VERSION ""

NS_ :

BS_:

BU_: ABS vDSU_FD_C vFD_C ECS RCU ICSC ESC RWS TPMS GW_RGW EPB FCU_C SAS EBB CGW_CCU MDPS RWA VPC_C BDC_C SFA

BO_ 234 MDPS_01_10ms: 24 SFA
 SG_ MDPS_Crc1Val : 0|16@1+ (1,0) [0|0] ""  CGW_CCU,ESC,ICSC,RCU,RWA,RWS,VPC_C
 SG_ MDPS_LoamModSta : 112|2@1+ (1,0) [0|0] ""  CGW_CCU,RWA
 SG_ MDPS_HDPSpprtSWVer : 114|5@1+ (1,0) [0|0] ""  CGW_CCU,RWA
 SG_ MDPS_ADASAciActvSta : 120|4@1+ (1,0) [0|0] ""  CGW_CCU,ESC,RWA,RWS
 SG_ MDPS_ADASAciPluginSta : 124|2@1+ (1,0) [0|0] ""  RWA
 SG_ MDPS_ADAS_AciFltSig : 126|2@1+ (1,0) [0|0] ""  CGW_CCU,ESC,RWA
 SG_ MDPS_EstStrAnglVal : 128|16@1- (0.1,0) [0|0] "Deg"  CGW_CCU,RWA,RWS
 SG_ MDPS_ADASAciActvSta_Lv2 : 144|4@1+ (1,0) [0|0] ""  CGW_CCU,RWA
 SG_ MDPS_ADAS_AciFltSig_Lv2 : 148|3@1+ (1,0) [0|0] ""  CGW_CCU,RWA
 SG_ MDPS_TpaPlugInSta : 152|2@1+ (1,0) [0|0] ""  RWA,VPC_C
 SG_ MDPS_TpaCanfltSta : 154|2@1+ (1,0) [0|0] ""  RWA,VPC_C
 SG_ MDPS_TpaModeSta : 156|4@1+ (1,0) [0|0] ""  RWA,VPC_C
 SG_ MDPS_AlvCnt1Val : 16|8@1+ (1,0) [0|0] ""  CGW_CCU,ESC,ICSC,RCU,RWA,RWS,VPC_C
 SG_ MDPS_TpaStrAnglVal : 160|16@1- (0.1,0) [0|0] "Deg"  RWA,VPC_C
 SG_ MDPS_WrngLmpSta : 24|3@1+ (1,0) [0|0] ""  CGW_CCU,ESC,ICSC,RCU,RWA,RWS
 SG_ MDPS_Typ : 27|3@1+ (1,0) [0|0] ""  CGW_CCU,ICSC,RWA
 SG_ MDPS_EngIdleRpmReq : 30|2@1+ (1,0) [0|0] ""  CGW_CCU,RWA
 SG_ MDPS_VsmPlgInSta : 32|2@1+ (1,0) [0|0] "flag"  ESC,ICSC,RCU,RWA
 SG_ MDPS_VsmDfctvSta : 34|2@1+ (1,0) [0|0] ""  ESC,ICSC,RCU,RWA
 SG_ MDPS_VsmSigErrSta : 36|2@1+ (1,0) [0|0] ""  ESC,RCU,RWA
 SG_ MDPS_PaPlugInSta : 38|2@1+ (1,0) [0|0] ""  CGW_CCU,ESC,RCU,RWA
 SG_ MDPS_PaModeSta : 40|4@1+ (1,0) [0|0] ""  CGW_CCU,RWA
 SG_ MDPS_PaCanfltSta : 44|2@1+ (1,0) [0|0] ""  CGW_CCU,RWA
 SG_ MDPS_LkaPlgInSta : 46|2@1+ (1,0) [0|0] ""  CGW_CCU,ICSC,RWA
 SG_ MDPS_LkaToiActvSta : 48|2@1+ (1,0) [0|0] ""  CGW_CCU,RWA
 SG_ MDPS_LkaToiUnblSta : 50|2@1+ (1,0) [0|0] ""  CGW_CCU,RWA
 SG_ MDPS_LkaToiFltSta : 52|2@1+ (1,0) [0|0] ""  CGW_CCU,RWA
 SG_ MDPS_LkaFailSta : 54|2@1+ (1,0) [0|0] ""  CGW_CCU,RWA
 SG_ MDPS_ResetOpSta : 59|2@1+ (1,0) [0|0] "" Vector__XXX
 SG_ MDPS_CurrModVal : 61|3@1+ (1,0) [0|0] ""  CGW_CCU,RWA
 SG_ MDPS_OutTqVal : 64|12@1+ (0.1,-204.8) [0|0] "Nm"  CGW_CCU,ESC,ICSC,RCU,RWA
 SG_ MDPS_VsmActResp : 76|2@1+ (1,0) [0|0] ""  ESC,RCU,RWA
 SG_ Reprogram_State_MDPS : 78|2@1+ (1,0) [0|0] ""  CGW_CCU
 SG_ MDPS_StrTqSnsrVal : 80|13@1+ (0.005,-20.48) [0|0] "Nm"  CGW_CCU,ESC,ICSC,RCU,RWA,VPC_C
 SG_ MDPS_PaStrAnglVal : 96|16@1- (0.1,0) [0|0] "Deg"  CGW_CCU,RWA

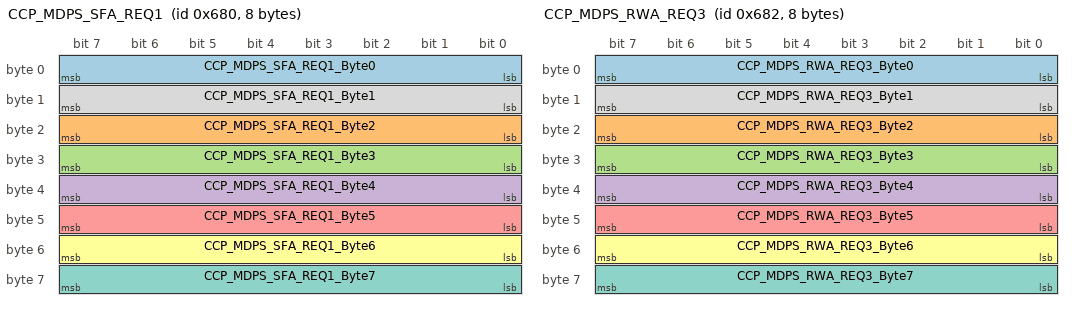
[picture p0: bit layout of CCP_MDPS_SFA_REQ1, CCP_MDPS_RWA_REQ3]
BO_ 1664 CCP_MDPS_SFA_REQ1: 8 CGW_CCU
 SG_ CCP_MDPS_SFA_REQ1_Byte0 : 0|8@1+ (1,0) [0|0] ""  GW_RGW,MDPS,SFA
 SG_ CCP_MDPS_SFA_REQ1_Byte2 : 16|8@1+ (1,0) [0|0] ""  GW_RGW,MDPS,SFA
 SG_ CCP_MDPS_SFA_REQ1_Byte3 : 24|8@1+ (1,0) [0|0] ""  GW_RGW,MDPS,SFA
 SG_ CCP_MDPS_SFA_REQ1_Byte4 : 32|8@1+ (1,0) [0|0] ""  GW_RGW,MDPS,SFA
 SG_ CCP_MDPS_SFA_REQ1_Byte5 : 40|8@1+ (1,0) [0|0] ""  GW_RGW,MDPS,SFA
 SG_ CCP_MDPS_SFA_REQ1_Byte6 : 48|8@1+ (1,0) [0|0] ""  GW_RGW,MDPS,SFA
 SG_ CCP_MDPS_SFA_REQ1_Byte7 : 56|8@1+ (1,0) [0|0] ""  GW_RGW,MDPS,SFA
 SG_ CCP_MDPS_SFA_REQ1_Byte1 : 8|8@1+ (1,0) [0|0] ""  GW_RGW,MDPS,SFA

BO_ 1666 CCP_MDPS_RWA_REQ3: 8 CGW_CCU
 SG_ CCP_MDPS_RWA_REQ3_Byte0 : 0|8@1+ (1,0) [0|0] ""  GW_RGW,MDPS,RWA
 SG_ CCP_MDPS_RWA_REQ3_Byte2 : 16|8@1+ (1,0) [0|0] ""  GW_RGW,MDPS,RWA
 SG_ CCP_MDPS_RWA_REQ3_Byte3 : 24|8@1+ (1,0) [0|0] ""  GW_RGW,MDPS,RWA
 SG_ CCP_MDPS_RWA_REQ3_Byte4 : 32|8@1+ (1,0) [0|0] ""  GW_RGW,MDPS,RWA
 SG_ CCP_MDPS_RWA_REQ3_Byte5 : 40|8@1+ (1,0) [0|0] ""  GW_RGW,MDPS,RWA
 SG_ CCP_MDPS_RWA_REQ3_Byte6 : 48|8@1+ (1,0) [0|0] ""  GW_RGW,MDPS,RWA
 SG_ CCP_MDPS_RWA_REQ3_Byte7 : 56|8@1+ (1,0) [0|0] ""  GW_RGW,MDPS,RWA
 SG_ CCP_MDPS_RWA_REQ3_Byte1 : 8|8@1+ (1,0) [0|0] ""  GW_RGW,MDPS,RWA

BO_ 266 MCU_01_10ms: 32 CGW_CCU
 SG_ MCU_Crc1Val : 0|16@1+ (1,0) [0|0] ""  MDPS,SFA
 SG_ MCU_AlvCnt1Val : 16|8@1+ (1,0) [0|0] ""  MDPS,SFA
 SG_ MCU_Mg1EstTqVal : 192|14@1- (0.125,0) [0|0] "Nm"  ECS,EPB,MDPS,SFA

BO_ 813 SBCM_DRV_FD_01_200ms: 32 CGW_CCU
 SG_ SBCM_DRV_FD_Crc1Val : 0|16@1+ (1,0) [0|0] ""  GW_RGW,RWA,RWS,SFA
 SG_ SBCM_DRV_FD_AlvCnt1Val : 16|8@1+ (1,0) [0|0] ""  GW_RGW,RWA,RWS,SFA
 SG_ Warn_DrvDrSwSta_SBCM : 84|2@1+ (1,0) [0|0] ""  ECS,EPB,ESC,GW_RGW,RCU,RWA,SFA

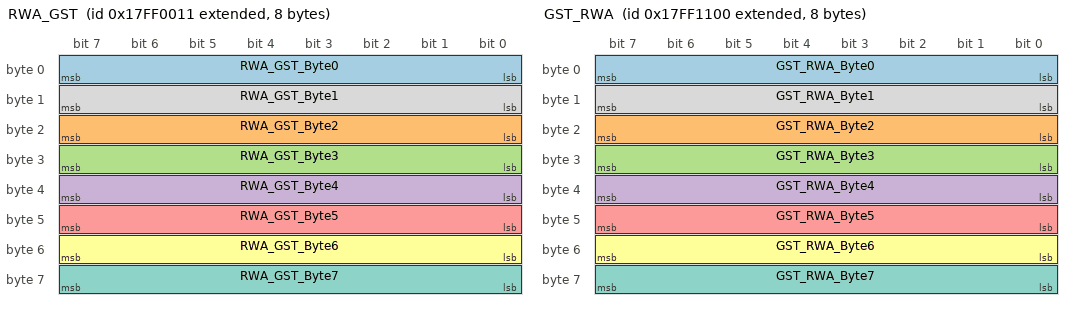
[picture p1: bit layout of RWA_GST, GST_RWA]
BO_ 2550071313 RWA_GST: 8 RWA
 SG_ RWA_GST_Byte0 : 0|8@1+ (1,0) [0|0] ""  CGW_CCU
 SG_ RWA_GST_Byte2 : 16|8@1+ (1,0) [0|0] ""  CGW_CCU
 SG_ RWA_GST_Byte3 : 24|8@1+ (1,0) [0|0] ""  CGW_CCU
 SG_ RWA_GST_Byte4 : 32|8@1+ (1,0) [0|0] ""  CGW_CCU
 SG_ RWA_GST_Byte5 : 40|8@1+ (1,0) [0|0] ""  CGW_CCU
 SG_ RWA_GST_Byte6 : 48|8@1+ (1,0) [0|0] ""  CGW_CCU
 SG_ RWA_GST_Byte7 : 56|8@1+ (1,0) [0|0] ""  CGW_CCU
 SG_ RWA_GST_Byte1 : 8|8@1+ (1,0) [0|0] ""  CGW_CCU

BO_ 811 SBCM_AST_FD_01_200ms: 32 CGW_CCU
 SG_ SBCM_AST_FD_Crc1Val : 0|16@1+ (1,0) [0|0] ""  GW_RGW,RWA,SFA
 SG_ SBCM_AST_FD_AlvCnt1Val : 16|8@1+ (1,0) [0|0] ""  GW_RGW,RWA,SFA
 SG_ Warn_AsstDrSwSta_SBCM : 84|2@1+ (1,0) [0|0] ""  ECS,GW_RGW,RWA,SFA

BO_ 288 MCU_02_10ms: 32 CGW_CCU
 SG_ MCU_Crc2Val : 0|16@1+ (1,0) [0|0] ""  SFA
 SG_ MCU_AlvCnt2Val : 16|8@1+ (1,0) [0|0] ""  SFA
 SG_ MCU_Mg2EstTqVal : 192|14@1- (0.125,0) [0|0] "Nm"  ECS,MDPS,SFA
 SG_ MCU_Mg2EstTqPcVal : 40|10@1- (0.1953125,0) [0|0] "%"  MDPS,SFA

BO_ 293 SAS_01_10ms: 16 SAS
 SG_ SAS_Crc1Val : 0|16@1+ (1,0) [0|0] ""  ABS,CGW_CCU,ECS,ESC,FCU_C,GW_RGW,ICSC,MDPS,RCU,RWA,RWS,VPC_C
 SG_ SAS_AlvCnt1Val : 16|8@1+ (1,0) [0|0] ""  ABS,CGW_CCU,ECS,ESC,FCU_C,GW_RGW,ICSC,MDPS,RCU,RWA,RWS,VPC_C
 SG_ SAS_AnglVal : 24|16@1- (0.1,0) [0|0] "Deg"  ABS,CGW_CCU,ECS,ESC,FCU_C,GW_RGW,ICSC,MDPS,RCU,RWA,RWS,VPC_C
 SG_ SAS_SpdVal : 40|8@1+ (4,0) [0|0] "Deg/s"  ABS,CGW_CCU,ECS,ESC,FCU_C,GW_RGW,ICSC,MDPS,RCU,RWA,VPC_C
 SG_ SAS_IntSta : 48|8@1+ (1,0) [0|0] ""  ABS,CGW_CCU,ECS,ESC,FCU_C,GW_RGW,MDPS,RCU,RWA,RWS,VPC_C

BO_ 2550075648 GST_RWA: 8 CGW_CCU
 SG_ GST_RWA_Byte0 : 0|8@1+ (1,0) [0|0] ""  RWA
 SG_ GST_RWA_Byte2 : 16|8@1+ (1,0) [0|0] ""  RWA
 SG_ GST_RWA_Byte3 : 24|8@1+ (1,0) [0|0] ""  RWA
 SG_ GST_RWA_Byte4 : 32|8@1+ (1,0) [0|0] ""  RWA
 SG_ GST_RWA_Byte5 : 40|8@1+ (1,0) [0|0] ""  RWA
 SG_ GST_RWA_Byte6 : 48|8@1+ (1,0) [0|0] ""  RWA
 SG_ GST_RWA_Byte7 : 56|8@1+ (1,0) [0|0] ""  RWA
 SG_ GST_RWA_Byte1 : 8|8@1+ (1,0) [0|0] ""  RWA

BO_ 298 ADAS_CMD_30_10ms: 16 CGW_CCU
 SG_ ADAS_CMD_Crc30Val : 0|16@1+ (1,0) [0|0] ""  FCU_C,GW_RGW,ICSC,MDPS,RWS,SFA,VPC_C
 SG_ ADAS_Damping_Gain : 104|8@1+ (1,0) [0|0] ""  GW_RGW,MDPS,SFA
 SG_ ADAS_CMD_AlvCnt30Val : 16|8@1+ (1,0) [0|0] ""  FCU_C,GW_RGW,ICSC,MDPS,RWS,SFA,VPC_C
 SG_ ADAS_StrTqReqVal : 41|11@1+ (0.0078125,-8) [0|0] "Nm"  GW_RGW,ICSC,MDPS,SFA
 SG_ ADAS_ActToiSta : 52|2@1+ (1,0) [0|0] ""  ESC,GW_RGW,ICSC,MDPS,RWS,SFA
 SG_ ADAS_ToiFltSta : 54|2@1+ (1,0) [0|0] ""  GW_RGW,MDPS,RWS,SFA

BO_ 374 RCU_03_20ms: 32 RCU
 SG_ RCU_Crc3Val : 0|16@1+ (1,0) [0|0] ""  CGW_CCU,GW_RGW,MDPS,SFA
 SG_ RCU_AlvCnt3Val : 16|8@1+ (1,0) [0|0] ""  CGW_CCU,GW_RGW,MDPS,SFA
 SG_ RCU_HDP_EgSta : 27|3@1+ (1,0) [0|0] ""  CGW_CCU,ESC,GW_RGW,MDPS,SFA,VPC_C

BO_ 357 ADAS_PRK_20_20ms: 24 CGW_CCU
 SG_ ADAS_PRK_Crc2Val : 0|16@1+ (1,0) [0|0] ""  GW_RGW,MDPS,RWS,SFA
 SG_ ADAS_PRK_AlvCnt2Val : 16|8@1+ (1,0) [0|0] ""  GW_RGW,MDPS,RWS,SFA
 SG_ PA_RSPA_Opt : 30|2@1+ (1,0) [0|0] ""  GW_RGW,MDPS,SFA
 SG_ PA_Sta : 90|4@1+ (1,0) [0|0] ""  ESC,GW_RGW,MDPS,RCU,RWS,SFA
 SG_ PA_TestModSta : 94|2@1+ (1,0) [0|0] ""  GW_RGW,MDPS,SFA
 SG_ PA_StrAnglReq : 96|16@1- (0.1,0) [0|0] ""  GW_RGW,MDPS,SFA

BO_ 358 CDCU_TPA_01_20ms: 16 VPC_C
 SG_ CDCU_TPA_Crc1Val : 0|16@1+ (1,0) [0|0] ""  ESC,GW_RGW,MDPS,RWS,SFA
 SG_ CDCU_TPA_AlvCnt1Val : 16|8@1+ (1,0) [0|0] ""  ESC,GW_RGW,MDPS,RWS,SFA
 SG_ CDCU_TPA_Opt : 24|2@1+ (1,0) [0|0] ""  ESC,GW_RGW,MDPS,RWS,SFA
 SG_ CDCU_TPA_Sta : 26|4@1+ (1,0) [0|0] ""  ESC,GW_RGW,MDPS,RWS,SFA
 SG_ CDCU_TPA_StrAnglReq : 30|16@1- (0.1,0) [0|0] ""  GW_RGW,MDPS,RWS,SFA

BO_ 405 ADAS_CMD_33_10ms: 32 GW_RGW
 SG_ ADAS_CMD_Crc33Val : 0|16@1+ (1,0) [0|0] ""  CGW_CCU,SFA
 SG_ HDP_RDD_StrAnglReqVal : 112|14@1- (0.1,0) [0|0] ""  SFA
 SG_ ADAS_CMD_AlvCnt33Val : 16|8@1+ (1,0) [0|0] ""  CGW_CCU,SFA
 SG_ HDP_RDD_ACIAnglTqRedcGainVal : 24|8@1+ (0.004,0) [0|0] ""  SFA
 SG_ HDP_RDD_ACIFltSta : 88|2@1+ (1,0) [0|0] ""  SFA
 SG_ HDP_RDD_ACIActvSta : 96|4@1+ (1,0) [0|0] ""  SFA

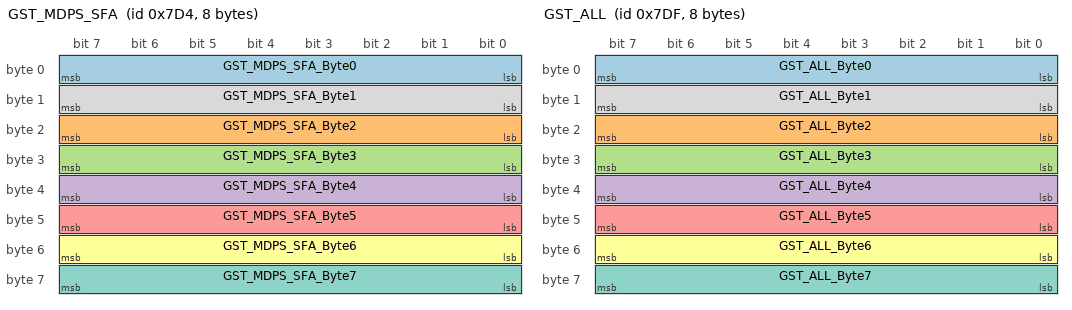
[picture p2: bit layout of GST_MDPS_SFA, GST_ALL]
BO_ 2004 GST_MDPS_SFA: 8 CGW_CCU
 SG_ GST_MDPS_SFA_Byte0 : 0|8@1+ (1,0) [0|0] ""  MDPS,SFA
 SG_ GST_MDPS_SFA_Byte2 : 16|8@1+ (1,0) [0|0] ""  MDPS,SFA
 SG_ GST_MDPS_SFA_Byte3 : 24|8@1+ (1,0) [0|0] ""  MDPS,SFA
 SG_ GST_MDPS_SFA_Byte4 : 32|8@1+ (1,0) [0|0] ""  MDPS,SFA
 SG_ GST_MDPS_SFA_Byte5 : 40|8@1+ (1,0) [0|0] ""  MDPS,SFA
 SG_ GST_MDPS_SFA_Byte6 : 48|8@1+ (1,0) [0|0] ""  MDPS,SFA
 SG_ GST_MDPS_SFA_Byte7 : 56|8@1+ (1,0) [0|0] ""  MDPS,SFA
 SG_ GST_MDPS_SFA_Byte1 : 8|8@1+ (1,0) [0|0] ""  MDPS,SFA

BO_ 2015 GST_ALL: 8 CGW_CCU
 SG_ GST_ALL_Byte0 : 0|8@1+ (1,0) [0|0] ""  ABS,EBB,ECS,EPB,ESC,GW_RGW,ICSC,MDPS,RCU,RWA,RWS,SAS,SFA,TPMS
 SG_ GST_ALL_Byte2 : 16|8@1+ (1,0) [0|0] ""  ABS,EBB,ECS,EPB,ESC,GW_RGW,ICSC,MDPS,RCU,RWA,RWS,SAS,SFA,TPMS
 SG_ GST_ALL_Byte3 : 24|8@1+ (1,0) [0|0] ""  ABS,EBB,ECS,EPB,ESC,GW_RGW,ICSC,MDPS,RCU,RWA,RWS,SAS,SFA,TPMS
 SG_ GST_ALL_Byte4 : 32|8@1+ (1,0) [0|0] ""  ABS,EBB,ECS,EPB,ESC,GW_RGW,ICSC,MDPS,RCU,RWA,RWS,SAS,SFA,TPMS
 SG_ GST_ALL_Byte5 : 40|8@1+ (1,0) [0|0] ""  ABS,EBB,ECS,EPB,ESC,GW_RGW,ICSC,MDPS,RCU,RWA,RWS,SAS,SFA,TPMS
 SG_ GST_ALL_Byte6 : 48|8@1+ (1,0) [0|0] ""  ABS,EBB,ECS,EPB,ESC,GW_RGW,ICSC,MDPS,RCU,RWA,RWS,SAS,SFA,TPMS
 SG_ GST_ALL_Byte7 : 56|8@1+ (1,0) [0|0] ""  ABS,EBB,ECS,EPB,ESC,GW_RGW,ICSC,MDPS,RCU,RWA,RWS,SAS,SFA,TPMS
 SG_ GST_ALL_Byte1 : 8|8@1+ (1,0) [0|0] ""  ABS,EBB,ECS,EPB,ESC,GW_RGW,ICSC,MDPS,RCU,RWA,RWS,SAS,SFA,TPMS

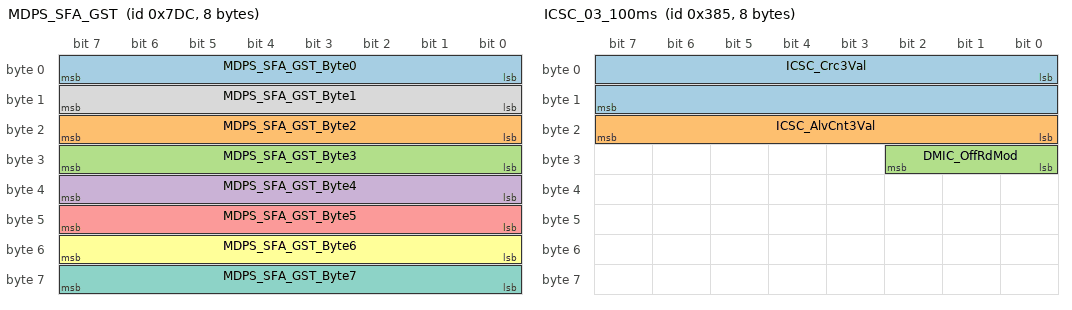
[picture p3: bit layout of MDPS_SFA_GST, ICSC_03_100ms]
BO_ 2012 MDPS_SFA_GST: 8 SFA
 SG_ MDPS_SFA_GST_Byte0 : 0|8@1+ (1,0) [0|0] ""  CGW_CCU
 SG_ MDPS_SFA_GST_Byte2 : 16|8@1+ (1,0) [0|0] ""  CGW_CCU
 SG_ MDPS_SFA_GST_Byte3 : 24|8@1+ (1,0) [0|0] ""  CGW_CCU
 SG_ MDPS_SFA_GST_Byte4 : 32|8@1+ (1,0) [0|0] ""  CGW_CCU
 SG_ MDPS_SFA_GST_Byte5 : 40|8@1+ (1,0) [0|0] ""  CGW_CCU
 SG_ MDPS_SFA_GST_Byte6 : 48|8@1+ (1,0) [0|0] ""  CGW_CCU
 SG_ MDPS_SFA_GST_Byte7 : 56|8@1+ (1,0) [0|0] ""  CGW_CCU
 SG_ MDPS_SFA_GST_Byte1 : 8|8@1+ (1,0) [0|0] ""  CGW_CCU

BO_ 426 CLU_01_20ms: 16 CGW_CCU
 SG_ CLU_Crc1Val : 0|16@1+ (1,0) [0|0] ""  ESC,GW_RGW,MDPS,RCU,RWA,SFA,VPC_C
 SG_ CLU_AlvCnt1Val : 16|8@1+ (1,0) [0|0] ""  EPB,ESC,GW_RGW,MDPS,RCU,RWA,SFA,VPC_C
 SG_ CLU_SpdUnitTyp : 30|2@1+ (1,0) [0|0] ""  ECS,ESC,GW_RGW,MDPS,RCU,RWA,SFA,VPC_C
 SG_ CLU_DisSpdVal : 48|10@1+ (0.5,0) [0|0] "km/h or MPH"  ECS,GW_RGW,MDPS,RWA,SFA,VPC_C

BO_ 901 ICSC_03_100ms: 8 ESC
 SG_ ICSC_Crc3Val : 0|16@1+ (1,0) [0|0] ""  CGW_CCU,GW_RGW,MDPS,SFA,VPC_C
 SG_ ICSC_AlvCnt3Val : 16|8@1+ (1,0) [0|0] ""  CGW_CCU,GW_RGW,MDPS,SFA,VPC_C
 SG_ DMIC_OffRdMod : 24|3@1+ (1,0) [0|0] ""  CGW_CCU,ECS,GW_RGW,MDPS,SFA,VPC_C

BO_ 994 PDC_FD_03_200ms: 16 CGW_CCU
 SG_ PDC_FD_Crc3Val : 0|16@1+ (1,0) [0|0] ""  GW_RGW,RWA,SFA
 SG_ PDC_FD_AlvCnt3Val : 16|8@1+ (1,0) [0|0] ""  GW_RGW,RWA,SFA
 SG_ Warn_DrvDrSwSta : 64|2@1+ (1,0) [0|0] ""  EPB,ESC,GW_RGW,RCU,RWA,SFA
 SG_ Warn_AsstDrSwSta : 66|2@1+ (1,0) [0|0] ""  GW_RGW,RWA,SFA
 SG_ DoorLock_DrvDrUnLkSta : 74|2@1+ (1,0) [0|0] ""  ESC,GW_RGW,RCU,RWA,SFA

BO_ 2549874807 NM_ECS: 32 ECS
 SG_ SNI_ECS : 0|8@1+ (1,0) [0|0] ""  CGW_CCU,EBB,ESC,GW_RGW,MDPS,RCU,RWA,RWS,SFA
 SG_ CBV_RMR_ECS : 8|1@1+ (1,0) [0|0] ""  CGW_CCU,EBB,ESC,GW_RGW,MDPS,RCU,RWA,RWS,SFA
 SG_ CBV_NMCoID_ECS : 9|2@1+ (1,0) [0|0] ""  CGW_CCU,EBB,ESC,GW_RGW,MDPS,RCU,RWA,RWS,SFA
 SG_ CBV_NMCoSRB_ECS : 11|1@1+ (1,0) [0|0] ""  CGW_CCU,EBB,ESC,GW_RGW,MDPS,RCU,RWA,RWS,SFA
 SG_ CBV_AWB_ECS : 12|1@1+ (1,0) [0|0] ""  CGW_CCU,EBB,ESC,GW_RGW,MDPS,RCU,RWA,RWS,SFA
 SG_ CBV_PNIB_ECS : 14|1@1+ (1,0) [0|0] ""  CGW_CCU,EBB,ESC,GW_RGW,MDPS,RCU,RWA,RWS,SFA
 SG_ NRR_ECS : 16|8@1+ (1,0) [0|0] ""  CGW_CCU,EBB,ESC,GW_RGW,MDPS,RCU,RWA,RWS,SFA
 SG_ NM_State_ECS : 24|8@1+ (1,0) [0|0] ""  CGW_CCU,EBB,ESC,GW_RGW,MDPS,RCU,RWA,RWS,SFA
 SG_ PNI_ECS : 32|32@1+ (1,0) [0|0] ""  CGW_CCU,EBB,ESC,GW_RGW,MDPS,RCU,RWA,RWS,SFA
 SG_ PNI_ECS_1 : 64|64@1+ (1,0) [0|0] ""  CGW_CCU,EBB,ESC,GW_RGW,MDPS,RCU,RWA,RWS,SFA
 SG_ PNI_ECS_2 : 128|64@1+ (1,0) [0|0] ""  CGW_CCU,EBB,ESC,GW_RGW,MDPS,RCU,RWA,RWS,SFA
 SG_ PNI_ECS_3 : 192|64@1+ (1,0) [0|0] ""  CGW_CCU,EBB,ESC,GW_RGW,MDPS,RCU,RWA,RWS,SFA

BO_ 2549874769 NM_RCU: 32 RCU
 SG_ SNI_RCU : 0|8@1+ (1,0) [0|0] ""  CGW_CCU,EBB,ECS,ESC,GW_RGW,MDPS,RWA,RWS,SFA
 SG_ CBV_RMR_RCU : 8|1@1+ (1,0) [0|0] ""  CGW_CCU,EBB,ECS,ESC,GW_RGW,MDPS,RWA,RWS,SFA
 SG_ CBV_NMCoID_RCU : 9|2@1+ (1,0) [0|0] ""  CGW_CCU,EBB,ECS,ESC,GW_RGW,MDPS,RWA,RWS,SFA
 SG_ CBV_NMCoSRB_RCU : 11|1@1+ (1,0) [0|0] ""  CGW_CCU,EBB,ECS,ESC,GW_RGW,MDPS,RWA,RWS,SFA
 SG_ CBV_AWB_RCU : 12|1@1+ (1,0) [0|0] ""  CGW_CCU,EBB,ECS,ESC,GW_RGW,MDPS,RWA,RWS,SFA
 SG_ CBV_PNIB_RCU : 14|1@1+ (1,0) [0|0] ""  CGW_CCU,EBB,ECS,ESC,GW_RGW,MDPS,RWA,RWS,SFA
 SG_ NRR_RCU : 16|8@1+ (1,0) [0|0] ""  CGW_CCU,EBB,ECS,ESC,GW_RGW,MDPS,RWA,RWS,SFA
 SG_ NM_State_RCU : 24|8@1+ (1,0) [0|0] ""  CGW_CCU,EBB,ECS,ESC,GW_RGW,MDPS,RWA,RWS,SFA
 SG_ PNI_RCU : 32|32@1+ (1,0) [0|0] ""  CGW_CCU,EBB,ECS,ESC,GW_RGW,MDPS,RWA,RWS,SFA
 SG_ PNI_RCU_1 : 64|64@1+ (1,0) [0|0] ""  CGW_CCU,EBB,ECS,ESC,GW_RGW,MDPS,RWA,RWS,SFA
 SG_ PNI_RCU_2 : 128|64@1+ (1,0) [0|0] ""  CGW_CCU,EBB,ECS,ESC,GW_RGW,MDPS,RWA,RWS,SFA
 SG_ PNI_RCU_3 : 192|64@1+ (1,0) [0|0] ""  CGW_CCU,EBB,ECS,ESC,GW_RGW,MDPS,RWA,RWS,SFA

BO_ 2549874805 NM_ESC: 32 ESC
 SG_ SNI_ESC : 0|8@1+ (1,0) [0|0] ""  CGW_CCU,EBB,ECS,GW_RGW,MDPS,RCU,RWA,RWS,SFA
 SG_ CBV_RMR_ESC : 8|1@1+ (1,0) [0|0] ""  CGW_CCU,EBB,ECS,GW_RGW,MDPS,RCU,RWA,RWS,SFA
 SG_ CBV_NMCoID_ESC : 9|2@1+ (1,0) [0|0] ""  CGW_CCU,EBB,ECS,GW_RGW,MDPS,RCU,RWA,RWS,SFA
 SG_ CBV_NMCoSRB_ESC : 11|1@1+ (1,0) [0|0] ""  CGW_CCU,EBB,ECS,GW_RGW,MDPS,RCU,RWA,RWS,SFA
 SG_ CBV_AWB_ESC : 12|1@1+ (1,0) [0|0] ""  CGW_CCU,EBB,ECS,GW_RGW,MDPS,RCU,RWA,RWS,SFA
 SG_ CBV_PNIB_ESC : 14|1@1+ (1,0) [0|0] ""  CGW_CCU,EBB,ECS,GW_RGW,MDPS,RCU,RWA,RWS,SFA
 SG_ NRR_ESC : 16|8@1+ (1,0) [0|0] ""  CGW_CCU,EBB,ECS,GW_RGW,MDPS,RCU,RWA,RWS,SFA
 SG_ NM_State_ESC : 24|8@1+ (1,0) [0|0] ""  CGW_CCU,EBB,ECS,GW_RGW,MDPS,RCU,RWA,RWS,SFA
 SG_ PNI_ESC : 32|32@1+ (1,0) [0|0] ""  CGW_CCU,EBB,ECS,GW_RGW,MDPS,RCU,RWA,RWS,SFA
 SG_ PNI_ESC_1 : 64|64@1+ (1,0) [0|0] ""  CGW_CCU,EBB,ECS,GW_RGW,MDPS,RCU,RWA,RWS,SFA
 SG_ PNI_ESC_2 : 128|64@1+ (1,0) [0|0] ""  CGW_CCU,EBB,ECS,GW_RGW,MDPS,RCU,RWA,RWS,SFA
 SG_ PNI_ESC_3 : 192|64@1+ (1,0) [0|0] ""  CGW_CCU,EBB,ECS,GW_RGW,MDPS,RCU,RWA,RWS,SFA

BO_ 2549874809 NM_RWS: 32 RWS
 SG_ SNI_RWS : 0|8@1+ (1,0) [0|0] ""  CGW_CCU,EBB,ECS,ESC,GW_RGW,MDPS,RCU,RWA,SFA
 SG_ CBV_RMR_RWS : 8|1@1+ (1,0) [0|0] ""  CGW_CCU,EBB,ECS,ESC,GW_RGW,MDPS,RCU,RWA,SFA
 SG_ CBV_NMCoID_RWS : 9|2@1+ (1,0) [0|0] ""  CGW_CCU,EBB,ECS,ESC,GW_RGW,MDPS,RCU,RWA,SFA
 SG_ CBV_NMCoSRB_RWS : 11|1@1+ (1,0) [0|0] ""  CGW_CCU,EBB,ECS,ESC,GW_RGW,MDPS,RCU,RWA,SFA
 SG_ CBV_AWB_RWS : 12|1@1+ (1,0) [0|0] ""  CGW_CCU,EBB,ECS,ESC,GW_RGW,MDPS,RCU,RWA,SFA
 SG_ CBV_PNIB_RWS : 14|1@1+ (1,0) [0|0] ""  CGW_CCU,EBB,ECS,ESC,GW_RGW,MDPS,RCU,RWA,SFA
 SG_ NRR_RWS : 16|8@1+ (1,0) [0|0] ""  CGW_CCU,EBB,ECS,ESC,GW_RGW,MDPS,RCU,RWA,SFA
 SG_ NM_State_RWS : 24|8@1+ (1,0) [0|0] ""  CGW_CCU,EBB,ECS,ESC,GW_RGW,MDPS,RCU,RWA,SFA
 SG_ PNI_RWS : 32|32@1+ (1,0) [0|0] ""  CGW_CCU,EBB,ECS,ESC,GW_RGW,MDPS,RCU,RWA,SFA
 SG_ PNI_RWS_1 : 64|64@1+ (1,0) [0|0] ""  CGW_CCU,EBB,ECS,ESC,GW_RGW,MDPS,RCU,RWA,SFA
 SG_ PNI_RWS_2 : 128|64@1+ (1,0) [0|0] ""  CGW_CCU,EBB,ECS,ESC,GW_RGW,MDPS,RCU,RWA,SFA
 SG_ PNI_RWS_3 : 192|64@1+ (1,0) [0|0] ""  CGW_CCU,EBB,ECS,ESC,GW_RGW,MDPS,RCU,RWA,SFA

BO_ 2549874751 NM_GW_RGW: 32 GW_RGW
 SG_ SNI_GW_RGW : 0|8@1+ (1,0) [0|0] ""  CGW_CCU,EBB,ECS,ESC,MDPS,RCU,RWA,RWS,SFA
 SG_ CBV_RMR_GW_RGW : 8|1@1+ (1,0) [0|0] ""  CGW_CCU,EBB,ECS,ESC,MDPS,RCU,RWA,RWS,SFA
 SG_ CBV_NMCoID_GW_RGW : 9|2@1+ (1,0) [0|0] ""  CGW_CCU,EBB,ECS,ESC,MDPS,RCU,RWA,RWS,SFA
 SG_ CBV_NMCoSRB_GW_RGW : 11|1@1+ (1,0) [0|0] ""  CGW_CCU,EBB,ECS,ESC,MDPS,RCU,RWA,RWS,SFA
 SG_ CBV_AWB_GW_RGW : 12|1@1+ (1,0) [0|0] ""  CGW_CCU,EBB,ECS,ESC,MDPS,RCU,RWA,RWS,SFA
 SG_ CBV_PNIB_GW_RGW : 14|1@1+ (1,0) [0|0] ""  CGW_CCU,EBB,ECS,ESC,MDPS,RCU,RWA,RWS,SFA
 SG_ NRR_GW_RGW : 16|8@1+ (1,0) [0|0] ""  CGW_CCU,EBB,ECS,ESC,MDPS,RCU,RWA,RWS,SFA
 SG_ NM_State_GW_RGW : 24|8@1+ (1,0) [0|0] ""  CGW_CCU,EBB,ECS,ESC,MDPS,RCU,RWA,RWS,SFA
 SG_ PNI_GW_RGW : 32|32@1+ (1,0) [0|0] ""  CGW_CCU,EBB,ECS,ESC,MDPS,RCU,RWA,RWS,SFA
 SG_ PNI_GW_RGW_1 : 64|64@1+ (1,0) [0|0] ""  CGW_CCU,EBB,ECS,ESC,MDPS,RCU,RWA,RWS,SFA
 SG_ PNI_GW_RGW_2 : 128|64@1+ (1,0) [0|0] ""  CGW_CCU,EBB,ECS,ESC,MDPS,RCU,RWA,RWS,SFA
 SG_ PNI_GW_RGW_3 : 192|64@1+ (1,0) [0|0] ""  CGW_CCU,EBB,ECS,ESC,MDPS,RCU,RWA,RWS,SFA

BO_ 2549874786 NM_EBB: 32 EBB
 SG_ SNI_EBB : 0|8@1+ (1,0) [0|0] ""  CGW_CCU,ECS,ESC,GW_RGW,MDPS,RCU,RWA,RWS,SFA
 SG_ CBV_RMR_EBB : 8|1@1+ (1,0) [0|0] ""  CGW_CCU,ECS,ESC,GW_RGW,MDPS,RCU,RWA,RWS,SFA
 SG_ CBV_NMCoID_EBB : 9|2@1+ (1,0) [0|0] ""  CGW_CCU,ECS,ESC,GW_RGW,MDPS,RCU,RWA,RWS,SFA
 SG_ CBV_NMCoSRB_EBB : 11|1@1+ (1,0) [0|0] ""  CGW_CCU,ECS,ESC,GW_RGW,MDPS,RCU,RWA,RWS,SFA
 SG_ CBV_AWB_EBB : 12|1@1+ (1,0) [0|0] ""  CGW_CCU,ECS,ESC,GW_RGW,MDPS,RCU,RWA,RWS,SFA
 SG_ CBV_PNIB_EBB : 14|1@1+ (1,0) [0|0] ""  CGW_CCU,ECS,ESC,GW_RGW,MDPS,RCU,RWA,RWS,SFA
 SG_ NRR_EBB : 16|8@1+ (1,0) [0|0] ""  CGW_CCU,ECS,ESC,GW_RGW,MDPS,RCU,RWA,RWS,SFA
 SG_ NM_State_EBB : 24|8@1+ (1,0) [0|0] ""  CGW_CCU,ECS,ESC,GW_RGW,MDPS,RCU,RWA,RWS,SFA
 SG_ PNI_EBB : 32|32@1+ (1,0) [0|0] ""  CGW_CCU,ECS,ESC,GW_RGW,MDPS,RCU,RWA,RWS,SFA
 SG_ PNI_EBB_1 : 64|64@1+ (1,0) [0|0] ""  CGW_CCU,ECS,ESC,GW_RGW,MDPS,RCU,RWA,RWS,SFA
 SG_ PNI_EBB_2 : 128|64@1+ (1,0) [0|0] ""  CGW_CCU,ECS,ESC,GW_RGW,MDPS,RCU,RWA,RWS,SFA
 SG_ PNI_EBB_3 : 192|64@1+ (1,0) [0|0] ""  CGW_CCU,ECS,ESC,GW_RGW,MDPS,RCU,RWA,RWS,SFA

BO_ 2549874800 NM_CGW_CCU: 32 CGW_CCU
 SG_ SNI_CGW_CCU : 0|8@1+ (1,0) [0|0] ""  EBB,ECS,ESC,GW_RGW,MDPS,RCU,RWA,RWS,SFA
 SG_ CBV_RMR_CGW_CCU : 8|1@1+ (1,0) [0|0] ""  EBB,ECS,ESC,GW_RGW,MDPS,RCU,RWA,RWS,SFA
 SG_ CBV_NMCoID_CGW_CCU : 9|2@1+ (1,0) [0|0] ""  EBB,ECS,ESC,GW_RGW,MDPS,RCU,RWA,RWS,SFA
 SG_ CBV_NMCoSRB_CGW_CCU : 11|1@1+ (1,0) [0|0] ""  EBB,ECS,ESC,GW_RGW,MDPS,RCU,RWA,RWS,SFA
 SG_ CBV_AWB_CGW_CCU : 12|1@1+ (1,0) [0|0] ""  EBB,ECS,ESC,GW_RGW,MDPS,RCU,RWA,RWS,SFA
 SG_ CBV_PNIB_CGW_CCU : 14|1@1+ (1,0) [0|0] ""  EBB,ECS,ESC,GW_RGW,MDPS,RCU,RWA,RWS,SFA
 SG_ NRR_CGW_CCU : 16|8@1+ (1,0) [0|0] ""  EBB,ECS,ESC,GW_RGW,MDPS,RCU,RWA,RWS,SFA
 SG_ NM_State_CGW_CCU : 24|8@1+ (1,0) [0|0] ""  EBB,ECS,ESC,GW_RGW,MDPS,RCU,RWA,RWS,SFA
 SG_ PNI_CGW_CCU : 32|32@1+ (1,0) [0|0] ""  EBB,ECS,ESC,GW_RGW,MDPS,RCU,RWA,RWS,SFA
 SG_ PNI_CGW_CCU_1 : 64|64@1+ (1,0) [0|0] ""  EBB,ECS,ESC,GW_RGW,MDPS,RCU,RWA,RWS,SFA
 SG_ PNI_CGW_CCU_2 : 128|64@1+ (1,0) [0|0] ""  EBB,ECS,ESC,GW_RGW,MDPS,RCU,RWA,RWS,SFA
 SG_ PNI_CGW_CCU_3 : 192|64@1+ (1,0) [0|0] ""  EBB,ECS,ESC,GW_RGW,MDPS,RCU,RWA,RWS,SFA

BO_ 2549874806 NM_MDPS: 32 MDPS
 SG_ SNI_MDPS : 0|8@1+ (1,0) [0|0] ""  CGW_CCU,EBB,ECS,ESC,GW_RGW,RCU,RWA,RWS,SFA
 SG_ CBV_RMR_MDPS : 8|1@1+ (1,0) [0|0] ""  CGW_CCU,EBB,ECS,ESC,GW_RGW,RCU,RWA,RWS,SFA
 SG_ CBV_NMCoID_MDPS : 9|2@1+ (1,0) [0|0] ""  CGW_CCU,EBB,ECS,ESC,GW_RGW,RCU,RWA,RWS,SFA
 SG_ CBV_NMCoSRB_MDPS : 11|1@1+ (1,0) [0|0] ""  CGW_CCU,EBB,ECS,ESC,GW_RGW,RCU,RWA,RWS,SFA
 SG_ CBV_AWB_MDPS : 12|1@1+ (1,0) [0|0] ""  CGW_CCU,EBB,ECS,ESC,GW_RGW,RCU,RWA,RWS,SFA
 SG_ CBV_PNIB_MDPS : 14|1@1+ (1,0) [0|0] ""  CGW_CCU,EBB,ECS,ESC,GW_RGW,RCU,RWA,RWS,SFA
 SG_ NRR_MDPS : 16|8@1+ (1,0) [0|0] ""  CGW_CCU,EBB,ECS,ESC,GW_RGW,RCU,RWA,RWS,SFA
 SG_ NM_State_MDPS : 24|8@1+ (1,0) [0|0] ""  CGW_CCU,EBB,ECS,ESC,GW_RGW,RCU,RWA,RWS,SFA
 SG_ PNI_MDPS : 32|32@1+ (1,0) [0|0] ""  CGW_CCU,EBB,ECS,ESC,GW_RGW,RCU,RWA,RWS,SFA
 SG_ PNI_MDPS_1 : 64|64@1+ (1,0) [0|0] ""  CGW_CCU,EBB,ECS,ESC,GW_RGW,RCU,RWA,RWS,SFA
 SG_ PNI_MDPS_2 : 128|64@1+ (1,0) [0|0] ""  CGW_CCU,EBB,ECS,ESC,GW_RGW,RCU,RWA,RWS,SFA
 SG_ PNI_MDPS_3 : 192|64@1+ (1,0) [0|0] ""  CGW_CCU,EBB,ECS,ESC,GW_RGW,RCU,RWA,RWS,SFA

BO_ 2549874762 NM_RWA: 32 RWA
 SG_ SNI_RWA : 0|8@1+ (1,0) [0|0] ""  CGW_CCU,EBB,ECS,ESC,GW_RGW,MDPS,RCU,RWS,SFA
 SG_ CBV_RMR_RWA : 8|1@1+ (1,0) [0|0] ""  CGW_CCU,EBB,ECS,ESC,GW_RGW,MDPS,RCU,RWS,SFA
 SG_ CBV_NMCoID_RWA : 9|2@1+ (1,0) [0|0] ""  CGW_CCU,EBB,ECS,ESC,GW_RGW,MDPS,RCU,RWS,SFA
 SG_ CBV_NMCoSRB_RWA : 11|1@1+ (1,0) [0|0] ""  CGW_CCU,EBB,ECS,ESC,GW_RGW,MDPS,RCU,RWS,SFA
 SG_ CBV_AWB_RWA : 12|1@1+ (1,0) [0|0] ""  CGW_CCU,EBB,ECS,ESC,GW_RGW,MDPS,RCU,RWS,SFA
 SG_ CBV_PNIB_RWA : 14|1@1+ (1,0) [0|0] ""  CGW_CCU,EBB,ECS,ESC,GW_RGW,MDPS,RCU,RWS,SFA
 SG_ NRR_RWA : 16|8@1+ (1,0) [0|0] ""  CGW_CCU,EBB,ECS,ESC,GW_RGW,MDPS,RCU,RWS,SFA
 SG_ NM_State_RWA : 24|8@1+ (1,0) [0|0] ""  CGW_CCU,EBB,ECS,ESC,GW_RGW,MDPS,RCU,RWS,SFA
 SG_ PNI_RWA : 32|32@1+ (1,0) [0|0] ""  CGW_CCU,EBB,ECS,ESC,GW_RGW,MDPS,RCU,RWS,SFA
 SG_ PNI_RWA_1 : 64|64@1+ (1,0) [0|0] ""  CGW_CCU,EBB,ECS,ESC,GW_RGW,MDPS,RCU,RWS,SFA
 SG_ PNI_RWA_2 : 128|64@1+ (1,0) [0|0] ""  CGW_CCU,EBB,ECS,ESC,GW_RGW,MDPS,RCU,RWS,SFA
 SG_ PNI_RWA_3 : 192|64@1+ (1,0) [0|0] ""  CGW_CCU,EBB,ECS,ESC,GW_RGW,MDPS,RCU,RWS,SFA

BO_ 2549874746 NM_SFA: 32 SFA
 SG_ SNI_SFA : 0|8@1+ (1,0) [0|0] ""  CGW_CCU,EBB,ECS,ESC,GW_RGW,MDPS,RCU,RWA,RWS
 SG_ CBV_RMR_SFA : 8|1@1+ (1,0) [0|0] ""  CGW_CCU,EBB,ECS,ESC,GW_RGW,MDPS,RCU,RWA,RWS
 SG_ CBV_NMCoID_SFA : 9|2@1+ (1,0) [0|0] ""  CGW_CCU,EBB,ECS,ESC,GW_RGW,MDPS,RCU,RWA,RWS
 SG_ CBV_NMCoSRB_SFA : 11|1@1+ (1,0) [0|0] ""  CGW_CCU,EBB,ECS,ESC,GW_RGW,MDPS,RCU,RWA,RWS
 SG_ CBV_AWB_SFA : 12|1@1+ (1,0) [0|0] ""  CGW_CCU,EBB,ECS,ESC,GW_RGW,MDPS,RCU,RWA,RWS
 SG_ CBV_PNIB_SFA : 14|1@1+ (1,0) [0|0] ""  CGW_CCU,EBB,ECS,ESC,GW_RGW,MDPS,RCU,RWA,RWS
 SG_ NRR_SFA : 16|8@1+ (1,0) [0|0] ""  CGW_CCU,EBB,ECS,ESC,GW_RGW,MDPS,RCU,RWA,RWS
 SG_ NM_State_SFA : 24|8@1+ (1,0) [0|0] ""  CGW_CCU,EBB,ECS,ESC,GW_RGW,MDPS,RCU,RWA,RWS
 SG_ PNI_SFA : 32|32@1+ (1,0) [0|0] ""  CGW_CCU,EBB,ECS,ESC,GW_RGW,MDPS,RCU,RWA,RWS
 SG_ PNI_SFA_1 : 64|64@1+ (1,0) [0|0] ""  CGW_CCU,EBB,ECS,ESC,GW_RGW,MDPS,RCU,RWA,RWS
 SG_ PNI_SFA_2 : 128|64@1+ (1,0) [0|0] ""  CGW_CCU,EBB,ECS,ESC,GW_RGW,MDPS,RCU,RWA,RWS
 SG_ PNI_SFA_3 : 192|64@1+ (1,0) [0|0] ""  CGW_CCU,EBB,ECS,ESC,GW_RGW,MDPS,RCU,RWA,RWS

BO_TX_BU_ 234 : SFA,MDPS;
BO_TX_BU_ 293 : SAS,MDPS,SFA;
BO_TX_BU_ 2012 : SFA,MDPS;
BO_TX_BU_ 901 : ESC,ICSC;
CM_ BO_ 234 "[P] Periodic";
CM_ SG_ 234 MDPS_Crc1Val "MDPS_CyclicRedundancyCheck1Value ##2G##MDPS - MDPS11 - CF_Mdps_Chksum";
CM_ SG_ 234 MDPS_LoamModSta "MDPS_LoamModeStatus ##2G##MDPS - MDPS11 - CF_Mdps_Loam_Flag";
CM_ SG_ 234 MDPS_HDPSpprtSWVer "HDP-MDPS Control Requirement Spec Version";
CM_ SG_ 234 MDPS_ADASAciActvSta "States for angle control";
CM_ SG_ 234 MDPS_ADASAciPluginSta "ADASAci(HDP) function Plug-in state";
CM_ SG_ 234 MDPS_ADAS_AciFltSig "MDPS fault Status for HDP";
CM_ SG_ 234 MDPS_EstStrAnglVal "MDPS_EstStrAnglVal";
CM_ SG_ 234 MDPS_ADASAciActvSta_Lv2 "States for angle control (LV2)";
CM_ SG_ 234 MDPS_ADAS_AciFltSig_Lv2 "MDPS Fault Status for LV2 Angle Control Function";
CM_ SG_ 234 MDPS_TpaPlugInSta "MDPS_TpaPlugInStatus ##2G##MDPS - MDPS11 - CF_Mdps_TPA_FUNC";
CM_ SG_ 234 MDPS_TpaCanfltSta "MDPS_TpaCanFaultStatus ##2G##MDPS - MDPS11 - CF_MDPS_TPACanfailflag";
CM_ SG_ 234 MDPS_TpaModeSta "MDPS_TpaModeStatus ##2G##MDPS - MDPS11 - CF_Mdps_Stat";
CM_ SG_ 234 MDPS_AlvCnt1Val "MDPS_AliveCounter1Value ##2G##MDPS - MDPS11 - CF_Mdps_AliveCnt";
CM_ SG_ 234 MDPS_TpaStrAnglVal "MDPS_TpaSteeringAngleValue ##2G##MDPS - MDPS11 - CR_Mdps_StrAng";
CM_ SG_ 234 MDPS_WrngLmpSta "MDPS_WarningLampStatus ##2G##MDPS - MDPS11 - CF_Mdps_WLmp";
CM_ SG_ 234 MDPS_Typ "MDPS_Type ##2G##MDPS - MDPS11 - CF_Mdps_Type";
CM_ SG_ 234 MDPS_EngIdleRpmReq "MDPS_EngineIdleRpmRequest ##2G##MDPS - MDPS11 - CF_Mdps_ALTRequest";
CM_ SG_ 234 MDPS_VsmPlgInSta "MDPS_VsmPluginStatus ##2G##MDPS - MDPS11 - CF_Mdps_VSM_FUNC";
CM_ SG_ 234 MDPS_VsmDfctvSta "MDPS_VsmDefectiveStatus ##2G##MDPS - MDPS12 - CF_Mdps_Def";
CM_ SG_ 234 MDPS_VsmSigErrSta "MDPS_VsmSignalErrorStatus ##2G##MDPS - MDPS12 - CF_Mdps_SErr";
CM_ SG_ 234 MDPS_PaPlugInSta "MDPS_PaPlugInStatus ##2G##MDPS - MDPS11 - CF_Mdps_PA_FUNC";
CM_ SG_ 234 MDPS_PaModeSta "MDPS_PaModeStatus ##2G##MDPS - MDPS11 - CF_Mdps_Stat";
CM_ SG_ 234 MDPS_PaCanfltSta "MDPS_PaCanFaultStatus ##2G##MDPS - MDPS11 - CF_MDPS_PACanfailflag";
CM_ SG_ 234 MDPS_LkaPlgInSta "MDPS_LkaPlug-inStatus ##2G##MDPS - MDPS11 - CF_Mdps_LKA_FUNC";
CM_ SG_ 234 MDPS_LkaToiActvSta "MDPS_LkaToiActiveStatus ##2G##MDPS - MDPS12 - CF_Mdps_ToiActive";
CM_ SG_ 234 MDPS_LkaToiUnblSta "MDPS_LkaToiUnavailableStatus ##2G##MDPS - MDPS12 - CF_Mdps_ToiUnavail";
CM_ SG_ 234 MDPS_LkaToiFltSta "MDPS_LkaToiFaultStatus ##2G##MDPS - MDPS12 - CF_Mdps_ToiFlt";
CM_ SG_ 234 MDPS_LkaFailSta "MDPS_LkaFailStatus ##2G##MDPS - MDPS12 - CF_Mdps_FailStat";
CM_ SG_ 234 MDPS_ResetOpSta "0x0 Normal 0x1 Reset Complete 0x2 Reset Fail 0x3 Reserved";
CM_ SG_ 234 MDPS_CurrModVal "MDPS_CurrentModeStatus ##2G##MDPS - MDPS11 - CF_Mdps_CurrMode";
CM_ SG_ 234 MDPS_OutTqVal "MDPS_OutputTorqueValue ##2G##MDPS - MDPS12 - CR_Mdps_OutTq";
CM_ SG_ 234 MDPS_VsmActResp "Information of VSM Tqrque Intervention Act Response";
CM_ SG_ 234 Reprogram_State_MDPS "0x0: normal operation 0x1: reprogramming 0x2: reserved 0x3: Error Indicator";
CM_ SG_ 234 MDPS_StrTqSnsrVal "MDPS_SteeringTorqueSensorValue ##2G##MDPS - MDPS11 - CR_Mdps_DrvTq,MDPS12-CR_Mdps_StrTq,CR_Mdps_StrColTq";
CM_ SG_ 234 MDPS_PaStrAnglVal "MDPS_PaSteeringAngleValue ##2G##MDPS - MDPS11 - CR_Mdps_StrAng";
CM_ BO_ 1664 "[EW] On Event and On Write";
CM_ BO_ 1666 "[EW] On Event and On Write";
CM_ BO_ 266 "[P] Periodic";
CM_ SG_ 266 MCU_Crc1Val "MCU_CyclicRedundancyCheck1Value";
CM_ SG_ 266 MCU_AlvCnt1Val "MCU_AliveCounter1Value";
CM_ SG_ 266 MCU_Mg1EstTqVal "MCU_Mg1EstimatedTorqueValue";
CM_ BO_ 813 "[PE] Periodic and On Event";
CM_ SG_ 813 SBCM_DRV_FD_Crc1Val "SBCM_DRV_FD_CyclicRedundancyCheck1Value";
CM_ SG_ 813 SBCM_DRV_FD_AlvCnt1Val "SBCM_DRV_FD_AliveCounter1Value";
CM_ SG_ 813 Warn_DrvDrSwSta_SBCM "DoorLock_DriverDoorSwitchStatus ##2G## -  - C_DrvDrSw,CF_Gway_DrvDrSw,Warn_DrvDrSwSta";
CM_ BO_ 2550071313 "[TP] Transport Protocol";
CM_ BO_ 811 "[PE] Periodic and On Event";
CM_ SG_ 811 SBCM_AST_FD_Crc1Val "SBCM_AST_FD_CyclicRedundancyCheck1Value";
CM_ SG_ 811 SBCM_AST_FD_AlvCnt1Val "SBCM_AST_FD_AliveCounter1Value";
CM_ SG_ 811 Warn_AsstDrSwSta_SBCM "Warn_AssistDoorSwitchStatus ##2G## -  - C_AstDrSw,CF_Gway_AstDrSw,Warn_AsstDrSwSta";
CM_ BO_ 288 "[P] Periodic";
CM_ SG_ 288 MCU_Crc2Val "MCU_CyclicRedundancyCheck2Value";
CM_ SG_ 288 MCU_AlvCnt2Val "MCU_AliveCounter2Value";
CM_ SG_ 288 MCU_Mg2EstTqVal "MCU_EstimatedMg2TorqueValue";
CM_ SG_ 288 MCU_Mg2EstTqPcVal "MCU_EstimatedMg2TorquePcValue";
CM_ BO_ 293 "[P] Periodic";
CM_ SG_ 293 SAS_Crc1Val "SAS_CyclicRedundancyCheck1Value";
CM_ SG_ 293 SAS_AlvCnt1Val "SAS_AliveCounter1Value";
CM_ SG_ 293 SAS_AnglVal "SAS_AngleValue";
CM_ SG_ 293 SAS_SpdVal "SAS_SpeedValue";
CM_ SG_ 293 SAS_IntSta "SAS_InternalStatus";
CM_ BO_ 2550075648 "[TP] Transport Protocol";
CM_ BO_ 298 "[P] Periodic";
CM_ SG_ 298 ADAS_CMD_Crc30Val "ADAS_CMD_CyclicRedundancyCheck30Value";
CM_ SG_ 298 ADAS_Damping_Gain "ADAS_Damping_Gain";
CM_ SG_ 298 ADAS_CMD_AlvCnt30Val "ADAS_CMD_AliveCounter30Value";
CM_ SG_ 298 ADAS_StrTqReqVal "LKA_SteeringTorqueRequestValue ##2G##LDW_LKA - LKA11 - CR_LKA_StrToqReq";
CM_ SG_ 298 ADAS_ActToiSta "ADAS_ActiveTorqueOverlayInterfaceStatus ##2G##LDW_LKA - LKA11 - CF_LKA_ActToi";
CM_ SG_ 298 ADAS_ToiFltSta "ADAS_TorqueOverlayInterfaceFaultStatus ##2G##LDW_LKA - LKA11 - CF_LKA_ToiFlt";
CM_ BO_ 374 "[P] Periodic";
CM_ SG_ 374 RCU_Crc3Val "RCU_CyclicRedundancyCheck3Value";
CM_ SG_ 374 RCU_AlvCnt3Val "RCU_AliveCounter3Value";
CM_ SG_ 374 RCU_HDP_EgSta "RCU_HDP_EngagedStatus";
CM_ BO_ 357 "[P] Periodic";
CM_ SG_ 357 ADAS_PRK_Crc2Val "ADAS_PRK_CyclicRedundancyCheck2Value";
CM_ SG_ 357 ADAS_PRK_AlvCnt2Val "ADAS_PRK_AliveCounter2Value";
CM_ SG_ 357 PA_Sta "PA_Status";
CM_ SG_ 357 PA_TestModSta "PA_TestModeStatus";
CM_ SG_ 357 PA_StrAnglReq "PA_SteeringAngleRequest";
CM_ BO_ 358 "[P] Periodic";
CM_ SG_ 358 CDCU_TPA_Crc1Val "CDCU_TPA_CyclicRedundancyCheck1Value";
CM_ SG_ 358 CDCU_TPA_AlvCnt1Val "CDCU_TPA_AliveCounter1Value";
CM_ SG_ 358 CDCU_TPA_Opt "TPA_Option";
CM_ SG_ 358 CDCU_TPA_Sta "TPA_Status";
CM_ SG_ 358 CDCU_TPA_StrAnglReq "CDCU_TPA_SteeringAngleRequest";
CM_ BO_ 405 "[P] Periodic";
CM_ SG_ 405 HDP_RDD_StrAnglReqVal "HDP_RDD Steering Angle Request Value";
CM_ SG_ 405 HDP_RDD_ACIAnglTqRedcGainVal "HDP_RDD AngleControlInterface Angle Torque Reduction Gain Value";
CM_ SG_ 405 HDP_RDD_ACIFltSta "HDP_RDD AngleControlInterface Fault State";
CM_ SG_ 405 HDP_RDD_ACIActvSta "HDP_RDD AngleControlInterface Active State";
CM_ BO_ 2004 "[TP] Transport Protocol";
CM_ BO_ 2015 "[TP] Transport Protocol";
CM_ BO_ 2012 "[TP] Transport Protocol";
CM_ BO_ 426 "[P] Periodic";
CM_ SG_ 426 CLU_Crc1Val "CLU_CyclicRedundancyCheck1Value";
CM_ SG_ 426 CLU_AlvCnt1Val "CLU_AliveCounter1Value";
CM_ SG_ 426 CLU_SpdUnitTyp "CLU_SpeedUnitType";
CM_ SG_ 426 CLU_DisSpdVal "CLU_DisplaySpeedValue";
CM_ BO_ 901 "[P] Periodic";
CM_ SG_ 901 ICSC_Crc3Val "ICSC_CyclicRedundancyCheck3Value";
CM_ SG_ 901 ICSC_AlvCnt3Val "ICSC_AliveCounter3Value";
CM_ SG_ 901 DMIC_OffRdMod "DMIC_OffRoadMode";
CM_ BO_ 994 "[PE] Periodic and On Event";
CM_ SG_ 994 PDC_FD_Crc3Val "PDC_FD_CyclicRedundancyCheck3Value";
CM_ SG_ 994 PDC_FD_AlvCnt3Val "PDC_FD_AliveCounter3Value";
CM_ SG_ 994 Warn_DrvDrSwSta "DoorLock_DriverDoorSwitchStatus ##2G## -  - C_DrvDrSw,CF_Gway_DrvDrSw,Warn_DrvDrSwSta";
CM_ SG_ 994 Warn_AsstDrSwSta "Warn_AssistDoorSwitchStatus ##2G## -  - C_AstDrSw,CF_Gway_AstDrSw,Warn_AsstDrSwSta";
CM_ SG_ 994 DoorLock_DrvDrUnLkSta "DoorLock_DriverDoorUnLockStatus ##2G## -  - C_DrvUnlockState,CF_Gway_DrvUnlockState";
CM_ SG_ 2549874807 SNI_ECS "ASR NM Source Node Identifier";
CM_ SG_ 2549874807 CBV_RMR_ECS "ASR NM Control Bit Vector - Repeat Message Request";
CM_ SG_ 2549874807 CBV_NMCoID_ECS "ASR NM Control Bit Vector - ASR NM Coordinator ID";
CM_ SG_ 2549874807 CBV_NMCoSRB_ECS "ASR NM Control Bit Vector - ASR NM Coordinator Sleep Ready Bit";
CM_ SG_ 2549874807 CBV_AWB_ECS "ASR NM Control Bit Vector - Active Wakeup Bit";
CM_ SG_ 2549874807 CBV_PNIB_ECS "ASR NM Control Bit Vector - PN Info Bit";
CM_ SG_ 2549874807 NRR_ECS "ASR NM Network Request Reason";
CM_ SG_ 2549874807 NM_State_ECS "ASR NM State_Current State_Previous State";
CM_ SG_ 2549874807 PNI_ECS "ASR NM Partial Networking Information";
CM_ SG_ 2549874807 PNI_ECS_1 "ASR NM Partial Networking Information";
CM_ SG_ 2549874807 PNI_ECS_2 "ASR NM Partial Networking Information";
CM_ SG_ 2549874807 PNI_ECS_3 "ASR NM Partial Networking Information";
CM_ SG_ 2549874769 SNI_RCU "ASR NM Source Node Identifier";
CM_ SG_ 2549874769 CBV_RMR_RCU "ASR NM Control Bit Vector - Repeat Message Request";
CM_ SG_ 2549874769 CBV_NMCoID_RCU "ASR NM Control Bit Vector - ASR NM Coordinator ID";
CM_ SG_ 2549874769 CBV_NMCoSRB_RCU "ASR NM Control Bit Vector - ASR NM Coordinator Sleep Ready Bit";
CM_ SG_ 2549874769 CBV_AWB_RCU "ASR NM Control Bit Vector - Active Wakeup Bit";
CM_ SG_ 2549874769 CBV_PNIB_RCU "ASR NM Control Bit Vector - PN Info Bit";
CM_ SG_ 2549874769 NRR_RCU "ASR NM Network Request Reason";
CM_ SG_ 2549874769 NM_State_RCU "ASR NM State_Current State_Previous State";
CM_ SG_ 2549874769 PNI_RCU "ASR NM Partial Networking Information";
CM_ SG_ 2549874769 PNI_RCU_1 "ASR NM Partial Networking Information";
CM_ SG_ 2549874769 PNI_RCU_2 "ASR NM Partial Networking Information";
CM_ SG_ 2549874769 PNI_RCU_3 "ASR NM Partial Networking Information";
CM_ SG_ 2549874805 SNI_ESC "ASR NM Source Node Identifier";
CM_ SG_ 2549874805 CBV_RMR_ESC "ASR NM Control Bit Vector - Repeat Message Request";
CM_ SG_ 2549874805 CBV_NMCoID_ESC "ASR NM Control Bit Vector - ASR NM Coordinator ID";
CM_ SG_ 2549874805 CBV_NMCoSRB_ESC "ASR NM Control Bit Vector - ASR NM Coordinator Sleep Ready Bit";
CM_ SG_ 2549874805 CBV_AWB_ESC "ASR NM Control Bit Vector - Active Wakeup Bit";
CM_ SG_ 2549874805 CBV_PNIB_ESC "ASR NM Control Bit Vector - PN Info Bit";
CM_ SG_ 2549874805 NRR_ESC "ASR NM Network Request Reason";
CM_ SG_ 2549874805 NM_State_ESC "ASR NM State_Current State_Previous State";
CM_ SG_ 2549874805 PNI_ESC "ASR NM Partial Networking Information";
CM_ SG_ 2549874805 PNI_ESC_1 "ASR NM Partial Networking Information";
CM_ SG_ 2549874805 PNI_ESC_2 "ASR NM Partial Networking Information";
CM_ SG_ 2549874805 PNI_ESC_3 "ASR NM Partial Networking Information";
CM_ SG_ 2549874809 SNI_RWS "ASR NM Source Node Identifier";
CM_ SG_ 2549874809 CBV_RMR_RWS "ASR NM Control Bit Vector - Repeat Message Request";
CM_ SG_ 2549874809 CBV_NMCoID_RWS "ASR NM Control Bit Vector - ASR NM Coordinator ID";
CM_ SG_ 2549874809 CBV_NMCoSRB_RWS "ASR NM Control Bit Vector - ASR NM Coordinator Sleep Ready Bit";
CM_ SG_ 2549874809 CBV_AWB_RWS "ASR NM Control Bit Vector - Active Wakeup Bit";
CM_ SG_ 2549874809 CBV_PNIB_RWS "ASR NM Control Bit Vector - PN Info Bit";
CM_ SG_ 2549874809 NRR_RWS "ASR NM Network Request Reason";
CM_ SG_ 2549874809 NM_State_RWS "ASR NM State_Current State_Previous State";
CM_ SG_ 2549874809 PNI_RWS "ASR NM Partial Networking Information";
CM_ SG_ 2549874809 PNI_RWS_1 "ASR NM Partial Networking Information";
CM_ SG_ 2549874809 PNI_RWS_2 "ASR NM Partial Networking Information";
CM_ SG_ 2549874809 PNI_RWS_3 "ASR NM Partial Networking Information";
CM_ SG_ 2549874751 SNI_GW_RGW "ASR NM Source Node Identifier";
CM_ SG_ 2549874751 CBV_RMR_GW_RGW "ASR NM Control Bit Vector - Repeat Message Request";
CM_ SG_ 2549874751 CBV_NMCoID_GW_RGW "ASR NM Control Bit Vector - ASR NM Coordinator ID";
CM_ SG_ 2549874751 CBV_NMCoSRB_GW_RGW "ASR NM Control Bit Vector - ASR NM Coordinator Sleep Ready Bit";
CM_ SG_ 2549874751 CBV_AWB_GW_RGW "ASR NM Control Bit Vector - Active Wakeup Bit";
CM_ SG_ 2549874751 CBV_PNIB_GW_RGW "ASR NM Control Bit Vector - PN Info Bit";
CM_ SG_ 2549874751 NRR_GW_RGW "ASR NM Network Request Reason";
CM_ SG_ 2549874751 NM_State_GW_RGW "ASR NM State_Current State_Previous State";
CM_ SG_ 2549874751 PNI_GW_RGW "ASR NM Partial Networking Information";
CM_ SG_ 2549874751 PNI_GW_RGW_1 "ASR NM Partial Networking Information";
CM_ SG_ 2549874751 PNI_GW_RGW_2 "ASR NM Partial Networking Information";
CM_ SG_ 2549874751 PNI_GW_RGW_3 "ASR NM Partial Networking Information";
CM_ SG_ 2549874786 SNI_EBB "ASR NM Source Node Identifier";
CM_ SG_ 2549874786 CBV_RMR_EBB "ASR NM Control Bit Vector - Repeat Message Request";
CM_ SG_ 2549874786 CBV_NMCoID_EBB "ASR NM Control Bit Vector - ASR NM Coordinator ID";
CM_ SG_ 2549874786 CBV_NMCoSRB_EBB "ASR NM Control Bit Vector - ASR NM Coordinator Sleep Ready Bit";
CM_ SG_ 2549874786 CBV_AWB_EBB "ASR NM Control Bit Vector - Active Wakeup Bit";
CM_ SG_ 2549874786 CBV_PNIB_EBB "ASR NM Control Bit Vector - PN Info Bit";
CM_ SG_ 2549874786 NRR_EBB "ASR NM Network Request Reason";
CM_ SG_ 2549874786 NM_State_EBB "ASR NM State_Current State_Previous State";
CM_ SG_ 2549874786 PNI_EBB "ASR NM Partial Networking Information";
CM_ SG_ 2549874786 PNI_EBB_1 "ASR NM Partial Networking Information";
CM_ SG_ 2549874786 PNI_EBB_2 "ASR NM Partial Networking Information";
CM_ SG_ 2549874786 PNI_EBB_3 "ASR NM Partial Networking Information";
CM_ SG_ 2549874800 SNI_CGW_CCU "ASR NM Source Node Identifier";
CM_ SG_ 2549874800 CBV_RMR_CGW_CCU "ASR NM Control Bit Vector - Repeat Message Request";
CM_ SG_ 2549874800 CBV_NMCoID_CGW_CCU "ASR NM Control Bit Vector - ASR NM Coordinator ID";
CM_ SG_ 2549874800 CBV_NMCoSRB_CGW_CCU "ASR NM Control Bit Vector - ASR NM Coordinator Sleep Ready Bit";
CM_ SG_ 2549874800 CBV_AWB_CGW_CCU "ASR NM Control Bit Vector - Active Wakeup Bit";
CM_ SG_ 2549874800 CBV_PNIB_CGW_CCU "ASR NM Control Bit Vector - PN Info Bit";
CM_ SG_ 2549874800 NRR_CGW_CCU "ASR NM Network Request Reason";
CM_ SG_ 2549874800 NM_State_CGW_CCU "ASR NM State_Current State_Previous State";
CM_ SG_ 2549874800 PNI_CGW_CCU "ASR NM Partial Networking Information";
CM_ SG_ 2549874800 PNI_CGW_CCU_1 "ASR NM Partial Networking Information";
CM_ SG_ 2549874800 PNI_CGW_CCU_2 "ASR NM Partial Networking Information";
CM_ SG_ 2549874800 PNI_CGW_CCU_3 "ASR NM Partial Networking Information";
CM_ SG_ 2549874806 SNI_MDPS "ASR NM Source Node Identifier";
CM_ SG_ 2549874806 CBV_RMR_MDPS "ASR NM Control Bit Vector - Repeat Message Request";
CM_ SG_ 2549874806 CBV_NMCoID_MDPS "ASR NM Control Bit Vector - ASR NM Coordinator ID";
CM_ SG_ 2549874806 CBV_NMCoSRB_MDPS "ASR NM Control Bit Vector - ASR NM Coordinator Sleep Ready Bit";
CM_ SG_ 2549874806 CBV_AWB_MDPS "ASR NM Control Bit Vector - Active Wakeup Bit";
CM_ SG_ 2549874806 CBV_PNIB_MDPS "ASR NM Control Bit Vector - PN Info Bit";
CM_ SG_ 2549874806 NRR_MDPS "ASR NM Network Request Reason";
CM_ SG_ 2549874806 NM_State_MDPS "ASR NM State_Current State_Previous State";
CM_ SG_ 2549874806 PNI_MDPS "ASR NM Partial Networking Information";
CM_ SG_ 2549874806 PNI_MDPS_1 "ASR NM Partial Networking Information";
CM_ SG_ 2549874806 PNI_MDPS_2 "ASR NM Partial Networking Information";
CM_ SG_ 2549874806 PNI_MDPS_3 "ASR NM Partial Networking Information";
CM_ SG_ 2549874762 SNI_RWA "ASR NM Source Node Identifier";
CM_ SG_ 2549874762 CBV_RMR_RWA "ASR NM Control Bit Vector - Repeat Message Request";
CM_ SG_ 2549874762 CBV_NMCoID_RWA "ASR NM Control Bit Vector - ASR NM Coordinator ID";
CM_ SG_ 2549874762 CBV_NMCoSRB_RWA "ASR NM Control Bit Vector - ASR NM Coordinator Sleep Ready Bit";
CM_ SG_ 2549874762 CBV_AWB_RWA "ASR NM Control Bit Vector - Active Wakeup Bit";
CM_ SG_ 2549874762 CBV_PNIB_RWA "ASR NM Control Bit Vector - PN Info Bit";
CM_ SG_ 2549874762 NRR_RWA "ASR NM Network Request Reason";
CM_ SG_ 2549874762 NM_State_RWA "ASR NM State_Current State_Previous State";
CM_ SG_ 2549874762 PNI_RWA "ASR NM Partial Networking Information";
CM_ SG_ 2549874762 PNI_RWA_1 "ASR NM Partial Networking Information";
CM_ SG_ 2549874762 PNI_RWA_2 "ASR NM Partial Networking Information";
CM_ SG_ 2549874762 PNI_RWA_3 "ASR NM Partial Networking Information";
CM_ SG_ 2549874746 SNI_SFA "ASR NM Source Node Identifier";
CM_ SG_ 2549874746 CBV_RMR_SFA "ASR NM Control Bit Vector - Repeat Message Request";
CM_ SG_ 2549874746 CBV_NMCoID_SFA "ASR NM Control Bit Vector - ASR NM Coordinator ID";
CM_ SG_ 2549874746 CBV_NMCoSRB_SFA "ASR NM Control Bit Vector - ASR NM Coordinator Sleep Ready Bit";
CM_ SG_ 2549874746 CBV_AWB_SFA "ASR NM Control Bit Vector - Active Wakeup Bit";
CM_ SG_ 2549874746 CBV_PNIB_SFA "ASR NM Control Bit Vector - PN Info Bit";
CM_ SG_ 2549874746 NRR_SFA "ASR NM Network Request Reason";
CM_ SG_ 2549874746 NM_State_SFA "ASR NM State_Current State_Previous State";
CM_ SG_ 2549874746 PNI_SFA "ASR NM Partial Networking Information";
CM_ SG_ 2549874746 PNI_SFA_1 "ASR NM Partial Networking Information";
CM_ SG_ 2549874746 PNI_SFA_2 "ASR NM Partial Networking Information";
CM_ SG_ 2549874746 PNI_SFA_3 "ASR NM Partial Networking Information";
BA_DEF_ BO_  "CANFD_BRS" ENUM  "0","1";
BA_DEF_ BO_  "GenMsgEVName" STRING ;
BA_DEF_ BO_  "NmAsrMessage" ENUM  "No","Yes";
BA_DEF_ BO_  "DiagState" ENUM  "No","Yes";
BA_DEF_ BO_  "DiagResponse" ENUM  "No","Yes";
BA_DEF_ BO_  "DiagRequest" ENUM  "No","Yes";
BA_DEF_ BO_  "TpMessage" ENUM  "No","Yes";
BA_DEF_ BO_  "UsrMsgIDSforwardDeviation" INT 0 100;
BA_DEF_ BO_  "UsrMsgIDSbackwardDeviation" INT 50 1000;
BA_DEF_ BO_  "GenMsgCycleTime" INT 0 2000;
BA_DEF_ BO_  "GenMsgStartDelayTime" INT 0 2000;
BA_DEF_ BO_  "GenMsgSendType" ENUM  "Cyclic","NoMsgSendType";
BA_DEF_ BO_  "GenMsgCycleTimeFast" INT 0 500;
BA_DEF_ BO_  "GenMsgDelayTime" INT 0 20;
BA_DEF_ BO_  "GenMsgILSupport" ENUM  "No","Yes";
BA_DEF_ BO_  "GenMsgNrOfRepetition" INT 0 3;
BA_DEF_ BO_  "TpTxIndex" INT 0 65535;
BA_DEF_ BO_  "VFrameFormat" ENUM  "StandardCAN","ExtendedCAN","reserved","reserved","reserved","reserved","reserved","reserved","reserved","reserved","reserved","reserved","reserved","reserved","StandardCAN_FD","ExtendedCAN_FD";
BA_DEF_ SG_  "UserSigValidity" ENUM  "B+","ACC","IG","IG1","IG2","IG3","IG1 or IG2","IG1 or IG3","Undef";
BA_DEF_ SG_  "UsrSigPurpose" ENUM  "Undef","FN","DIAG","DIAG(Req)","DIAG(Res)","DIAG(Func)","DEV","CCP","NM","TP";
BA_DEF_ SG_  "GenSigStartValue" INT 0 1215752192;
BA_DEF_ SG_  "NetworkRequest" ENUM  "Yes","No";
BA_DEF_ SG_  "NetworkRequestHoldingTime" INT 0 65535;
BA_DEF_ SG_  "Description" STRING ;
BA_DEF_ SG_  "Version" STRING ;
BA_DEF_ SG_  "GenSigEnvVarType" ENUM  "Int","Float","Undef";
BA_DEF_ SG_  "GenSigSendType" ENUM  "Cyclic","OnWrite","OnWriteWithRepetition","OnChange","OnChangeWithRepetition","IfActive","IfActiveWithRepetition","NoSigSendType","OnChangeAndIfActive","OnChangeAndIfActiveWithRepetition";
BA_DEF_ SG_  "GwSigLatencyTime" INT 0 65536;
BA_DEF_ SG_  "GwSigMissingSourceType" ENUM  "Undef","OldValue","DefaultValue","InitialValue";
BA_DEF_ SG_  "NWM-WakeupAllowed" ENUM  "<n.a.>";
BA_DEF_ SG_  "RoutingFactor" INT 1 1215752192;
BA_DEF_REL_ BU_SG_REL_  "GenSigTimeoutTime" INT 0 7000;
BA_DEF_DEF_  "CANFD_BRS" "1";
BA_DEF_DEF_  "GenMsgEVName" "@Signame";
BA_DEF_DEF_  "NmAsrMessage" "No";
BA_DEF_DEF_  "DiagState" "No";
BA_DEF_DEF_  "DiagResponse" "No";
BA_DEF_DEF_  "DiagRequest" "No";
BA_DEF_DEF_  "TpMessage" "No";
BA_DEF_DEF_  "UsrMsgIDSforwardDeviation" 10;
BA_DEF_DEF_  "UsrMsgIDSbackwardDeviation" 100;
BA_DEF_DEF_  "GenMsgCycleTime" 200;
BA_DEF_DEF_  "GenMsgStartDelayTime" 0;
BA_DEF_DEF_  "GenMsgSendType" "NoMsgSendType";
BA_DEF_DEF_  "GenMsgCycleTimeFast" 40;
BA_DEF_DEF_  "GenMsgDelayTime" 20;
BA_DEF_DEF_  "GenMsgILSupport" "Yes";
BA_DEF_DEF_  "GenMsgNrOfRepetition" 3;
BA_DEF_DEF_  "TpTxIndex" 0;
BA_DEF_DEF_  "VFrameFormat" "StandardCAN";
BA_DEF_DEF_  "UserSigValidity" "IG";
BA_DEF_DEF_  "UsrSigPurpose" "FN";
BA_DEF_DEF_  "GenSigStartValue" 0;
BA_DEF_DEF_  "NetworkRequest" "No";
BA_DEF_DEF_  "NetworkRequestHoldingTime" 0;
BA_DEF_DEF_  "Description" "";
BA_DEF_DEF_  "Version" "";
BA_DEF_DEF_  "GenSigEnvVarType" "Undef";
BA_DEF_DEF_  "GenSigSendType" "NoSigSendType";
BA_DEF_DEF_  "GwSigLatencyTime" 40;
BA_DEF_DEF_  "GwSigMissingSourceType" "Undef";
BA_DEF_DEF_  "NWM-WakeupAllowed" "<n.a.>";
BA_DEF_DEF_  "RoutingFactor" 1;
BA_DEF_DEF_REL_ "GenSigTimeoutTime" 500;
BA_ "GenMsgSendType" BO_ 234 0;
BA_ "GenMsgCycleTime" BO_ 234 10;
BA_ "GenMsgCycleTimeFast" BO_ 234 0;
BA_ "GenMsgNrOfRepetition" BO_ 234 0;
BA_ "GenMsgDelayTime" BO_ 234 0;
BA_ "VFrameFormat" BO_ 234 14;
BA_ "GenMsgCycleTime" BO_ 1664 0;
BA_ "GenMsgILSupport" BO_ 1664 0;
BA_ "TpMessage" BO_ 1664 1;
BA_ "GenMsgNrOfRepetition" BO_ 1664 0;
BA_ "GenMsgDelayTime" BO_ 1664 10;
BA_ "VFrameFormat" BO_ 1664 14;
BA_ "GenMsgCycleTime" BO_ 1666 0;
BA_ "GenMsgILSupport" BO_ 1666 0;
BA_ "TpMessage" BO_ 1666 1;
BA_ "GenMsgNrOfRepetition" BO_ 1666 0;
BA_ "GenMsgDelayTime" BO_ 1666 10;
BA_ "VFrameFormat" BO_ 1666 14;
BA_ "GenMsgSendType" BO_ 266 0;
BA_ "GenMsgCycleTime" BO_ 266 20;
BA_ "GenMsgCycleTimeFast" BO_ 266 0;
BA_ "GenMsgNrOfRepetition" BO_ 266 0;
BA_ "GenMsgDelayTime" BO_ 266 0;
BA_ "VFrameFormat" BO_ 266 14;
BA_ "GenMsgSendType" BO_ 813 0;
BA_ "VFrameFormat" BO_ 813 14;
BA_ "GenMsgCycleTime" BO_ 2550071313 0;
BA_ "GenMsgCycleTimeFast" BO_ 2550071313 0;
BA_ "GenMsgNrOfRepetition" BO_ 2550071313 0;
BA_ "DiagResponse" BO_ 2550071313 1;
BA_ "GenMsgILSupport" BO_ 2550071313 0;
BA_ "TpMessage" BO_ 2550071313 1;
BA_ "TpTxIndex" BO_ 2550071313 340;
BA_ "VFrameFormat" BO_ 2550071313 15;
BA_ "GenMsgSendType" BO_ 811 0;
BA_ "VFrameFormat" BO_ 811 14;
BA_ "GenMsgSendType" BO_ 288 0;
BA_ "GenMsgCycleTime" BO_ 288 20;
BA_ "GenMsgCycleTimeFast" BO_ 288 0;
BA_ "GenMsgNrOfRepetition" BO_ 288 0;
BA_ "GenMsgDelayTime" BO_ 288 0;
BA_ "VFrameFormat" BO_ 288 14;
BA_ "GenMsgSendType" BO_ 293 0;
BA_ "GenMsgCycleTime" BO_ 293 10;
BA_ "GenMsgCycleTimeFast" BO_ 293 0;
BA_ "GenMsgNrOfRepetition" BO_ 293 0;
BA_ "GenMsgDelayTime" BO_ 293 0;
BA_ "VFrameFormat" BO_ 293 14;
BA_ "GenMsgCycleTime" BO_ 2550075648 0;
BA_ "GenMsgCycleTimeFast" BO_ 2550075648 0;
BA_ "GenMsgNrOfRepetition" BO_ 2550075648 0;
BA_ "DiagRequest" BO_ 2550075648 1;
BA_ "GenMsgILSupport" BO_ 2550075648 0;
BA_ "TpMessage" BO_ 2550075648 1;
BA_ "TpTxIndex" BO_ 2550075648 340;
BA_ "VFrameFormat" BO_ 2550075648 15;
BA_ "GenMsgSendType" BO_ 298 0;
BA_ "GenMsgCycleTime" BO_ 298 10;
BA_ "GenMsgCycleTimeFast" BO_ 298 0;
BA_ "GenMsgNrOfRepetition" BO_ 298 0;
BA_ "GenMsgDelayTime" BO_ 298 0;
BA_ "VFrameFormat" BO_ 298 14;
BA_ "GenMsgSendType" BO_ 374 0;
BA_ "GenMsgCycleTime" BO_ 374 20;
BA_ "GenMsgCycleTimeFast" BO_ 374 0;
BA_ "GenMsgNrOfRepetition" BO_ 374 0;
BA_ "GenMsgDelayTime" BO_ 374 0;
BA_ "VFrameFormat" BO_ 374 14;
BA_ "GenMsgSendType" BO_ 357 0;
BA_ "GenMsgCycleTime" BO_ 357 20;
BA_ "GenMsgCycleTimeFast" BO_ 357 0;
BA_ "GenMsgNrOfRepetition" BO_ 357 0;
BA_ "GenMsgDelayTime" BO_ 357 0;
BA_ "VFrameFormat" BO_ 357 14;
BA_ "GenMsgSendType" BO_ 358 0;
BA_ "GenMsgCycleTime" BO_ 358 20;
BA_ "GenMsgCycleTimeFast" BO_ 358 0;
BA_ "GenMsgNrOfRepetition" BO_ 358 0;
BA_ "GenMsgDelayTime" BO_ 358 0;
BA_ "VFrameFormat" BO_ 358 14;
BA_ "GenMsgSendType" BO_ 405 0;
BA_ "GenMsgCycleTime" BO_ 405 10;
BA_ "GenMsgCycleTimeFast" BO_ 405 0;
BA_ "GenMsgNrOfRepetition" BO_ 405 0;
BA_ "GenMsgDelayTime" BO_ 405 0;
BA_ "VFrameFormat" BO_ 405 14;
BA_ "GenMsgCycleTime" BO_ 2004 0;
BA_ "GenMsgCycleTimeFast" BO_ 2004 0;
BA_ "GenMsgNrOfRepetition" BO_ 2004 0;
BA_ "DiagRequest" BO_ 2004 1;
BA_ "GenMsgILSupport" BO_ 2004 0;
BA_ "TpMessage" BO_ 2004 1;
BA_ "TpTxIndex" BO_ 2004 146;
BA_ "VFrameFormat" BO_ 2004 14;
BA_ "GenMsgCycleTime" BO_ 2015 0;
BA_ "GenMsgCycleTimeFast" BO_ 2015 0;
BA_ "GenMsgNrOfRepetition" BO_ 2015 0;
BA_ "DiagState" BO_ 2015 1;
BA_ "GenMsgILSupport" BO_ 2015 0;
BA_ "TpMessage" BO_ 2015 1;
BA_ "VFrameFormat" BO_ 2015 14;
BA_ "GenMsgCycleTime" BO_ 2012 0;
BA_ "GenMsgCycleTimeFast" BO_ 2012 0;
BA_ "GenMsgNrOfRepetition" BO_ 2012 0;
BA_ "DiagResponse" BO_ 2012 1;
BA_ "GenMsgILSupport" BO_ 2012 0;
BA_ "TpMessage" BO_ 2012 1;
BA_ "TpTxIndex" BO_ 2012 146;
BA_ "VFrameFormat" BO_ 2012 14;
BA_ "GenMsgSendType" BO_ 426 0;
BA_ "GenMsgCycleTime" BO_ 426 40;
BA_ "GenMsgCycleTimeFast" BO_ 426 0;
BA_ "GenMsgNrOfRepetition" BO_ 426 0;
BA_ "GenMsgDelayTime" BO_ 426 0;
BA_ "VFrameFormat" BO_ 426 14;
BA_ "GenMsgSendType" BO_ 901 0;
BA_ "GenMsgCycleTime" BO_ 901 100;
BA_ "GenMsgCycleTimeFast" BO_ 901 0;
BA_ "GenMsgNrOfRepetition" BO_ 901 0;
BA_ "VFrameFormat" BO_ 901 14;
BA_ "GenMsgSendType" BO_ 994 0;
BA_ "VFrameFormat" BO_ 994 14;
BA_ "GenMsgCycleTime" BO_ 2549874807 100;
BA_ "GenMsgCycleTimeFast" BO_ 2549874807 0;
BA_ "GenMsgDelayTime" BO_ 2549874807 10;
BA_ "GenMsgILSupport" BO_ 2549874807 0;
BA_ "GenMsgNrOfRepetition" BO_ 2549874807 0;
BA_ "NmAsrMessage" BO_ 2549874807 1;
BA_ "VFrameFormat" BO_ 2549874807 15;
BA_ "GenMsgCycleTime" BO_ 2549874769 100;
BA_ "GenMsgCycleTimeFast" BO_ 2549874769 0;
BA_ "GenMsgDelayTime" BO_ 2549874769 10;
BA_ "GenMsgILSupport" BO_ 2549874769 0;
BA_ "GenMsgNrOfRepetition" BO_ 2549874769 0;
BA_ "NmAsrMessage" BO_ 2549874769 1;
BA_ "VFrameFormat" BO_ 2549874769 15;
BA_ "GenMsgCycleTime" BO_ 2549874805 100;
BA_ "GenMsgCycleTimeFast" BO_ 2549874805 0;
BA_ "GenMsgDelayTime" BO_ 2549874805 10;
BA_ "GenMsgILSupport" BO_ 2549874805 0;
BA_ "GenMsgNrOfRepetition" BO_ 2549874805 0;
BA_ "NmAsrMessage" BO_ 2549874805 1;
BA_ "VFrameFormat" BO_ 2549874805 15;
BA_ "GenMsgCycleTime" BO_ 2549874809 100;
BA_ "GenMsgCycleTimeFast" BO_ 2549874809 0;
BA_ "GenMsgDelayTime" BO_ 2549874809 10;
BA_ "GenMsgILSupport" BO_ 2549874809 0;
BA_ "GenMsgNrOfRepetition" BO_ 2549874809 0;
BA_ "NmAsrMessage" BO_ 2549874809 1;
BA_ "VFrameFormat" BO_ 2549874809 15;
BA_ "GenMsgCycleTime" BO_ 2549874751 100;
BA_ "GenMsgCycleTimeFast" BO_ 2549874751 0;
BA_ "GenMsgDelayTime" BO_ 2549874751 10;
BA_ "GenMsgILSupport" BO_ 2549874751 0;
BA_ "GenMsgNrOfRepetition" BO_ 2549874751 0;
BA_ "NmAsrMessage" BO_ 2549874751 1;
BA_ "VFrameFormat" BO_ 2549874751 15;
BA_ "GenMsgCycleTime" BO_ 2549874786 100;
BA_ "GenMsgCycleTimeFast" BO_ 2549874786 0;
BA_ "GenMsgDelayTime" BO_ 2549874786 10;
BA_ "GenMsgILSupport" BO_ 2549874786 0;
BA_ "GenMsgNrOfRepetition" BO_ 2549874786 0;
BA_ "NmAsrMessage" BO_ 2549874786 1;
BA_ "VFrameFormat" BO_ 2549874786 15;
BA_ "GenMsgCycleTime" BO_ 2549874800 100;
BA_ "GenMsgCycleTimeFast" BO_ 2549874800 0;
BA_ "GenMsgDelayTime" BO_ 2549874800 10;
BA_ "GenMsgILSupport" BO_ 2549874800 0;
BA_ "GenMsgNrOfRepetition" BO_ 2549874800 0;
BA_ "NmAsrMessage" BO_ 2549874800 1;
BA_ "VFrameFormat" BO_ 2549874800 15;
BA_ "GenMsgCycleTime" BO_ 2549874806 100;
BA_ "GenMsgCycleTimeFast" BO_ 2549874806 0;
BA_ "GenMsgDelayTime" BO_ 2549874806 10;
BA_ "GenMsgILSupport" BO_ 2549874806 0;
BA_ "GenMsgNrOfRepetition" BO_ 2549874806 0;
BA_ "NmAsrMessage" BO_ 2549874806 1;
BA_ "VFrameFormat" BO_ 2549874806 15;
BA_ "GenMsgCycleTime" BO_ 2549874762 100;
BA_ "GenMsgCycleTimeFast" BO_ 2549874762 0;
BA_ "GenMsgDelayTime" BO_ 2549874762 10;
BA_ "GenMsgILSupport" BO_ 2549874762 0;
BA_ "GenMsgNrOfRepetition" BO_ 2549874762 0;
BA_ "NmAsrMessage" BO_ 2549874762 1;
BA_ "VFrameFormat" BO_ 2549874762 15;
BA_ "GenMsgCycleTime" BO_ 2549874746 100;
BA_ "GenMsgCycleTimeFast" BO_ 2549874746 0;
BA_ "GenMsgDelayTime" BO_ 2549874746 10;
BA_ "GenMsgILSupport" BO_ 2549874746 0;
BA_ "GenMsgNrOfRepetition" BO_ 2549874746 0;
BA_ "NmAsrMessage" BO_ 2549874746 1;
BA_ "VFrameFormat" BO_ 2549874746 15;
BA_ "Description" SG_ 234 MDPS_Crc1Val "The data area for CRC calculation is based on the data length (DLC) of the message DB.

The CRC shall be calculated over the entire data block (excluding the CRC bytes) including the user data, alive counter and Data ID

 

- CRC Polynomial (0x1021) , In";
BA_ "GenSigStartValue" SG_ 234 MDPS_Crc1Val 65535;
BA_ "UserSigValidity" SG_ 234 MDPS_Crc1Val 3;
BA_ "RoutingFactor" SG_ 234 MDPS_Crc1Val 5;
BA_ "Version" SG_ 234 MDPS_Crc1Val "18.11.08";
BA_ "Description" SG_ 234 MDPS_LoamModSta "The signal represent status of the LOAM(Loss Of Assist Mitigation) Mode";
BA_ "UserSigValidity" SG_ 234 MDPS_LoamModSta 3;
BA_ "RoutingFactor" SG_ 234 MDPS_LoamModSta 5;
BA_ "Version" SG_ 234 MDPS_LoamModSta "21.10.03";
BA_ "Description" SG_ 234 MDPS_HDPSpprtSWVer "This signal indicates HDP-MDPS Control Requirement Spec Version";
BA_ "UserSigValidity" SG_ 234 MDPS_HDPSpprtSWVer 3;
BA_ "RoutingFactor" SG_ 234 MDPS_HDPSpprtSWVer 5;
BA_ "Version" SG_ 234 MDPS_HDPSpprtSWVer "21.11.00";
BA_ "Description" SG_ 234 MDPS_ADASAciActvSta "State for angle control";
BA_ "UserSigValidity" SG_ 234 MDPS_ADASAciActvSta 3;
BA_ "RoutingFactor" SG_ 234 MDPS_ADASAciActvSta 5;
BA_ "Version" SG_ 234 MDPS_ADASAciActvSta "22.01.00";
BA_ "Description" SG_ 234 MDPS_ADASAciPluginSta "This signal indicates whether the ADASAci function of MDPS is plugged in or not.";
BA_ "UserSigValidity" SG_ 234 MDPS_ADASAciPluginSta 3;
BA_ "RoutingFactor" SG_ 234 MDPS_ADASAciPluginSta 5;
BA_ "Version" SG_ 234 MDPS_ADASAciPluginSta "21.10.03";
BA_ "Description" SG_ 234 MDPS_ADAS_AciFltSig "MDPS Fault Status for HDP Function";
BA_ "UserSigValidity" SG_ 234 MDPS_ADAS_AciFltSig 3;
BA_ "RoutingFactor" SG_ 234 MDPS_ADAS_AciFltSig 5;
BA_ "Version" SG_ 234 MDPS_ADAS_AciFltSig "21.03.10";
BA_ "Description" SG_ 234 MDPS_EstStrAnglVal "This value is used to inform of a compensated steering wheel angle by MDPS . The signal is signed 16bits, and made by motor position sensor. 



(PH) = (HEX) �� 0.1 (for 0 < HEX �� 32767)  or

= (HEX - 65536) �� 0.1 (for HEX > 32767) [Deg]



this signal";
BA_ "GenSigStartValue" SG_ 234 MDPS_EstStrAnglVal 32767;
BA_ "UserSigValidity" SG_ 234 MDPS_EstStrAnglVal 3;
BA_ "RoutingFactor" SG_ 234 MDPS_EstStrAnglVal 5;
BA_ "Version" SG_ 234 MDPS_EstStrAnglVal "21.10.03";
BA_ "Description" SG_ 234 MDPS_ADASAciActvSta_Lv2 "States for angle control (LV2)";
BA_ "UserSigValidity" SG_ 234 MDPS_ADASAciActvSta_Lv2 3;
BA_ "RoutingFactor" SG_ 234 MDPS_ADASAciActvSta_Lv2 5;
BA_ "Version" SG_ 234 MDPS_ADASAciActvSta_Lv2 "21.11.00";
BA_ "Description" SG_ 234 MDPS_ADAS_AciFltSig_Lv2 "MDPS Fault Status for LV2 Angle Control Function";
BA_ "UserSigValidity" SG_ 234 MDPS_ADAS_AciFltSig_Lv2 3;
BA_ "RoutingFactor" SG_ 234 MDPS_ADAS_AciFltSig_Lv2 5;
BA_ "Version" SG_ 234 MDPS_ADAS_AciFltSig_Lv2 "21.11.00";
BA_ "Description" SG_ 234 MDPS_TpaPlugInSta "This signal indicates whether the TPA function of MDPS is plugged in or not.";
BA_ "UserSigValidity" SG_ 234 MDPS_TpaPlugInSta 3;
BA_ "RoutingFactor" SG_ 234 MDPS_TpaPlugInSta 5;
BA_ "Version" SG_ 234 MDPS_TpaPlugInSta "22.03.03";
BA_ "Description" SG_ 234 MDPS_TpaCanfltSta "�� This Signal should be used by only TPA

This signal indicates whether the MDPS is defective in TPA cooperation control. 

This signal is set as '1' only when MDPS Detects CAN Failure(TIMEOUT, Signal Error) of TPA CAN Message";
BA_ "UserSigValidity" SG_ 234 MDPS_TpaCanfltSta 3;
BA_ "RoutingFactor" SG_ 234 MDPS_TpaCanfltSta 5;
BA_ "Version" SG_ 234 MDPS_TpaCanfltSta "22.03.03";
BA_ "Description" SG_ 234 MDPS_TpaModeSta "This signal indicates the status of the TPA steering function.";
BA_ "GenSigStartValue" SG_ 234 MDPS_TpaModeSta 1;
BA_ "UserSigValidity" SG_ 234 MDPS_TpaModeSta 3;
BA_ "RoutingFactor" SG_ 234 MDPS_TpaModeSta 5;
BA_ "Version" SG_ 234 MDPS_TpaModeSta "23.04.05";
BA_ "Description" SG_ 234 MDPS_AlvCnt1Val "For the first transmission request for a data element the counter shall be initialized with 0 and shall be incremented by 1 for every subsequent send request. 

When the counter reaches the maximum value(0xFF), then it shall restart with 0 for the next s";
BA_ "UserSigValidity" SG_ 234 MDPS_AlvCnt1Val 3;
BA_ "RoutingFactor" SG_ 234 MDPS_AlvCnt1Val 5;
BA_ "Version" SG_ 234 MDPS_AlvCnt1Val "18.11.08";
BA_ "Description" SG_ 234 MDPS_TpaStrAnglVal "This value is used to inform TPA of a compensated steering wheel angle by MDPS. The signal is signed 16bits.



(PH) = (HEX) �� 0.1 (for 0 < HEX �� 32767)  or

= (HEX - 65536) �� 0.1 (for HEX > 32767) [Deg]";
BA_ "GenSigStartValue" SG_ 234 MDPS_TpaStrAnglVal 32767;
BA_ "UserSigValidity" SG_ 234 MDPS_TpaStrAnglVal 3;
BA_ "RoutingFactor" SG_ 234 MDPS_TpaStrAnglVal 5;
BA_ "Version" SG_ 234 MDPS_TpaStrAnglVal "23.04.05";
BA_ "Description" SG_ 234 MDPS_WrngLmpSta "The signal indicates the ststus of the ��MDPS Warning lamp��";
BA_ "UserSigValidity" SG_ 234 MDPS_WrngLmpSta 3;
BA_ "RoutingFactor" SG_ 234 MDPS_WrngLmpSta 5;
BA_ "Version" SG_ 234 MDPS_WrngLmpSta "21.10.03";
BA_ "Description" SG_ 234 MDPS_Typ "Information regarding the type of MDPS. (C-MDPS / R-MDPS / SbW)";
BA_ "UserSigValidity" SG_ 234 MDPS_Typ 3;
BA_ "RoutingFactor" SG_ 234 MDPS_Typ 5;
BA_ "Version" SG_ 234 MDPS_Typ "23.07.04";
BA_ "Description" SG_ 234 MDPS_EngIdleRpmReq "This signal indicates the request status for engine idle rpm up according to MDPS fast rotation.";
BA_ "UserSigValidity" SG_ 234 MDPS_EngIdleRpmReq 3;
BA_ "RoutingFactor" SG_ 234 MDPS_EngIdleRpmReq 5;
BA_ "Version" SG_ 234 MDPS_EngIdleRpmReq "21.10.03";
BA_ "Description" SG_ 234 MDPS_VsmPlgInSta "This signal indicates whether the VSM function of MDPS is plugged in or not.";
BA_ "UserSigValidity" SG_ 234 MDPS_VsmPlgInSta 3;
BA_ "RoutingFactor" SG_ 234 MDPS_VsmPlgInSta 5;
BA_ "Version" SG_ 234 MDPS_VsmPlgInSta "21.10.03";
BA_ "Description" SG_ 234 MDPS_VsmDfctvSta "Information regarding the MDPS ��defective�� Indication For VSM";
BA_ "UserSigValidity" SG_ 234 MDPS_VsmDfctvSta 3;
BA_ "RoutingFactor" SG_ 234 MDPS_VsmDfctvSta 5;
BA_ "Version" SG_ 234 MDPS_VsmDfctvSta "21.10.03";
BA_ "Description" SG_ 234 MDPS_VsmSigErrSta "Information indicating VSM signal status";
BA_ "UserSigValidity" SG_ 234 MDPS_VsmSigErrSta 3;
BA_ "RoutingFactor" SG_ 234 MDPS_VsmSigErrSta 5;
BA_ "Version" SG_ 234 MDPS_VsmSigErrSta "21.10.03";
BA_ "Description" SG_ 234 MDPS_PaPlugInSta "This signal indicates whether the PA function of MDPS is plugged in or not.";
BA_ "UserSigValidity" SG_ 234 MDPS_PaPlugInSta 3;
BA_ "RoutingFactor" SG_ 234 MDPS_PaPlugInSta 5;
BA_ "Version" SG_ 234 MDPS_PaPlugInSta "21.10.03";
BA_ "Description" SG_ 234 MDPS_PaModeSta "This signal indicates the status of the PA steering function.";
BA_ "GenSigStartValue" SG_ 234 MDPS_PaModeSta 1;
BA_ "UserSigValidity" SG_ 234 MDPS_PaModeSta 3;
BA_ "RoutingFactor" SG_ 234 MDPS_PaModeSta 5;
BA_ "Version" SG_ 234 MDPS_PaModeSta "23.04.05";
BA_ "Description" SG_ 234 MDPS_PaCanfltSta "�� This Signal should be used by only PA

This signal indicates whether the MDPS is defective in PA cooperation control. 

This signal is set as '1' only when MDPS Detects CAN Failure(TIMEOUT, Signal Error) of PA CAN Message";
BA_ "UserSigValidity" SG_ 234 MDPS_PaCanfltSta 3;
BA_ "RoutingFactor" SG_ 234 MDPS_PaCanfltSta 5;
BA_ "Version" SG_ 234 MDPS_PaCanfltSta "21.10.03";
BA_ "Description" SG_ 234 MDPS_LkaPlgInSta "This signal indicates whether the LKA function of MDPS is plugged in or not.";
BA_ "UserSigValidity" SG_ 234 MDPS_LkaPlgInSta 3;
BA_ "RoutingFactor" SG_ 234 MDPS_LkaPlgInSta 5;
BA_ "Version" SG_ 234 MDPS_LkaPlgInSta "21.10.03";
BA_ "Description" SG_ 234 MDPS_LkaToiActvSta "This flag is set to 1 in response to the LKA Controller requesting the activation of the torque interface and set back to 0 in response to the LKA Controller requesting the de-activation of the torque interface.";
BA_ "UserSigValidity" SG_ 234 MDPS_LkaToiActvSta 3;
BA_ "RoutingFactor" SG_ 234 MDPS_LkaToiActvSta 5;
BA_ "Version" SG_ 234 MDPS_LkaToiActvSta "21.10.03";
BA_ "Description" SG_ 234 MDPS_LkaToiUnblSta "This is a flag that is set when the MDPS is not faulty, but is temporarily unable to activate the TOI due to steering torque limiting e.g. when the supply voltage is too low.";
BA_ "UserSigValidity" SG_ 234 MDPS_LkaToiUnblSta 3;
BA_ "RoutingFactor" SG_ 234 MDPS_LkaToiUnblSta 5;
BA_ "Version" SG_ 234 MDPS_LkaToiUnblSta "21.10.03";
BA_ "Description" SG_ 234 MDPS_LkaToiFltSta "This fault flag is set when a fault within the MDPS system has been detected such that the LKA TOI can no longer function. CAN failures, internal MDPS failures, and LKA controller logic failures are all reported by this flag. Failures reported by the LKA";
BA_ "UserSigValidity" SG_ 234 MDPS_LkaToiFltSta 3;
BA_ "RoutingFactor" SG_ 234 MDPS_LkaToiFltSta 5;
BA_ "Version" SG_ 234 MDPS_LkaToiFltSta "21.10.03";
BA_ "Description" SG_ 234 MDPS_LkaFailSta "This fault flag is set whilst the MDPS TOI is in a fail state and has not yet recovered from it. This could either be due to an MDPS detected fault (as communicated by the ��MDPS_LkaToiFltSta' flag) or an LKA detected fault (as communicated by the ��LKA_";
BA_ "UserSigValidity" SG_ 234 MDPS_LkaFailSta 3;
BA_ "RoutingFactor" SG_ 234 MDPS_LkaFailSta 5;
BA_ "Version" SG_ 234 MDPS_LkaFailSta "21.10.03";
BA_ "Description" SG_ 234 MDPS_ResetOpSta "Information regarding the state of reset";
BA_ "UserSigValidity" SG_ 234 MDPS_ResetOpSta 0;
BA_ "RoutingFactor" SG_ 234 MDPS_ResetOpSta 5;
BA_ "Version" SG_ 234 MDPS_ResetOpSta "24.04.03";
BA_ "Description" SG_ 234 MDPS_CurrModVal "This signal indicates flex steer parameter value in MDPS.



�� For information about flex steer mode set by user, refer to MDPS_FlxStrSta signal.";
BA_ "UserSigValidity" SG_ 234 MDPS_CurrModVal 3;
BA_ "RoutingFactor" SG_ 234 MDPS_CurrModVal 5;
BA_ "Version" SG_ 234 MDPS_CurrModVal "23.02.01";
BA_ "Description" SG_ 234 MDPS_OutTqVal "MDPS column torque

this signal has direction information.

'+' Value means Counter clock wise rotation.

'-' value means Clock wise rotation.";
BA_ "GenSigStartValue" SG_ 234 MDPS_OutTqVal 2048;
BA_ "UserSigValidity" SG_ 234 MDPS_OutTqVal 3;
BA_ "RoutingFactor" SG_ 234 MDPS_OutTqVal 5;
BA_ "Version" SG_ 234 MDPS_OutTqVal "21.10.03";
BA_ "Description" SG_ 234 MDPS_VsmActResp "Information of VSM Tqrque Intervention Act Response";
BA_ "UserSigValidity" SG_ 234 MDPS_VsmActResp 3;
BA_ "RoutingFactor" SG_ 234 MDPS_VsmActResp 5;
BA_ "Version" SG_ 234 MDPS_VsmActResp "21.10.03";
BA_ "Description" SG_ 234 Reprogram_State_MDPS "Information regarding the reprogram state";
BA_ "GenSigStartValue" SG_ 234 Reprogram_State_MDPS 3;
BA_ "UserSigValidity" SG_ 234 Reprogram_State_MDPS 0;
BA_ "RoutingFactor" SG_ 234 Reprogram_State_MDPS 5;
BA_ "Version" SG_ 234 Reprogram_State_MDPS "24.04.07";
BA_ "Description" SG_ 234 MDPS_StrTqSnsrVal "Steering torque sensor value



Physical Value > 0: Left Direction (CCW)

Physical Value < 0: Right Direction (CW)



this signal has direction information.

'+' Value means Counter clock wise rotation.

'-' value means Clock wise rotation.";
BA_ "GenSigStartValue" SG_ 234 MDPS_StrTqSnsrVal 4096;
BA_ "UserSigValidity" SG_ 234 MDPS_StrTqSnsrVal 3;
BA_ "RoutingFactor" SG_ 234 MDPS_StrTqSnsrVal 5;
BA_ "Version" SG_ 234 MDPS_StrTqSnsrVal "21.10.03";
BA_ "Description" SG_ 234 MDPS_PaStrAnglVal "This value is used to inform PA of a compensated steering wheel angle by MDPS. The signal is signed 16bits.



(PH) = (HEX) �� 0.1 (for 0 < HEX �� 32767)  or

= (HEX - 65536) �� 0.1 (for HEX > 32767) [Deg]



this signal has direction information.

'+' V";
BA_ "GenSigStartValue" SG_ 234 MDPS_PaStrAnglVal 32767;
BA_ "UserSigValidity" SG_ 234 MDPS_PaStrAnglVal 3;
BA_ "RoutingFactor" SG_ 234 MDPS_PaStrAnglVal 5;
BA_ "Version" SG_ 234 MDPS_PaStrAnglVal "23.04.05";
BA_ "UsrSigPurpose" SG_ 1664 CCP_MDPS_SFA_REQ1_Byte0 7;
BA_ "GenSigSendType" SG_ 1664 CCP_MDPS_SFA_REQ1_Byte0 2;
BA_ "UserSigValidity" SG_ 1664 CCP_MDPS_SFA_REQ1_Byte0 0;
BA_ "NetworkRequest" SG_ 1664 CCP_MDPS_SFA_REQ1_Byte0 0;
BA_ "NetworkRequestHoldingTime" SG_ 1664 CCP_MDPS_SFA_REQ1_Byte0 5000;
BA_ "Version" SG_ 1664 CCP_MDPS_SFA_REQ1_Byte0 "23.04.01";
BA_ "UsrSigPurpose" SG_ 1664 CCP_MDPS_SFA_REQ1_Byte2 7;
BA_ "GenSigSendType" SG_ 1664 CCP_MDPS_SFA_REQ1_Byte2 2;
BA_ "UserSigValidity" SG_ 1664 CCP_MDPS_SFA_REQ1_Byte2 0;
BA_ "NetworkRequest" SG_ 1664 CCP_MDPS_SFA_REQ1_Byte2 0;
BA_ "NetworkRequestHoldingTime" SG_ 1664 CCP_MDPS_SFA_REQ1_Byte2 5000;
BA_ "Version" SG_ 1664 CCP_MDPS_SFA_REQ1_Byte2 "23.04.01";
BA_ "UsrSigPurpose" SG_ 1664 CCP_MDPS_SFA_REQ1_Byte3 7;
BA_ "GenSigSendType" SG_ 1664 CCP_MDPS_SFA_REQ1_Byte3 2;
BA_ "UserSigValidity" SG_ 1664 CCP_MDPS_SFA_REQ1_Byte3 0;
BA_ "NetworkRequest" SG_ 1664 CCP_MDPS_SFA_REQ1_Byte3 0;
BA_ "NetworkRequestHoldingTime" SG_ 1664 CCP_MDPS_SFA_REQ1_Byte3 5000;
BA_ "Version" SG_ 1664 CCP_MDPS_SFA_REQ1_Byte3 "23.04.01";
BA_ "UsrSigPurpose" SG_ 1664 CCP_MDPS_SFA_REQ1_Byte4 7;
BA_ "GenSigSendType" SG_ 1664 CCP_MDPS_SFA_REQ1_Byte4 2;
BA_ "UserSigValidity" SG_ 1664 CCP_MDPS_SFA_REQ1_Byte4 0;
BA_ "NetworkRequest" SG_ 1664 CCP_MDPS_SFA_REQ1_Byte4 0;
BA_ "NetworkRequestHoldingTime" SG_ 1664 CCP_MDPS_SFA_REQ1_Byte4 5000;
BA_ "Version" SG_ 1664 CCP_MDPS_SFA_REQ1_Byte4 "23.04.01";
BA_ "UsrSigPurpose" SG_ 1664 CCP_MDPS_SFA_REQ1_Byte5 7;
BA_ "GenSigSendType" SG_ 1664 CCP_MDPS_SFA_REQ1_Byte5 2;
BA_ "UserSigValidity" SG_ 1664 CCP_MDPS_SFA_REQ1_Byte5 0;
BA_ "NetworkRequest" SG_ 1664 CCP_MDPS_SFA_REQ1_Byte5 0;
BA_ "NetworkRequestHoldingTime" SG_ 1664 CCP_MDPS_SFA_REQ1_Byte5 5000;
BA_ "Version" SG_ 1664 CCP_MDPS_SFA_REQ1_Byte5 "23.04.01";
BA_ "UsrSigPurpose" SG_ 1664 CCP_MDPS_SFA_REQ1_Byte6 7;
BA_ "GenSigSendType" SG_ 1664 CCP_MDPS_SFA_REQ1_Byte6 2;
BA_ "UserSigValidity" SG_ 1664 CCP_MDPS_SFA_REQ1_Byte6 0;
BA_ "NetworkRequest" SG_ 1664 CCP_MDPS_SFA_REQ1_Byte6 0;
BA_ "NetworkRequestHoldingTime" SG_ 1664 CCP_MDPS_SFA_REQ1_Byte6 5000;
BA_ "Version" SG_ 1664 CCP_MDPS_SFA_REQ1_Byte6 "23.04.01";
BA_ "UsrSigPurpose" SG_ 1664 CCP_MDPS_SFA_REQ1_Byte7 7;
BA_ "GenSigSendType" SG_ 1664 CCP_MDPS_SFA_REQ1_Byte7 2;
BA_ "UserSigValidity" SG_ 1664 CCP_MDPS_SFA_REQ1_Byte7 0;
BA_ "NetworkRequest" SG_ 1664 CCP_MDPS_SFA_REQ1_Byte7 0;
BA_ "NetworkRequestHoldingTime" SG_ 1664 CCP_MDPS_SFA_REQ1_Byte7 5000;
BA_ "Version" SG_ 1664 CCP_MDPS_SFA_REQ1_Byte7 "23.04.01";
BA_ "UsrSigPurpose" SG_ 1664 CCP_MDPS_SFA_REQ1_Byte1 7;
BA_ "GenSigSendType" SG_ 1664 CCP_MDPS_SFA_REQ1_Byte1 2;
BA_ "UserSigValidity" SG_ 1664 CCP_MDPS_SFA_REQ1_Byte1 0;
BA_ "NetworkRequest" SG_ 1664 CCP_MDPS_SFA_REQ1_Byte1 0;
BA_ "NetworkRequestHoldingTime" SG_ 1664 CCP_MDPS_SFA_REQ1_Byte1 5000;
BA_ "Version" SG_ 1664 CCP_MDPS_SFA_REQ1_Byte1 "23.04.01";
BA_ "UsrSigPurpose" SG_ 1666 CCP_MDPS_RWA_REQ3_Byte0 7;
BA_ "GenSigSendType" SG_ 1666 CCP_MDPS_RWA_REQ3_Byte0 2;
BA_ "UserSigValidity" SG_ 1666 CCP_MDPS_RWA_REQ3_Byte0 0;
BA_ "NetworkRequest" SG_ 1666 CCP_MDPS_RWA_REQ3_Byte0 0;
BA_ "NetworkRequestHoldingTime" SG_ 1666 CCP_MDPS_RWA_REQ3_Byte0 5000;
BA_ "Version" SG_ 1666 CCP_MDPS_RWA_REQ3_Byte0 "23.04.01";
BA_ "UsrSigPurpose" SG_ 1666 CCP_MDPS_RWA_REQ3_Byte2 7;
BA_ "GenSigSendType" SG_ 1666 CCP_MDPS_RWA_REQ3_Byte2 2;
BA_ "UserSigValidity" SG_ 1666 CCP_MDPS_RWA_REQ3_Byte2 0;
BA_ "NetworkRequest" SG_ 1666 CCP_MDPS_RWA_REQ3_Byte2 0;
BA_ "NetworkRequestHoldingTime" SG_ 1666 CCP_MDPS_RWA_REQ3_Byte2 5000;
BA_ "Version" SG_ 1666 CCP_MDPS_RWA_REQ3_Byte2 "23.04.01";
BA_ "UsrSigPurpose" SG_ 1666 CCP_MDPS_RWA_REQ3_Byte3 7;
BA_ "GenSigSendType" SG_ 1666 CCP_MDPS_RWA_REQ3_Byte3 2;
BA_ "UserSigValidity" SG_ 1666 CCP_MDPS_RWA_REQ3_Byte3 0;
BA_ "NetworkRequest" SG_ 1666 CCP_MDPS_RWA_REQ3_Byte3 0;
BA_ "NetworkRequestHoldingTime" SG_ 1666 CCP_MDPS_RWA_REQ3_Byte3 5000;
BA_ "Version" SG_ 1666 CCP_MDPS_RWA_REQ3_Byte3 "23.04.01";
BA_ "UsrSigPurpose" SG_ 1666 CCP_MDPS_RWA_REQ3_Byte4 7;
BA_ "GenSigSendType" SG_ 1666 CCP_MDPS_RWA_REQ3_Byte4 2;
BA_ "UserSigValidity" SG_ 1666 CCP_MDPS_RWA_REQ3_Byte4 0;
BA_ "NetworkRequest" SG_ 1666 CCP_MDPS_RWA_REQ3_Byte4 0;
BA_ "NetworkRequestHoldingTime" SG_ 1666 CCP_MDPS_RWA_REQ3_Byte4 5000;
BA_ "Version" SG_ 1666 CCP_MDPS_RWA_REQ3_Byte4 "23.04.01";
BA_ "UsrSigPurpose" SG_ 1666 CCP_MDPS_RWA_REQ3_Byte5 7;
BA_ "GenSigSendType" SG_ 1666 CCP_MDPS_RWA_REQ3_Byte5 2;
BA_ "UserSigValidity" SG_ 1666 CCP_MDPS_RWA_REQ3_Byte5 0;
BA_ "NetworkRequest" SG_ 1666 CCP_MDPS_RWA_REQ3_Byte5 0;
BA_ "NetworkRequestHoldingTime" SG_ 1666 CCP_MDPS_RWA_REQ3_Byte5 5000;
BA_ "Version" SG_ 1666 CCP_MDPS_RWA_REQ3_Byte5 "23.04.01";
BA_ "UsrSigPurpose" SG_ 1666 CCP_MDPS_RWA_REQ3_Byte6 7;
BA_ "GenSigSendType" SG_ 1666 CCP_MDPS_RWA_REQ3_Byte6 2;
BA_ "UserSigValidity" SG_ 1666 CCP_MDPS_RWA_REQ3_Byte6 0;
BA_ "NetworkRequest" SG_ 1666 CCP_MDPS_RWA_REQ3_Byte6 0;
BA_ "NetworkRequestHoldingTime" SG_ 1666 CCP_MDPS_RWA_REQ3_Byte6 5000;
BA_ "Version" SG_ 1666 CCP_MDPS_RWA_REQ3_Byte6 "23.04.01";
BA_ "UsrSigPurpose" SG_ 1666 CCP_MDPS_RWA_REQ3_Byte7 7;
BA_ "GenSigSendType" SG_ 1666 CCP_MDPS_RWA_REQ3_Byte7 2;
BA_ "UserSigValidity" SG_ 1666 CCP_MDPS_RWA_REQ3_Byte7 0;
BA_ "NetworkRequest" SG_ 1666 CCP_MDPS_RWA_REQ3_Byte7 0;
BA_ "NetworkRequestHoldingTime" SG_ 1666 CCP_MDPS_RWA_REQ3_Byte7 5000;
BA_ "Version" SG_ 1666 CCP_MDPS_RWA_REQ3_Byte7 "23.04.01";
BA_ "UsrSigPurpose" SG_ 1666 CCP_MDPS_RWA_REQ3_Byte1 7;
BA_ "GenSigSendType" SG_ 1666 CCP_MDPS_RWA_REQ3_Byte1 2;
BA_ "UserSigValidity" SG_ 1666 CCP_MDPS_RWA_REQ3_Byte1 0;
BA_ "NetworkRequest" SG_ 1666 CCP_MDPS_RWA_REQ3_Byte1 0;
BA_ "NetworkRequestHoldingTime" SG_ 1666 CCP_MDPS_RWA_REQ3_Byte1 5000;
BA_ "Version" SG_ 1666 CCP_MDPS_RWA_REQ3_Byte1 "23.04.01";
BA_ "Description" SG_ 266 MCU_Crc1Val "The data area for CRC calculation is based on the data length (DLC) of the message DB.

The CRC shall be calculated over the entire data block (excluding the CRC bytes) including the user data, alive counter and Data ID

 

- CRC Polynomial (0x1021) , In";
BA_ "GenSigStartValue" SG_ 266 MCU_Crc1Val 65535;
BA_ "UserSigValidity" SG_ 266 MCU_Crc1Val 7;
BA_ "RoutingFactor" SG_ 266 MCU_Crc1Val 50;
BA_ "Version" SG_ 266 MCU_Crc1Val "18.11.08";
BA_ "Description" SG_ 266 MCU_AlvCnt1Val "For the first transmission request for a data element the counter shall be initialized with 0 and shall be incremented by 1 for every subsequent send request. 

When the counter reaches the maximum value(0xFF), then it shall restart with 0 for the next s";
BA_ "UserSigValidity" SG_ 266 MCU_AlvCnt1Val 7;
BA_ "RoutingFactor" SG_ 266 MCU_AlvCnt1Val 50;
BA_ "Version" SG_ 266 MCU_AlvCnt1Val "18.11.08";
BA_ "Description" SG_ 266 MCU_Mg1EstTqVal "HEV : MG1 - Motor, HSCAN -  X

EV : MG1 - Main Axle, HSCAN - X";
BA_ "UserSigValidity" SG_ 266 MCU_Mg1EstTqVal 7;
BA_ "RoutingFactor" SG_ 266 MCU_Mg1EstTqVal 50;
BA_ "Version" SG_ 266 MCU_Mg1EstTqVal "19.04.04";
BA_ "Description" SG_ 813 SBCM_DRV_FD_Crc1Val "The data area for CRC calculation is based on the data length (DLC) of the message DB.

The CRC shall be calculated over the entire data block (excluding the CRC bytes) including the user data, alive counter and Data ID


- CRC Polynomial (0x1021) , Ini";
BA_ "GenSigSendType" SG_ 813 SBCM_DRV_FD_Crc1Val 4;
BA_ "GenSigStartValue" SG_ 813 SBCM_DRV_FD_Crc1Val 65535;
BA_ "UserSigValidity" SG_ 813 SBCM_DRV_FD_Crc1Val 3;
BA_ "Version" SG_ 813 SBCM_DRV_FD_Crc1Val "22.10.20";
BA_ "Description" SG_ 813 SBCM_DRV_FD_AlvCnt1Val "For the first transmission request for a data element the counter shall be initialized with 0 and shall be incremented by 1 for every subsequent send request. 
When the counter reaches the maximum value(0xFF), then it shall restart with 0 for the next s";
BA_ "GenSigSendType" SG_ 813 SBCM_DRV_FD_AlvCnt1Val 4;
BA_ "UserSigValidity" SG_ 813 SBCM_DRV_FD_AlvCnt1Val 3;
BA_ "Version" SG_ 813 SBCM_DRV_FD_AlvCnt1Val "22.10.20";
BA_ "Description" SG_ 813 Warn_DrvDrSwSta_SBCM "Warning Drive Door Switch State";
BA_ "GenSigSendType" SG_ 813 Warn_DrvDrSwSta_SBCM 4;
BA_ "UserSigValidity" SG_ 813 Warn_DrvDrSwSta_SBCM 0;
BA_ "NetworkRequest" SG_ 813 Warn_DrvDrSwSta_SBCM 0;
BA_ "Version" SG_ 813 Warn_DrvDrSwSta_SBCM "21.09.05";
BA_ "Description" SG_ 2550071313 RWA_GST_Byte0 "TP Index : 340";
BA_ "UsrSigPurpose" SG_ 2550071313 RWA_GST_Byte0 4;
BA_ "UserSigValidity" SG_ 2550071313 RWA_GST_Byte0 0;
BA_ "Version" SG_ 2550071313 RWA_GST_Byte0 "23.06.01";
BA_ "Description" SG_ 2550071313 RWA_GST_Byte2 "TP Index : 340";
BA_ "UsrSigPurpose" SG_ 2550071313 RWA_GST_Byte2 4;
BA_ "UserSigValidity" SG_ 2550071313 RWA_GST_Byte2 0;
BA_ "Version" SG_ 2550071313 RWA_GST_Byte2 "23.06.01";
BA_ "Description" SG_ 2550071313 RWA_GST_Byte3 "TP Index : 340";
BA_ "UsrSigPurpose" SG_ 2550071313 RWA_GST_Byte3 4;
BA_ "UserSigValidity" SG_ 2550071313 RWA_GST_Byte3 0;
BA_ "Version" SG_ 2550071313 RWA_GST_Byte3 "23.06.01";
BA_ "Description" SG_ 2550071313 RWA_GST_Byte4 "TP Index : 340";
BA_ "UsrSigPurpose" SG_ 2550071313 RWA_GST_Byte4 4;
BA_ "UserSigValidity" SG_ 2550071313 RWA_GST_Byte4 0;
BA_ "Version" SG_ 2550071313 RWA_GST_Byte4 "23.06.01";
BA_ "Description" SG_ 2550071313 RWA_GST_Byte5 "TP Index : 340";
BA_ "UsrSigPurpose" SG_ 2550071313 RWA_GST_Byte5 4;
BA_ "UserSigValidity" SG_ 2550071313 RWA_GST_Byte5 0;
BA_ "Version" SG_ 2550071313 RWA_GST_Byte5 "23.06.01";
BA_ "Description" SG_ 2550071313 RWA_GST_Byte6 "TP Index : 340";
BA_ "UsrSigPurpose" SG_ 2550071313 RWA_GST_Byte6 4;
BA_ "UserSigValidity" SG_ 2550071313 RWA_GST_Byte6 0;
BA_ "Version" SG_ 2550071313 RWA_GST_Byte6 "23.06.01";
BA_ "Description" SG_ 2550071313 RWA_GST_Byte7 "TP Index : 340";
BA_ "UsrSigPurpose" SG_ 2550071313 RWA_GST_Byte7 4;
BA_ "UserSigValidity" SG_ 2550071313 RWA_GST_Byte7 0;
BA_ "Version" SG_ 2550071313 RWA_GST_Byte7 "23.06.01";
BA_ "Description" SG_ 2550071313 RWA_GST_Byte1 "TP Index : 340";
BA_ "UsrSigPurpose" SG_ 2550071313 RWA_GST_Byte1 4;
BA_ "UserSigValidity" SG_ 2550071313 RWA_GST_Byte1 0;
BA_ "Version" SG_ 2550071313 RWA_GST_Byte1 "23.06.01";
BA_ "Description" SG_ 811 SBCM_AST_FD_Crc1Val "The data area for CRC calculation is based on the data length (DLC) of the message DB.

The CRC shall be calculated over the entire data block (excluding the CRC bytes) including the user data, alive counter and Data ID


- CRC Polynomial (0x1021) , Ini";
BA_ "GenSigSendType" SG_ 811 SBCM_AST_FD_Crc1Val 4;
BA_ "GenSigStartValue" SG_ 811 SBCM_AST_FD_Crc1Val 65535;
BA_ "UserSigValidity" SG_ 811 SBCM_AST_FD_Crc1Val 3;
BA_ "Version" SG_ 811 SBCM_AST_FD_Crc1Val "22.10.20";
BA_ "Description" SG_ 811 SBCM_AST_FD_AlvCnt1Val "For the first transmission request for a data element the counter shall be initialized with 0 and shall be incremented by 1 for every subsequent send request. 
When the counter reaches the maximum value(0xFF), then it shall restart with 0 for the next s";
BA_ "GenSigSendType" SG_ 811 SBCM_AST_FD_AlvCnt1Val 4;
BA_ "UserSigValidity" SG_ 811 SBCM_AST_FD_AlvCnt1Val 3;
BA_ "Version" SG_ 811 SBCM_AST_FD_AlvCnt1Val "22.10.20";
BA_ "Description" SG_ 811 Warn_AsstDrSwSta_SBCM "Warning Assist Door Switch Status";
BA_ "GenSigSendType" SG_ 811 Warn_AsstDrSwSta_SBCM 4;
BA_ "UserSigValidity" SG_ 811 Warn_AsstDrSwSta_SBCM 0;
BA_ "NetworkRequest" SG_ 811 Warn_AsstDrSwSta_SBCM 0;
BA_ "Version" SG_ 811 Warn_AsstDrSwSta_SBCM "21.09.05";
BA_ "Description" SG_ 288 MCU_Crc2Val "The data area for CRC calculation is based on the data length (DLC) of the message DB.

The CRC shall be calculated over the entire data block (excluding the CRC bytes) including the user data, alive counter and Data ID



- CRC Polynomial (0x1021) , Ini";
BA_ "GenSigStartValue" SG_ 288 MCU_Crc2Val 65535;
BA_ "UserSigValidity" SG_ 288 MCU_Crc2Val 7;
BA_ "RoutingFactor" SG_ 288 MCU_Crc2Val 50;
BA_ "Version" SG_ 288 MCU_Crc2Val "21.12.05";
BA_ "Description" SG_ 288 MCU_AlvCnt2Val "For the first transmission request for a data element the counter shall be initialized with 0 and shall be incremented by 1 for every subsequent send request. 

When the counter reaches the maximum value(0xFF), then it shall restart with 0 for the next s";
BA_ "UserSigValidity" SG_ 288 MCU_AlvCnt2Val 7;
BA_ "RoutingFactor" SG_ 288 MCU_AlvCnt2Val 50;
BA_ "Version" SG_ 288 MCU_AlvCnt2Val "21.12.05";
BA_ "Description" SG_ 288 MCU_Mg2EstTqVal "HEV : MG2 - HSG, HSCAN -  X

EV : MG2 - Sub Axle, HSCAN - X";
BA_ "UserSigValidity" SG_ 288 MCU_Mg2EstTqVal 7;
BA_ "RoutingFactor" SG_ 288 MCU_Mg2EstTqVal 50;
BA_ "Version" SG_ 288 MCU_Mg2EstTqVal "19.04.04";
BA_ "Description" SG_ 288 MCU_Mg2EstTqPcVal "HEV : MG2 - HSG, HSCAN -  CR_Gcu_HsgEstTq_Pc

EV : MG2 - Sub Axle, HSCAN - X";
BA_ "UserSigValidity" SG_ 288 MCU_Mg2EstTqPcVal 7;
BA_ "RoutingFactor" SG_ 288 MCU_Mg2EstTqPcVal 50;
BA_ "Version" SG_ 288 MCU_Mg2EstTqPcVal "19.04.04";
BA_ "Description" SG_ 293 SAS_Crc1Val "The data area for CRC calculation is based on the data length (DLC) of the message DB.

The CRC shall be calculated over the entire data block (excluding the CRC bytes) including the user data, alive counter and Data ID

 

- CRC Polynomial (0x1021) , In";
BA_ "GenSigStartValue" SG_ 293 SAS_Crc1Val 65535;
BA_ "UserSigValidity" SG_ 293 SAS_Crc1Val 3;
BA_ "RoutingFactor" SG_ 293 SAS_Crc1Val 5;
BA_ "Version" SG_ 293 SAS_Crc1Val "18.11.08";
BA_ "Description" SG_ 293 SAS_AlvCnt1Val "For the first transmission request for a data element the counter shall be initialized with 0 and shall be incremented by 1 for every subsequent send request. 

When the counter reaches the maximum value(0xFF), then it shall restart with 0 for the next s";
BA_ "UserSigValidity" SG_ 293 SAS_AlvCnt1Val 3;
BA_ "RoutingFactor" SG_ 293 SAS_AlvCnt1Val 5;
BA_ "Version" SG_ 293 SAS_AlvCnt1Val "18.11.08";
BA_ "Description" SG_ 293 SAS_AnglVal "Information regarding the steering wheel angle.  (PH) = (HEX) * 0.1 (0 <  HEX < 7FFFH) or (PH) = (HEX - 65536) * 0.1 (HEX > 7FFFH)



this signal has direction information.

'+' Value means Counter clock wise rotation.

'-' value means Clock wise rotatio";
BA_ "GenSigStartValue" SG_ 293 SAS_AnglVal 32767;
BA_ "UserSigValidity" SG_ 293 SAS_AnglVal 3;
BA_ "RoutingFactor" SG_ 293 SAS_AnglVal 5;
BA_ "Version" SG_ 293 SAS_AnglVal "21.07.05";
BA_ "Description" SG_ 293 SAS_SpdVal "Information regarding the steering wheel rotation speed 

(PH) = (HEX) * 4 (0 �� HEX < 254)";
BA_ "GenSigStartValue" SG_ 293 SAS_SpdVal 255;
BA_ "UserSigValidity" SG_ 293 SAS_SpdVal 3;
BA_ "RoutingFactor" SG_ 293 SAS_SpdVal 5;
BA_ "Version" SG_ 293 SAS_SpdVal "21.07.05";
BA_ "Description" SG_ 293 SAS_IntSta "Information regarding the steering angle sensor��s internal state. If SAS_AnglVal value is O.K., SAS_OK flag is set and otherwise SAS_OK flag is cleared. If steering angle sensor has been calibrated, SAS_CAL flag is set and otherwise cleared.

SF1 - SF5 ";
BA_ "GenSigStartValue" SG_ 293 SAS_IntSta 14;
BA_ "UserSigValidity" SG_ 293 SAS_IntSta 3;
BA_ "RoutingFactor" SG_ 293 SAS_IntSta 5;
BA_ "Version" SG_ 293 SAS_IntSta "21.07.05";
BA_ "Description" SG_ 2550075648 GST_RWA_Byte0 "TP Index : 340";
BA_ "UsrSigPurpose" SG_ 2550075648 GST_RWA_Byte0 3;
BA_ "UserSigValidity" SG_ 2550075648 GST_RWA_Byte0 0;
BA_ "NetworkRequest" SG_ 2550075648 GST_RWA_Byte0 0;
BA_ "NetworkRequestHoldingTime" SG_ 2550075648 GST_RWA_Byte0 5000;
BA_ "Version" SG_ 2550075648 GST_RWA_Byte0 "23.06.01";
BA_ "Description" SG_ 2550075648 GST_RWA_Byte2 "TP Index : 340";
BA_ "UsrSigPurpose" SG_ 2550075648 GST_RWA_Byte2 3;
BA_ "UserSigValidity" SG_ 2550075648 GST_RWA_Byte2 0;
BA_ "NetworkRequest" SG_ 2550075648 GST_RWA_Byte2 0;
BA_ "NetworkRequestHoldingTime" SG_ 2550075648 GST_RWA_Byte2 5000;
BA_ "Version" SG_ 2550075648 GST_RWA_Byte2 "23.06.01";
BA_ "Description" SG_ 2550075648 GST_RWA_Byte3 "TP Index : 340";
BA_ "UsrSigPurpose" SG_ 2550075648 GST_RWA_Byte3 3;
BA_ "UserSigValidity" SG_ 2550075648 GST_RWA_Byte3 0;
BA_ "NetworkRequest" SG_ 2550075648 GST_RWA_Byte3 0;
BA_ "NetworkRequestHoldingTime" SG_ 2550075648 GST_RWA_Byte3 5000;
BA_ "Version" SG_ 2550075648 GST_RWA_Byte3 "23.06.01";
BA_ "Description" SG_ 2550075648 GST_RWA_Byte4 "TP Index : 340";
BA_ "UsrSigPurpose" SG_ 2550075648 GST_RWA_Byte4 3;
BA_ "UserSigValidity" SG_ 2550075648 GST_RWA_Byte4 0;
BA_ "NetworkRequest" SG_ 2550075648 GST_RWA_Byte4 0;
BA_ "NetworkRequestHoldingTime" SG_ 2550075648 GST_RWA_Byte4 5000;
BA_ "Version" SG_ 2550075648 GST_RWA_Byte4 "23.06.01";
BA_ "Description" SG_ 2550075648 GST_RWA_Byte5 "TP Index : 340";
BA_ "UsrSigPurpose" SG_ 2550075648 GST_RWA_Byte5 3;
BA_ "UserSigValidity" SG_ 2550075648 GST_RWA_Byte5 0;
BA_ "NetworkRequest" SG_ 2550075648 GST_RWA_Byte5 0;
BA_ "NetworkRequestHoldingTime" SG_ 2550075648 GST_RWA_Byte5 5000;
BA_ "Version" SG_ 2550075648 GST_RWA_Byte5 "23.06.01";
BA_ "Description" SG_ 2550075648 GST_RWA_Byte6 "TP Index : 340";
BA_ "UsrSigPurpose" SG_ 2550075648 GST_RWA_Byte6 3;
BA_ "UserSigValidity" SG_ 2550075648 GST_RWA_Byte6 0;
BA_ "NetworkRequest" SG_ 2550075648 GST_RWA_Byte6 0;
BA_ "NetworkRequestHoldingTime" SG_ 2550075648 GST_RWA_Byte6 5000;
BA_ "Version" SG_ 2550075648 GST_RWA_Byte6 "23.06.01";
BA_ "Description" SG_ 2550075648 GST_RWA_Byte7 "TP Index : 340";
BA_ "UsrSigPurpose" SG_ 2550075648 GST_RWA_Byte7 3;
BA_ "UserSigValidity" SG_ 2550075648 GST_RWA_Byte7 0;
BA_ "NetworkRequest" SG_ 2550075648 GST_RWA_Byte7 0;
BA_ "NetworkRequestHoldingTime" SG_ 2550075648 GST_RWA_Byte7 5000;
BA_ "Version" SG_ 2550075648 GST_RWA_Byte7 "23.06.01";
BA_ "Description" SG_ 2550075648 GST_RWA_Byte1 "TP Index : 340";
BA_ "UsrSigPurpose" SG_ 2550075648 GST_RWA_Byte1 3;
BA_ "UserSigValidity" SG_ 2550075648 GST_RWA_Byte1 0;
BA_ "NetworkRequest" SG_ 2550075648 GST_RWA_Byte1 0;
BA_ "NetworkRequestHoldingTime" SG_ 2550075648 GST_RWA_Byte1 5000;
BA_ "Version" SG_ 2550075648 GST_RWA_Byte1 "23.06.01";
BA_ "Description" SG_ 298 ADAS_CMD_Crc30Val "The data area for CRC calculation is based on the data length (DLC) of the message DB.

The CRC shall be calculated over the entire data block (excluding the CRC bytes) including the user data, alive counter and Data ID



- CRC Polynomial (0x1021) , Ini";
BA_ "GenSigStartValue" SG_ 298 ADAS_CMD_Crc30Val 65535;
BA_ "UserSigValidity" SG_ 298 ADAS_CMD_Crc30Val 3;
BA_ "RoutingFactor" SG_ 298 ADAS_CMD_Crc30Val 5;
BA_ "Version" SG_ 298 ADAS_CMD_Crc30Val "21.09.03";
BA_ "Description" SG_ 298 ADAS_Damping_Gain "ADAS Damping Gain for MDPS";
BA_ "GenSigStartValue" SG_ 298 ADAS_Damping_Gain 100;
BA_ "UserSigValidity" SG_ 298 ADAS_Damping_Gain 3;
BA_ "RoutingFactor" SG_ 298 ADAS_Damping_Gain 5;
BA_ "Version" SG_ 298 ADAS_Damping_Gain "18.12.01";
BA_ "Description" SG_ 298 ADAS_CMD_AlvCnt30Val "For the first transmission request for a data element the counter shall be initialized with 0 and shall be incremented by 1 for every subsequent send request. 

When the counter reaches the maximum value(0xFF), then it shall restart with 0 for the next s";
BA_ "UserSigValidity" SG_ 298 ADAS_CMD_AlvCnt30Val 3;
BA_ "RoutingFactor" SG_ 298 ADAS_CMD_AlvCnt30Val 5;
BA_ "Version" SG_ 298 ADAS_CMD_AlvCnt30Val "21.09.03";
BA_ "Description" SG_ 298 ADAS_StrTqReqVal "This is the driver torque overlay demand value. A negative value represents a torque that would accelerate the steering wheel in a clockwise direction. This signal is always zero whilst the TOI is inactive.";
BA_ "GenSigStartValue" SG_ 298 ADAS_StrTqReqVal 1024;
BA_ "UserSigValidity" SG_ 298 ADAS_StrTqReqVal 3;
BA_ "RoutingFactor" SG_ 298 ADAS_StrTqReqVal 5;
BA_ "Version" SG_ 298 ADAS_StrTqReqVal "18.10.00";
BA_ "Description" SG_ 298 ADAS_ActToiSta "This is a flag that is set to 1 when requesting the steering to activate the torque overlay interface (TOI).  This must be done before an attempt is made to request non-zero steering torque overlay.";
BA_ "UserSigValidity" SG_ 298 ADAS_ActToiSta 3;
BA_ "RoutingFactor" SG_ 298 ADAS_ActToiSta 5;
BA_ "Version" SG_ 298 ADAS_ActToiSta "18.12.07";
BA_ "Description" SG_ 298 ADAS_ToiFltSta "This fault flag is set when a fault in the LKA system has been detected by the LKA ECU such that LKA can no longer function. CAN failures, internal video ECU failures, hard-wired component (e.g. master switch) failures and other system logic failures are";
BA_ "UserSigValidity" SG_ 298 ADAS_ToiFltSta 3;
BA_ "RoutingFactor" SG_ 298 ADAS_ToiFltSta 5;
BA_ "Version" SG_ 298 ADAS_ToiFltSta "18.12.07";
BA_ "Description" SG_ 374 RCU_Crc3Val "The data area for CRC calculation is based on the data length (DLC) of the message DB.

The CRC shall be calculated over the entire data block (excluding the CRC bytes) including the user data, alive counter and Data ID



- CRC Polynomial (0x1021) , Ini";
BA_ "GenSigStartValue" SG_ 374 RCU_Crc3Val 65535;
BA_ "UserSigValidity" SG_ 374 RCU_Crc3Val 3;
BA_ "RoutingFactor" SG_ 374 RCU_Crc3Val 5;
BA_ "Version" SG_ 374 RCU_Crc3Val "22.01.00";
BA_ "Description" SG_ 374 RCU_AlvCnt3Val "For the first transmission request for a data element the counter shall be initialized with 0 and shall be incremented by 1 for every subsequent send request. 

When the counter reaches the maximum value(0xFF), then it shall restart with 0 for the next s";
BA_ "UserSigValidity" SG_ 374 RCU_AlvCnt3Val 3;
BA_ "RoutingFactor" SG_ 374 RCU_AlvCnt3Val 5;
BA_ "Version" SG_ 374 RCU_AlvCnt3Val "22.01.00";
BA_ "Description" SG_ 374 RCU_HDP_EgSta "This signal is the information which of the HDP controllers (Main/Sub) the IEB (ESC)/RCU is engaged.";
BA_ "UserSigValidity" SG_ 374 RCU_HDP_EgSta 0;
BA_ "RoutingFactor" SG_ 374 RCU_HDP_EgSta 5;
BA_ "Version" SG_ 374 RCU_HDP_EgSta "22.05.03";
BA_ "Description" SG_ 357 ADAS_PRK_Crc2Val "The data area for CRC calculation is based on the data length (DLC) of the message DB.

The CRC shall be calculated over the entire data block (excluding the CRC bytes) including the user data, alive counter and Data ID



- CRC Polynomial (0x1021) , Ini";
BA_ "GenSigStartValue" SG_ 357 ADAS_PRK_Crc2Val 65535;
BA_ "UserSigValidity" SG_ 357 ADAS_PRK_Crc2Val 3;
BA_ "RoutingFactor" SG_ 357 ADAS_PRK_Crc2Val 5;
BA_ "Version" SG_ 357 ADAS_PRK_Crc2Val "21.09.03";
BA_ "Description" SG_ 357 ADAS_PRK_AlvCnt2Val "For the first transmission request for a data element the counter shall be initialized with 0 and shall be incremented by 1 for every subsequent send request. 

When the counter reaches the maximum value(0xFF), then it shall restart with 0 for the next s";
BA_ "UserSigValidity" SG_ 357 ADAS_PRK_AlvCnt2Val 3;
BA_ "RoutingFactor" SG_ 357 ADAS_PRK_AlvCnt2Val 5;
BA_ "Version" SG_ 357 ADAS_PRK_AlvCnt2Val "21.09.03";
BA_ "Description" SG_ 357 PA_RSPA_Opt "0x0: PA & RSPA (ENTRY) & RSPA ��� �� MDPS ���� ���� �ʿ� ��� ������ ��,

        ��ȣ�� '0x0' ����.  

0x1: PA or RSPA (ENTRY) or RSPA �� MDPS ���� ���� �ʿ� ��� ���� ��, 

        ��ȣ�� '0x1' ����.";
BA_ "UserSigValidity" SG_ 357 PA_RSPA_Opt 3;
BA_ "RoutingFactor" SG_ 357 PA_RSPA_Opt 5;
BA_ "Version" SG_ 357 PA_RSPA_Opt "19.12.01";
BA_ "Description" SG_ 357 PA_Sta "This signal indicates the status of the PA steering activation machine. 



 <Fuction>

0H : Reserved

1H : Initial value after ignition

2H : Request of a new start status after an abort of the MDPS

3H : StandBy status of the PA function. No error and ";
BA_ "GenSigStartValue" SG_ 357 PA_Sta 1;
BA_ "UserSigValidity" SG_ 357 PA_Sta 3;
BA_ "RoutingFactor" SG_ 357 PA_Sta 5;
BA_ "Version" SG_ 357 PA_Sta "17.12.03";
BA_ "Description" SG_ 357 PA_TestModSta "This signal indicates the status of the �� MDPS Activation control for testing the PA system��";
BA_ "UserSigValidity" SG_ 357 PA_TestModSta 3;
BA_ "RoutingFactor" SG_ 357 PA_TestModSta 5;
BA_ "Version" SG_ 357 PA_TestModSta "17.11.00";
BA_ "Description" SG_ 357 PA_StrAnglReq "This value is used to set a steering wheel position target for the PA function. The signal is signed 16bits.



Conversion: (PH) = (HEX) x 0.1 (for 0< HEX < 32767) OR

(HEX - 65536) x 0.1 (for HEX > 32767)";
BA_ "UserSigValidity" SG_ 357 PA_StrAnglReq 3;
BA_ "RoutingFactor" SG_ 357 PA_StrAnglReq 5;
BA_ "Version" SG_ 357 PA_StrAnglReq "17.11.00";
BA_ "Description" SG_ 358 CDCU_TPA_Crc1Val "The data area for CRC calculation is based on the data length (DLC) of the message DB.

The CRC shall be calculated over the entire data block (excluding the CRC bytes) including the user data, alive counter and Data ID



- CRC Polynomial (0x1021) , Ini";
BA_ "GenSigStartValue" SG_ 358 CDCU_TPA_Crc1Val 65535;
BA_ "UserSigValidity" SG_ 358 CDCU_TPA_Crc1Val 3;
BA_ "RoutingFactor" SG_ 358 CDCU_TPA_Crc1Val 5;
BA_ "Version" SG_ 358 CDCU_TPA_Crc1Val "21.11.07";
BA_ "Description" SG_ 358 CDCU_TPA_AlvCnt1Val "For the first transmission request for a data element the counter shall be initialized with 0 and shall be incremented by 1 for every subsequent send request. 

When the counter reaches the maximum value(0xFF), then it shall restart with 0 for the next s";
BA_ "UserSigValidity" SG_ 358 CDCU_TPA_AlvCnt1Val 3;
BA_ "RoutingFactor" SG_ 358 CDCU_TPA_AlvCnt1Val 5;
BA_ "Version" SG_ 358 CDCU_TPA_AlvCnt1Val "21.11.07";
BA_ "Description" SG_ 358 CDCU_TPA_Opt "0x0: TPA not applied/0x1: TPA applied";
BA_ "UserSigValidity" SG_ 358 CDCU_TPA_Opt 3;
BA_ "RoutingFactor" SG_ 358 CDCU_TPA_Opt 5;
BA_ "Version" SG_ 358 CDCU_TPA_Opt "22.07.06";
BA_ "Description" SG_ 358 CDCU_TPA_Sta "This signal indicates the status of the TPA steering activation machine. 



 <Fuction>

0H : Reserved

1H : Initial value after ignition

2H : Request of a new start status after an abort of the MDPS

3H : StandBy status of the TPA function. No error an";
BA_ "GenSigStartValue" SG_ 358 CDCU_TPA_Sta 1;
BA_ "UserSigValidity" SG_ 358 CDCU_TPA_Sta 3;
BA_ "RoutingFactor" SG_ 358 CDCU_TPA_Sta 5;
BA_ "Version" SG_ 358 CDCU_TPA_Sta "22.07.06";
BA_ "Description" SG_ 358 CDCU_TPA_StrAnglReq "This value is used to set a steering wheel position target for the TPA function. The signal is signed 16bits.



Conversion: (PH) = (HEX) x 0.1 (for 0< HEX < 32767) OR

(HEX - 65536) x 0.1 (for HEX > 32767)";
BA_ "UserSigValidity" SG_ 358 CDCU_TPA_StrAnglReq 3;
BA_ "RoutingFactor" SG_ 358 CDCU_TPA_StrAnglReq 5;
BA_ "Version" SG_ 358 CDCU_TPA_StrAnglReq "22.08.00";
BA_ "Description" SG_ 405 ADAS_CMD_Crc33Val "The data area for CRC calculation is based on the data length (DLC) of the message DB.

The CRC shall be calculated over the entire data block (excluding the CRC bytes) including the user data, alive counter and Data ID

 

- CRC Polynomial (0x1021) , In";
BA_ "GenSigStartValue" SG_ 405 ADAS_CMD_Crc33Val 65535;
BA_ "UserSigValidity" SG_ 405 ADAS_CMD_Crc33Val 3;
BA_ "Version" SG_ 405 ADAS_CMD_Crc33Val "20.10.02";
BA_ "Description" SG_ 405 HDP_RDD_StrAnglReqVal "Request angle control value";
BA_ "UserSigValidity" SG_ 405 HDP_RDD_StrAnglReqVal 3;
BA_ "Version" SG_ 405 HDP_RDD_StrAnglReqVal "21.04.00";
BA_ "Description" SG_ 405 ADAS_CMD_AlvCnt33Val "For the first transmission request for a data element the counter shall be initialized with 0 and shall be incremented by 1 for every subsequent send request. 

When the counter reaches the maximum value(0xFF), then it shall restart with 0 for the next s";
BA_ "UserSigValidity" SG_ 405 ADAS_CMD_AlvCnt33Val 3;
BA_ "Version" SG_ 405 ADAS_CMD_AlvCnt33Val "20.10.02";
BA_ "Description" SG_ 405 HDP_RDD_ACIAnglTqRedcGainVal "Angle Torque Reduction Gain";
BA_ "UserSigValidity" SG_ 405 HDP_RDD_ACIAnglTqRedcGainVal 3;
BA_ "Version" SG_ 405 HDP_RDD_ACIAnglTqRedcGainVal "21.11.05";
BA_ "Description" SG_ 405 HDP_RDD_ACIFltSta "This fault flag is set when a fault in the HDP system has been detected by the Front Camera ECU such that HDP can no longer function. CAN failures, internal video ECU failures, hard-wired component (e.g. master switch) failures and other system logic fai";
BA_ "UserSigValidity" SG_ 405 HDP_RDD_ACIFltSta 3;
BA_ "Version" SG_ 405 HDP_RDD_ACIFltSta "21.04.03";
BA_ "Description" SG_ 405 HDP_RDD_ACIActvSta "State for angle control";
BA_ "UserSigValidity" SG_ 405 HDP_RDD_ACIActvSta 3;
BA_ "Version" SG_ 405 HDP_RDD_ACIActvSta "22.01.00";
BA_ "Description" SG_ 2004 GST_MDPS_SFA_Byte0 "TP Index : 146";
BA_ "UsrSigPurpose" SG_ 2004 GST_MDPS_SFA_Byte0 3;
BA_ "UserSigValidity" SG_ 2004 GST_MDPS_SFA_Byte0 0;
BA_ "NetworkRequest" SG_ 2004 GST_MDPS_SFA_Byte0 0;
BA_ "NetworkRequestHoldingTime" SG_ 2004 GST_MDPS_SFA_Byte0 5000;
BA_ "Version" SG_ 2004 GST_MDPS_SFA_Byte0 "23.04.01";
BA_ "Description" SG_ 2004 GST_MDPS_SFA_Byte2 "TP Index : 146";
BA_ "UsrSigPurpose" SG_ 2004 GST_MDPS_SFA_Byte2 3;
BA_ "UserSigValidity" SG_ 2004 GST_MDPS_SFA_Byte2 0;
BA_ "NetworkRequest" SG_ 2004 GST_MDPS_SFA_Byte2 0;
BA_ "NetworkRequestHoldingTime" SG_ 2004 GST_MDPS_SFA_Byte2 5000;
BA_ "Version" SG_ 2004 GST_MDPS_SFA_Byte2 "23.04.01";
BA_ "Description" SG_ 2004 GST_MDPS_SFA_Byte3 "TP Index : 146";
BA_ "UsrSigPurpose" SG_ 2004 GST_MDPS_SFA_Byte3 3;
BA_ "UserSigValidity" SG_ 2004 GST_MDPS_SFA_Byte3 0;
BA_ "NetworkRequest" SG_ 2004 GST_MDPS_SFA_Byte3 0;
BA_ "NetworkRequestHoldingTime" SG_ 2004 GST_MDPS_SFA_Byte3 5000;
BA_ "Version" SG_ 2004 GST_MDPS_SFA_Byte3 "23.04.01";
BA_ "Description" SG_ 2004 GST_MDPS_SFA_Byte4 "TP Index : 146";
BA_ "UsrSigPurpose" SG_ 2004 GST_MDPS_SFA_Byte4 3;
BA_ "UserSigValidity" SG_ 2004 GST_MDPS_SFA_Byte4 0;
BA_ "NetworkRequest" SG_ 2004 GST_MDPS_SFA_Byte4 0;
BA_ "NetworkRequestHoldingTime" SG_ 2004 GST_MDPS_SFA_Byte4 5000;
BA_ "Version" SG_ 2004 GST_MDPS_SFA_Byte4 "23.04.01";
BA_ "Description" SG_ 2004 GST_MDPS_SFA_Byte5 "TP Index : 146";
BA_ "UsrSigPurpose" SG_ 2004 GST_MDPS_SFA_Byte5 3;
BA_ "UserSigValidity" SG_ 2004 GST_MDPS_SFA_Byte5 0;
BA_ "NetworkRequest" SG_ 2004 GST_MDPS_SFA_Byte5 0;
BA_ "NetworkRequestHoldingTime" SG_ 2004 GST_MDPS_SFA_Byte5 5000;
BA_ "Version" SG_ 2004 GST_MDPS_SFA_Byte5 "23.04.01";
BA_ "Description" SG_ 2004 GST_MDPS_SFA_Byte6 "TP Index : 146";
BA_ "UsrSigPurpose" SG_ 2004 GST_MDPS_SFA_Byte6 3;
BA_ "UserSigValidity" SG_ 2004 GST_MDPS_SFA_Byte6 0;
BA_ "NetworkRequest" SG_ 2004 GST_MDPS_SFA_Byte6 0;
BA_ "NetworkRequestHoldingTime" SG_ 2004 GST_MDPS_SFA_Byte6 5000;
BA_ "Version" SG_ 2004 GST_MDPS_SFA_Byte6 "23.04.01";
BA_ "Description" SG_ 2004 GST_MDPS_SFA_Byte7 "TP Index : 146";
BA_ "UsrSigPurpose" SG_ 2004 GST_MDPS_SFA_Byte7 3;
BA_ "UserSigValidity" SG_ 2004 GST_MDPS_SFA_Byte7 0;
BA_ "NetworkRequest" SG_ 2004 GST_MDPS_SFA_Byte7 0;
BA_ "NetworkRequestHoldingTime" SG_ 2004 GST_MDPS_SFA_Byte7 5000;
BA_ "Version" SG_ 2004 GST_MDPS_SFA_Byte7 "23.04.01";
BA_ "Description" SG_ 2004 GST_MDPS_SFA_Byte1 "TP Index : 146";
BA_ "UsrSigPurpose" SG_ 2004 GST_MDPS_SFA_Byte1 3;
BA_ "UserSigValidity" SG_ 2004 GST_MDPS_SFA_Byte1 0;
BA_ "NetworkRequest" SG_ 2004 GST_MDPS_SFA_Byte1 0;
BA_ "NetworkRequestHoldingTime" SG_ 2004 GST_MDPS_SFA_Byte1 5000;
BA_ "Version" SG_ 2004 GST_MDPS_SFA_Byte1 "23.04.01";
BA_ "Description" SG_ 2015 GST_ALL_Byte0 "TP Index : 0";
BA_ "UsrSigPurpose" SG_ 2015 GST_ALL_Byte0 5;
BA_ "UserSigValidity" SG_ 2015 GST_ALL_Byte0 0;
BA_ "NetworkRequest" SG_ 2015 GST_ALL_Byte0 0;
BA_ "NetworkRequestHoldingTime" SG_ 2015 GST_ALL_Byte0 5000;
BA_ "Version" SG_ 2015 GST_ALL_Byte0 "22.06.01";
BA_ "Description" SG_ 2015 GST_ALL_Byte2 "TP Index : 0";
BA_ "UsrSigPurpose" SG_ 2015 GST_ALL_Byte2 5;
BA_ "UserSigValidity" SG_ 2015 GST_ALL_Byte2 0;
BA_ "NetworkRequest" SG_ 2015 GST_ALL_Byte2 0;
BA_ "NetworkRequestHoldingTime" SG_ 2015 GST_ALL_Byte2 5000;
BA_ "Version" SG_ 2015 GST_ALL_Byte2 "22.06.01";
BA_ "Description" SG_ 2015 GST_ALL_Byte3 "TP Index : 0";
BA_ "UsrSigPurpose" SG_ 2015 GST_ALL_Byte3 5;
BA_ "UserSigValidity" SG_ 2015 GST_ALL_Byte3 0;
BA_ "NetworkRequest" SG_ 2015 GST_ALL_Byte3 0;
BA_ "NetworkRequestHoldingTime" SG_ 2015 GST_ALL_Byte3 5000;
BA_ "Version" SG_ 2015 GST_ALL_Byte3 "22.06.01";
BA_ "Description" SG_ 2015 GST_ALL_Byte4 "TP Index : 0";
BA_ "UsrSigPurpose" SG_ 2015 GST_ALL_Byte4 5;
BA_ "UserSigValidity" SG_ 2015 GST_ALL_Byte4 0;
BA_ "NetworkRequest" SG_ 2015 GST_ALL_Byte4 0;
BA_ "NetworkRequestHoldingTime" SG_ 2015 GST_ALL_Byte4 5000;
BA_ "Version" SG_ 2015 GST_ALL_Byte4 "22.06.01";
BA_ "Description" SG_ 2015 GST_ALL_Byte5 "TP Index : 0";
BA_ "UsrSigPurpose" SG_ 2015 GST_ALL_Byte5 5;
BA_ "UserSigValidity" SG_ 2015 GST_ALL_Byte5 0;
BA_ "NetworkRequest" SG_ 2015 GST_ALL_Byte5 0;
BA_ "NetworkRequestHoldingTime" SG_ 2015 GST_ALL_Byte5 5000;
BA_ "Version" SG_ 2015 GST_ALL_Byte5 "22.06.01";
BA_ "Description" SG_ 2015 GST_ALL_Byte6 "TP Index : 0";
BA_ "UsrSigPurpose" SG_ 2015 GST_ALL_Byte6 5;
BA_ "UserSigValidity" SG_ 2015 GST_ALL_Byte6 0;
BA_ "NetworkRequest" SG_ 2015 GST_ALL_Byte6 0;
BA_ "NetworkRequestHoldingTime" SG_ 2015 GST_ALL_Byte6 5000;
BA_ "Version" SG_ 2015 GST_ALL_Byte6 "22.06.01";
BA_ "Description" SG_ 2015 GST_ALL_Byte7 "TP Index : 0";
BA_ "UsrSigPurpose" SG_ 2015 GST_ALL_Byte7 5;
BA_ "UserSigValidity" SG_ 2015 GST_ALL_Byte7 0;
BA_ "NetworkRequest" SG_ 2015 GST_ALL_Byte7 0;
BA_ "NetworkRequestHoldingTime" SG_ 2015 GST_ALL_Byte7 5000;
BA_ "Version" SG_ 2015 GST_ALL_Byte7 "22.06.01";
BA_ "Description" SG_ 2015 GST_ALL_Byte1 "TP Index : 0";
BA_ "UsrSigPurpose" SG_ 2015 GST_ALL_Byte1 5;
BA_ "UserSigValidity" SG_ 2015 GST_ALL_Byte1 0;
BA_ "NetworkRequest" SG_ 2015 GST_ALL_Byte1 0;
BA_ "NetworkRequestHoldingTime" SG_ 2015 GST_ALL_Byte1 5000;
BA_ "Version" SG_ 2015 GST_ALL_Byte1 "22.06.01";
BA_ "Description" SG_ 2012 MDPS_SFA_GST_Byte0 "TP Index : 146";
BA_ "UsrSigPurpose" SG_ 2012 MDPS_SFA_GST_Byte0 4;
BA_ "UserSigValidity" SG_ 2012 MDPS_SFA_GST_Byte0 0;
BA_ "NetworkRequest" SG_ 2012 MDPS_SFA_GST_Byte0 0;
BA_ "NetworkRequestHoldingTime" SG_ 2012 MDPS_SFA_GST_Byte0 5000;
BA_ "Version" SG_ 2012 MDPS_SFA_GST_Byte0 "23.04.01";
BA_ "Description" SG_ 2012 MDPS_SFA_GST_Byte2 "TP Index : 146";
BA_ "UsrSigPurpose" SG_ 2012 MDPS_SFA_GST_Byte2 4;
BA_ "UserSigValidity" SG_ 2012 MDPS_SFA_GST_Byte2 0;
BA_ "NetworkRequest" SG_ 2012 MDPS_SFA_GST_Byte2 0;
BA_ "NetworkRequestHoldingTime" SG_ 2012 MDPS_SFA_GST_Byte2 5000;
BA_ "Version" SG_ 2012 MDPS_SFA_GST_Byte2 "23.04.01";
BA_ "Description" SG_ 2012 MDPS_SFA_GST_Byte3 "TP Index : 146";
BA_ "UsrSigPurpose" SG_ 2012 MDPS_SFA_GST_Byte3 4;
BA_ "UserSigValidity" SG_ 2012 MDPS_SFA_GST_Byte3 0;
BA_ "NetworkRequest" SG_ 2012 MDPS_SFA_GST_Byte3 0;
BA_ "NetworkRequestHoldingTime" SG_ 2012 MDPS_SFA_GST_Byte3 5000;
BA_ "Version" SG_ 2012 MDPS_SFA_GST_Byte3 "23.04.01";
BA_ "Description" SG_ 2012 MDPS_SFA_GST_Byte4 "TP Index : 146";
BA_ "UsrSigPurpose" SG_ 2012 MDPS_SFA_GST_Byte4 4;
BA_ "UserSigValidity" SG_ 2012 MDPS_SFA_GST_Byte4 0;
BA_ "NetworkRequest" SG_ 2012 MDPS_SFA_GST_Byte4 0;
BA_ "NetworkRequestHoldingTime" SG_ 2012 MDPS_SFA_GST_Byte4 5000;
BA_ "Version" SG_ 2012 MDPS_SFA_GST_Byte4 "23.04.01";
BA_ "Description" SG_ 2012 MDPS_SFA_GST_Byte5 "TP Index : 146";
BA_ "UsrSigPurpose" SG_ 2012 MDPS_SFA_GST_Byte5 4;
BA_ "UserSigValidity" SG_ 2012 MDPS_SFA_GST_Byte5 0;
BA_ "NetworkRequest" SG_ 2012 MDPS_SFA_GST_Byte5 0;
BA_ "NetworkRequestHoldingTime" SG_ 2012 MDPS_SFA_GST_Byte5 5000;
BA_ "Version" SG_ 2012 MDPS_SFA_GST_Byte5 "23.04.01";
BA_ "Description" SG_ 2012 MDPS_SFA_GST_Byte6 "TP Index : 146";
BA_ "UsrSigPurpose" SG_ 2012 MDPS_SFA_GST_Byte6 4;
BA_ "UserSigValidity" SG_ 2012 MDPS_SFA_GST_Byte6 0;
BA_ "NetworkRequest" SG_ 2012 MDPS_SFA_GST_Byte6 0;
BA_ "NetworkRequestHoldingTime" SG_ 2012 MDPS_SFA_GST_Byte6 5000;
BA_ "Version" SG_ 2012 MDPS_SFA_GST_Byte6 "23.04.01";
BA_ "Description" SG_ 2012 MDPS_SFA_GST_Byte7 "TP Index : 146";
BA_ "UsrSigPurpose" SG_ 2012 MDPS_SFA_GST_Byte7 4;
BA_ "UserSigValidity" SG_ 2012 MDPS_SFA_GST_Byte7 0;
BA_ "NetworkRequest" SG_ 2012 MDPS_SFA_GST_Byte7 0;
BA_ "NetworkRequestHoldingTime" SG_ 2012 MDPS_SFA_GST_Byte7 5000;
BA_ "Version" SG_ 2012 MDPS_SFA_GST_Byte7 "23.04.01";
BA_ "Description" SG_ 2012 MDPS_SFA_GST_Byte1 "TP Index : 146";
BA_ "UsrSigPurpose" SG_ 2012 MDPS_SFA_GST_Byte1 4;
BA_ "UserSigValidity" SG_ 2012 MDPS_SFA_GST_Byte1 0;
BA_ "NetworkRequest" SG_ 2012 MDPS_SFA_GST_Byte1 0;
BA_ "NetworkRequestHoldingTime" SG_ 2012 MDPS_SFA_GST_Byte1 5000;
BA_ "Version" SG_ 2012 MDPS_SFA_GST_Byte1 "23.04.01";
BA_ "Description" SG_ 426 CLU_Crc1Val "The data area for CRC calculation is based on the data length (DLC) of the message DB.

The CRC shall be calculated over the entire data block (excluding the CRC bytes) including the user data, alive counter and Data ID



- CRC Polynomial (0x1021) , Ini";
BA_ "GenSigStartValue" SG_ 426 CLU_Crc1Val 65535;
BA_ "UserSigValidity" SG_ 426 CLU_Crc1Val 3;
BA_ "RoutingFactor" SG_ 426 CLU_Crc1Val 5;
BA_ "Version" SG_ 426 CLU_Crc1Val "21.09.03";
BA_ "Description" SG_ 426 CLU_AlvCnt1Val "For the first transmission request for a data element the counter shall be initialized with 0 and shall be incremented by 1 for every subsequent send request. 

When the counter reaches the maximum value(0xFF), then it shall restart with 0 for the next s";
BA_ "UserSigValidity" SG_ 426 CLU_AlvCnt1Val 3;
BA_ "RoutingFactor" SG_ 426 CLU_AlvCnt1Val 5;
BA_ "Version" SG_ 426 CLU_AlvCnt1Val "21.09.03";
BA_ "Description" SG_ 426 CLU_SpdUnitTyp "This signal indicates the unit of the speed displayed in the speedometer.";
BA_ "UserSigValidity" SG_ 426 CLU_SpdUnitTyp 3;
BA_ "RoutingFactor" SG_ 426 CLU_SpdUnitTyp 5;
BA_ "Version" SG_ 426 CLU_SpdUnitTyp "17.11.00";
BA_ "Description" SG_ 426 CLU_DisSpdVal "The vehicle speed which is indicated in the speedmeter has to be sent to SCC. This value is used for evalution of SCC command values instead of the vehicle velocity in order to avoid significant difference between the speedmeter indicator and the set spe";
BA_ "UserSigValidity" SG_ 426 CLU_DisSpdVal 3;
BA_ "RoutingFactor" SG_ 426 CLU_DisSpdVal 5;
BA_ "Version" SG_ 426 CLU_DisSpdVal "17.12.03";
BA_ "Description" SG_ 901 ICSC_Crc3Val "The data area for CRC calculation is based on the data length (DLC) of the message DB.

The CRC shall be calculated over the entire data block (excluding the CRC bytes) including the user data, alive counter and Data ID



- CRC Polynomial (0x1021) , Ini";
BA_ "GenSigStartValue" SG_ 901 ICSC_Crc3Val 65535;
BA_ "UserSigValidity" SG_ 901 ICSC_Crc3Val 3;
BA_ "RoutingFactor" SG_ 901 ICSC_Crc3Val 2;
BA_ "Version" SG_ 901 ICSC_Crc3Val "21.09.03";
BA_ "Description" SG_ 901 ICSC_AlvCnt3Val "For the first transmission request for a data element the counter shall be initialized with 0 and shall be incremented by 1 for every subsequent send request. 

When the counter reaches the maximum value(0xFF), then it shall restart with 0 for the next s";
BA_ "UserSigValidity" SG_ 901 ICSC_AlvCnt3Val 3;
BA_ "RoutingFactor" SG_ 901 ICSC_AlvCnt3Val 2;
BA_ "Version" SG_ 901 ICSC_AlvCnt3Val "21.09.03";
BA_ "Description" SG_ 901 DMIC_OffRdMod "This signal indicates that which offroad mode vehicle drives.";
BA_ "UserSigValidity" SG_ 901 DMIC_OffRdMod 3;
BA_ "RoutingFactor" SG_ 901 DMIC_OffRdMod 2;
BA_ "Version" SG_ 901 DMIC_OffRdMod "23.04.02";
BA_ "Description" SG_ 994 PDC_FD_Crc3Val "The data area for CRC calculation is based on the data length (DLC) of the message DB.

The CRC shall be calculated over the entire data block (excluding the CRC bytes) including the user data, alive counter and Data ID



- CRC Polynomial (0x1021) , Ini";
BA_ "GenSigSendType" SG_ 994 PDC_FD_Crc3Val 4;
BA_ "GenSigStartValue" SG_ 994 PDC_FD_Crc3Val 65535;
BA_ "UserSigValidity" SG_ 994 PDC_FD_Crc3Val 3;
BA_ "Version" SG_ 994 PDC_FD_Crc3Val "22.10.20";
BA_ "Description" SG_ 994 PDC_FD_AlvCnt3Val "For the first transmission request for a data element the counter shall be initialized with 0 and shall be incremented by 1 for every subsequent send request. 

When the counter reaches the maximum value(0xFF), then it shall restart with 0 for the next s";
BA_ "GenSigSendType" SG_ 994 PDC_FD_AlvCnt3Val 4;
BA_ "UserSigValidity" SG_ 994 PDC_FD_AlvCnt3Val 3;
BA_ "Version" SG_ 994 PDC_FD_AlvCnt3Val "22.10.20";
BA_ "GenSigSendType" SG_ 994 Warn_DrvDrSwSta 4;
BA_ "UserSigValidity" SG_ 994 Warn_DrvDrSwSta 0;
BA_ "NetworkRequest" SG_ 994 Warn_DrvDrSwSta 0;
BA_ "NetworkRequestHoldingTime" SG_ 994 Warn_DrvDrSwSta 5000;
BA_ "Version" SG_ 994 Warn_DrvDrSwSta "17.12.00";
BA_ "GenSigSendType" SG_ 994 Warn_AsstDrSwSta 4;
BA_ "UserSigValidity" SG_ 994 Warn_AsstDrSwSta 0;
BA_ "NetworkRequest" SG_ 994 Warn_AsstDrSwSta 0;
BA_ "NetworkRequestHoldingTime" SG_ 994 Warn_AsstDrSwSta 5000;
BA_ "Version" SG_ 994 Warn_AsstDrSwSta "17.12.00";
BA_ "GenSigSendType" SG_ 994 DoorLock_DrvDrUnLkSta 4;
BA_ "UserSigValidity" SG_ 994 DoorLock_DrvDrUnLkSta 0;
BA_ "NetworkRequest" SG_ 994 DoorLock_DrvDrUnLkSta 0;
BA_ "NetworkRequestHoldingTime" SG_ 994 DoorLock_DrvDrUnLkSta 5000;
BA_ "Version" SG_ 994 DoorLock_DrvDrUnLkSta "21.09.05";
BA_ "UsrSigPurpose" SG_ 2549874807 SNI_ECS 8;
BA_ "UserSigValidity" SG_ 2549874807 SNI_ECS 0;
BA_ "UsrSigPurpose" SG_ 2549874807 CBV_RMR_ECS 8;
BA_ "UserSigValidity" SG_ 2549874807 CBV_RMR_ECS 0;
BA_ "UsrSigPurpose" SG_ 2549874807 CBV_NMCoID_ECS 8;
BA_ "UserSigValidity" SG_ 2549874807 CBV_NMCoID_ECS 0;
BA_ "UsrSigPurpose" SG_ 2549874807 CBV_NMCoSRB_ECS 8;
BA_ "UserSigValidity" SG_ 2549874807 CBV_NMCoSRB_ECS 0;
BA_ "UsrSigPurpose" SG_ 2549874807 CBV_AWB_ECS 8;
BA_ "UserSigValidity" SG_ 2549874807 CBV_AWB_ECS 0;
BA_ "UsrSigPurpose" SG_ 2549874807 CBV_PNIB_ECS 8;
BA_ "UserSigValidity" SG_ 2549874807 CBV_PNIB_ECS 0;
BA_ "UsrSigPurpose" SG_ 2549874807 NRR_ECS 8;
BA_ "UserSigValidity" SG_ 2549874807 NRR_ECS 0;
BA_ "UsrSigPurpose" SG_ 2549874807 NM_State_ECS 8;
BA_ "UserSigValidity" SG_ 2549874807 NM_State_ECS 0;
BA_ "UsrSigPurpose" SG_ 2549874807 PNI_ECS 8;
BA_ "UserSigValidity" SG_ 2549874807 PNI_ECS 0;
BA_ "UsrSigPurpose" SG_ 2549874807 PNI_ECS_1 8;
BA_ "UserSigValidity" SG_ 2549874807 PNI_ECS_1 0;
BA_ "UsrSigPurpose" SG_ 2549874807 PNI_ECS_2 8;
BA_ "UserSigValidity" SG_ 2549874807 PNI_ECS_2 0;
BA_ "UsrSigPurpose" SG_ 2549874807 PNI_ECS_3 8;
BA_ "UserSigValidity" SG_ 2549874807 PNI_ECS_3 0;
BA_ "UsrSigPurpose" SG_ 2549874769 SNI_RCU 8;
BA_ "UserSigValidity" SG_ 2549874769 SNI_RCU 0;
BA_ "UsrSigPurpose" SG_ 2549874769 CBV_RMR_RCU 8;
BA_ "UserSigValidity" SG_ 2549874769 CBV_RMR_RCU 0;
BA_ "UsrSigPurpose" SG_ 2549874769 CBV_NMCoID_RCU 8;
BA_ "UserSigValidity" SG_ 2549874769 CBV_NMCoID_RCU 0;
BA_ "UsrSigPurpose" SG_ 2549874769 CBV_NMCoSRB_RCU 8;
BA_ "UserSigValidity" SG_ 2549874769 CBV_NMCoSRB_RCU 0;
BA_ "UsrSigPurpose" SG_ 2549874769 CBV_AWB_RCU 8;
BA_ "UserSigValidity" SG_ 2549874769 CBV_AWB_RCU 0;
BA_ "UsrSigPurpose" SG_ 2549874769 CBV_PNIB_RCU 8;
BA_ "UserSigValidity" SG_ 2549874769 CBV_PNIB_RCU 0;
BA_ "UsrSigPurpose" SG_ 2549874769 NRR_RCU 8;
BA_ "UserSigValidity" SG_ 2549874769 NRR_RCU 0;
BA_ "UsrSigPurpose" SG_ 2549874769 NM_State_RCU 8;
BA_ "UserSigValidity" SG_ 2549874769 NM_State_RCU 0;
BA_ "UsrSigPurpose" SG_ 2549874769 PNI_RCU 8;
BA_ "UserSigValidity" SG_ 2549874769 PNI_RCU 0;
BA_ "UsrSigPurpose" SG_ 2549874769 PNI_RCU_1 8;
BA_ "UserSigValidity" SG_ 2549874769 PNI_RCU_1 0;
BA_ "UsrSigPurpose" SG_ 2549874769 PNI_RCU_2 8;
BA_ "UserSigValidity" SG_ 2549874769 PNI_RCU_2 0;
BA_ "UsrSigPurpose" SG_ 2549874769 PNI_RCU_3 8;
BA_ "UserSigValidity" SG_ 2549874769 PNI_RCU_3 0;
BA_ "UsrSigPurpose" SG_ 2549874805 SNI_ESC 8;
BA_ "UserSigValidity" SG_ 2549874805 SNI_ESC 0;
BA_ "UsrSigPurpose" SG_ 2549874805 CBV_RMR_ESC 8;
BA_ "UserSigValidity" SG_ 2549874805 CBV_RMR_ESC 0;
BA_ "UsrSigPurpose" SG_ 2549874805 CBV_NMCoID_ESC 8;
BA_ "UserSigValidity" SG_ 2549874805 CBV_NMCoID_ESC 0;
BA_ "UsrSigPurpose" SG_ 2549874805 CBV_NMCoSRB_ESC 8;
BA_ "UserSigValidity" SG_ 2549874805 CBV_NMCoSRB_ESC 0;
BA_ "UsrSigPurpose" SG_ 2549874805 CBV_AWB_ESC 8;
BA_ "UserSigValidity" SG_ 2549874805 CBV_AWB_ESC 0;
BA_ "UsrSigPurpose" SG_ 2549874805 CBV_PNIB_ESC 8;
BA_ "UserSigValidity" SG_ 2549874805 CBV_PNIB_ESC 0;
BA_ "UsrSigPurpose" SG_ 2549874805 NRR_ESC 8;
BA_ "UserSigValidity" SG_ 2549874805 NRR_ESC 0;
BA_ "UsrSigPurpose" SG_ 2549874805 NM_State_ESC 8;
BA_ "UserSigValidity" SG_ 2549874805 NM_State_ESC 0;
BA_ "UsrSigPurpose" SG_ 2549874805 PNI_ESC 8;
BA_ "UserSigValidity" SG_ 2549874805 PNI_ESC 0;
BA_ "UsrSigPurpose" SG_ 2549874805 PNI_ESC_1 8;
BA_ "UserSigValidity" SG_ 2549874805 PNI_ESC_1 0;
BA_ "UsrSigPurpose" SG_ 2549874805 PNI_ESC_2 8;
BA_ "UserSigValidity" SG_ 2549874805 PNI_ESC_2 0;
BA_ "UsrSigPurpose" SG_ 2549874805 PNI_ESC_3 8;
BA_ "UserSigValidity" SG_ 2549874805 PNI_ESC_3 0;
BA_ "UsrSigPurpose" SG_ 2549874809 SNI_RWS 8;
BA_ "UserSigValidity" SG_ 2549874809 SNI_RWS 0;
BA_ "UsrSigPurpose" SG_ 2549874809 CBV_RMR_RWS 8;
BA_ "UserSigValidity" SG_ 2549874809 CBV_RMR_RWS 0;
BA_ "UsrSigPurpose" SG_ 2549874809 CBV_NMCoID_RWS 8;
BA_ "UserSigValidity" SG_ 2549874809 CBV_NMCoID_RWS 0;
BA_ "UsrSigPurpose" SG_ 2549874809 CBV_NMCoSRB_RWS 8;
BA_ "UserSigValidity" SG_ 2549874809 CBV_NMCoSRB_RWS 0;
BA_ "UsrSigPurpose" SG_ 2549874809 CBV_AWB_RWS 8;
BA_ "UserSigValidity" SG_ 2549874809 CBV_AWB_RWS 0;
BA_ "UsrSigPurpose" SG_ 2549874809 CBV_PNIB_RWS 8;
BA_ "UserSigValidity" SG_ 2549874809 CBV_PNIB_RWS 0;
BA_ "UsrSigPurpose" SG_ 2549874809 NRR_RWS 8;
BA_ "UserSigValidity" SG_ 2549874809 NRR_RWS 0;
BA_ "UsrSigPurpose" SG_ 2549874809 NM_State_RWS 8;
BA_ "UserSigValidity" SG_ 2549874809 NM_State_RWS 0;
BA_ "UsrSigPurpose" SG_ 2549874809 PNI_RWS 8;
BA_ "UserSigValidity" SG_ 2549874809 PNI_RWS 0;
BA_ "UsrSigPurpose" SG_ 2549874809 PNI_RWS_1 8;
BA_ "UserSigValidity" SG_ 2549874809 PNI_RWS_1 0;
BA_ "UsrSigPurpose" SG_ 2549874809 PNI_RWS_2 8;
BA_ "UserSigValidity" SG_ 2549874809 PNI_RWS_2 0;
BA_ "UsrSigPurpose" SG_ 2549874809 PNI_RWS_3 8;
BA_ "UserSigValidity" SG_ 2549874809 PNI_RWS_3 0;
BA_ "UsrSigPurpose" SG_ 2549874751 SNI_GW_RGW 8;
BA_ "UserSigValidity" SG_ 2549874751 SNI_GW_RGW 0;
BA_ "UsrSigPurpose" SG_ 2549874751 CBV_RMR_GW_RGW 8;
BA_ "UserSigValidity" SG_ 2549874751 CBV_RMR_GW_RGW 0;
BA_ "UsrSigPurpose" SG_ 2549874751 CBV_NMCoID_GW_RGW 8;
BA_ "UserSigValidity" SG_ 2549874751 CBV_NMCoID_GW_RGW 0;
BA_ "UsrSigPurpose" SG_ 2549874751 CBV_NMCoSRB_GW_RGW 8;
BA_ "UserSigValidity" SG_ 2549874751 CBV_NMCoSRB_GW_RGW 0;
BA_ "UsrSigPurpose" SG_ 2549874751 CBV_AWB_GW_RGW 8;
BA_ "UserSigValidity" SG_ 2549874751 CBV_AWB_GW_RGW 0;
BA_ "UsrSigPurpose" SG_ 2549874751 CBV_PNIB_GW_RGW 8;
BA_ "UserSigValidity" SG_ 2549874751 CBV_PNIB_GW_RGW 0;
BA_ "UsrSigPurpose" SG_ 2549874751 NRR_GW_RGW 8;
BA_ "UserSigValidity" SG_ 2549874751 NRR_GW_RGW 0;
BA_ "UsrSigPurpose" SG_ 2549874751 NM_State_GW_RGW 8;
BA_ "UserSigValidity" SG_ 2549874751 NM_State_GW_RGW 0;
BA_ "UsrSigPurpose" SG_ 2549874751 PNI_GW_RGW 8;
BA_ "UserSigValidity" SG_ 2549874751 PNI_GW_RGW 0;
BA_ "UsrSigPurpose" SG_ 2549874751 PNI_GW_RGW_1 8;
BA_ "UserSigValidity" SG_ 2549874751 PNI_GW_RGW_1 0;
BA_ "UsrSigPurpose" SG_ 2549874751 PNI_GW_RGW_2 8;
BA_ "UserSigValidity" SG_ 2549874751 PNI_GW_RGW_2 0;
BA_ "UsrSigPurpose" SG_ 2549874751 PNI_GW_RGW_3 8;
BA_ "UserSigValidity" SG_ 2549874751 PNI_GW_RGW_3 0;
BA_ "UsrSigPurpose" SG_ 2549874786 SNI_EBB 8;
BA_ "UserSigValidity" SG_ 2549874786 SNI_EBB 0;
BA_ "UsrSigPurpose" SG_ 2549874786 CBV_RMR_EBB 8;
BA_ "UserSigValidity" SG_ 2549874786 CBV_RMR_EBB 0;
BA_ "UsrSigPurpose" SG_ 2549874786 CBV_NMCoID_EBB 8;
BA_ "UserSigValidity" SG_ 2549874786 CBV_NMCoID_EBB 0;
BA_ "UsrSigPurpose" SG_ 2549874786 CBV_NMCoSRB_EBB 8;
BA_ "UserSigValidity" SG_ 2549874786 CBV_NMCoSRB_EBB 0;
BA_ "UsrSigPurpose" SG_ 2549874786 CBV_AWB_EBB 8;
BA_ "UserSigValidity" SG_ 2549874786 CBV_AWB_EBB 0;
BA_ "UsrSigPurpose" SG_ 2549874786 CBV_PNIB_EBB 8;
BA_ "UserSigValidity" SG_ 2549874786 CBV_PNIB_EBB 0;
BA_ "UsrSigPurpose" SG_ 2549874786 NRR_EBB 8;
BA_ "UserSigValidity" SG_ 2549874786 NRR_EBB 0;
BA_ "UsrSigPurpose" SG_ 2549874786 NM_State_EBB 8;
BA_ "UserSigValidity" SG_ 2549874786 NM_State_EBB 0;
BA_ "UsrSigPurpose" SG_ 2549874786 PNI_EBB 8;
BA_ "UserSigValidity" SG_ 2549874786 PNI_EBB 0;
BA_ "UsrSigPurpose" SG_ 2549874786 PNI_EBB_1 8;
BA_ "UserSigValidity" SG_ 2549874786 PNI_EBB_1 0;
BA_ "UsrSigPurpose" SG_ 2549874786 PNI_EBB_2 8;
BA_ "UserSigValidity" SG_ 2549874786 PNI_EBB_2 0;
BA_ "UsrSigPurpose" SG_ 2549874786 PNI_EBB_3 8;
BA_ "UserSigValidity" SG_ 2549874786 PNI_EBB_3 0;
BA_ "UsrSigPurpose" SG_ 2549874800 SNI_CGW_CCU 8;
BA_ "UserSigValidity" SG_ 2549874800 SNI_CGW_CCU 0;
BA_ "UsrSigPurpose" SG_ 2549874800 CBV_RMR_CGW_CCU 8;
BA_ "UserSigValidity" SG_ 2549874800 CBV_RMR_CGW_CCU 0;
BA_ "UsrSigPurpose" SG_ 2549874800 CBV_NMCoID_CGW_CCU 8;
BA_ "UserSigValidity" SG_ 2549874800 CBV_NMCoID_CGW_CCU 0;
BA_ "UsrSigPurpose" SG_ 2549874800 CBV_NMCoSRB_CGW_CCU 8;
BA_ "UserSigValidity" SG_ 2549874800 CBV_NMCoSRB_CGW_CCU 0;
BA_ "UsrSigPurpose" SG_ 2549874800 CBV_AWB_CGW_CCU 8;
BA_ "UserSigValidity" SG_ 2549874800 CBV_AWB_CGW_CCU 0;
BA_ "UsrSigPurpose" SG_ 2549874800 CBV_PNIB_CGW_CCU 8;
BA_ "UserSigValidity" SG_ 2549874800 CBV_PNIB_CGW_CCU 0;
BA_ "UsrSigPurpose" SG_ 2549874800 NRR_CGW_CCU 8;
BA_ "UserSigValidity" SG_ 2549874800 NRR_CGW_CCU 0;
BA_ "UsrSigPurpose" SG_ 2549874800 NM_State_CGW_CCU 8;
BA_ "UserSigValidity" SG_ 2549874800 NM_State_CGW_CCU 0;
BA_ "UsrSigPurpose" SG_ 2549874800 PNI_CGW_CCU 8;
BA_ "UserSigValidity" SG_ 2549874800 PNI_CGW_CCU 0;
BA_ "UsrSigPurpose" SG_ 2549874800 PNI_CGW_CCU_1 8;
BA_ "UserSigValidity" SG_ 2549874800 PNI_CGW_CCU_1 0;
BA_ "UsrSigPurpose" SG_ 2549874800 PNI_CGW_CCU_2 8;
BA_ "UserSigValidity" SG_ 2549874800 PNI_CGW_CCU_2 0;
BA_ "UsrSigPurpose" SG_ 2549874800 PNI_CGW_CCU_3 8;
BA_ "UserSigValidity" SG_ 2549874800 PNI_CGW_CCU_3 0;
BA_ "UsrSigPurpose" SG_ 2549874806 SNI_MDPS 8;
BA_ "UserSigValidity" SG_ 2549874806 SNI_MDPS 0;
BA_ "UsrSigPurpose" SG_ 2549874806 CBV_RMR_MDPS 8;
BA_ "UserSigValidity" SG_ 2549874806 CBV_RMR_MDPS 0;
BA_ "UsrSigPurpose" SG_ 2549874806 CBV_NMCoID_MDPS 8;
BA_ "UserSigValidity" SG_ 2549874806 CBV_NMCoID_MDPS 0;
BA_ "UsrSigPurpose" SG_ 2549874806 CBV_NMCoSRB_MDPS 8;
BA_ "UserSigValidity" SG_ 2549874806 CBV_NMCoSRB_MDPS 0;
BA_ "UsrSigPurpose" SG_ 2549874806 CBV_AWB_MDPS 8;
BA_ "UserSigValidity" SG_ 2549874806 CBV_AWB_MDPS 0;
BA_ "UsrSigPurpose" SG_ 2549874806 CBV_PNIB_MDPS 8;
BA_ "UserSigValidity" SG_ 2549874806 CBV_PNIB_MDPS 0;
BA_ "UsrSigPurpose" SG_ 2549874806 NRR_MDPS 8;
BA_ "UserSigValidity" SG_ 2549874806 NRR_MDPS 0;
BA_ "UsrSigPurpose" SG_ 2549874806 NM_State_MDPS 8;
BA_ "UserSigValidity" SG_ 2549874806 NM_State_MDPS 0;
BA_ "UsrSigPurpose" SG_ 2549874806 PNI_MDPS 8;
BA_ "UserSigValidity" SG_ 2549874806 PNI_MDPS 0;
BA_ "UsrSigPurpose" SG_ 2549874806 PNI_MDPS_1 8;
BA_ "UserSigValidity" SG_ 2549874806 PNI_MDPS_1 0;
BA_ "UsrSigPurpose" SG_ 2549874806 PNI_MDPS_2 8;
BA_ "UserSigValidity" SG_ 2549874806 PNI_MDPS_2 0;
BA_ "UsrSigPurpose" SG_ 2549874806 PNI_MDPS_3 8;
BA_ "UserSigValidity" SG_ 2549874806 PNI_MDPS_3 0;
BA_ "UsrSigPurpose" SG_ 2549874762 SNI_RWA 8;
BA_ "UserSigValidity" SG_ 2549874762 SNI_RWA 0;
BA_ "UsrSigPurpose" SG_ 2549874762 CBV_RMR_RWA 8;
BA_ "UserSigValidity" SG_ 2549874762 CBV_RMR_RWA 0;
BA_ "UsrSigPurpose" SG_ 2549874762 CBV_NMCoID_RWA 8;
BA_ "UserSigValidity" SG_ 2549874762 CBV_NMCoID_RWA 0;
BA_ "UsrSigPurpose" SG_ 2549874762 CBV_NMCoSRB_RWA 8;
BA_ "UserSigValidity" SG_ 2549874762 CBV_NMCoSRB_RWA 0;
BA_ "UsrSigPurpose" SG_ 2549874762 CBV_AWB_RWA 8;
BA_ "UserSigValidity" SG_ 2549874762 CBV_AWB_RWA 0;
BA_ "UsrSigPurpose" SG_ 2549874762 CBV_PNIB_RWA 8;
BA_ "UserSigValidity" SG_ 2549874762 CBV_PNIB_RWA 0;
BA_ "UsrSigPurpose" SG_ 2549874762 NRR_RWA 8;
BA_ "UserSigValidity" SG_ 2549874762 NRR_RWA 0;
BA_ "UsrSigPurpose" SG_ 2549874762 NM_State_RWA 8;
BA_ "UserSigValidity" SG_ 2549874762 NM_State_RWA 0;
BA_ "UsrSigPurpose" SG_ 2549874762 PNI_RWA 8;
BA_ "UserSigValidity" SG_ 2549874762 PNI_RWA 0;
BA_ "UsrSigPurpose" SG_ 2549874762 PNI_RWA_1 8;
BA_ "UserSigValidity" SG_ 2549874762 PNI_RWA_1 0;
BA_ "UsrSigPurpose" SG_ 2549874762 PNI_RWA_2 8;
BA_ "UserSigValidity" SG_ 2549874762 PNI_RWA_2 0;
BA_ "UsrSigPurpose" SG_ 2549874762 PNI_RWA_3 8;
BA_ "UserSigValidity" SG_ 2549874762 PNI_RWA_3 0;
BA_ "UsrSigPurpose" SG_ 2549874746 SNI_SFA 8;
BA_ "UserSigValidity" SG_ 2549874746 SNI_SFA 0;
BA_ "UsrSigPurpose" SG_ 2549874746 CBV_RMR_SFA 8;
BA_ "UserSigValidity" SG_ 2549874746 CBV_RMR_SFA 0;
BA_ "UsrSigPurpose" SG_ 2549874746 CBV_NMCoID_SFA 8;
BA_ "UserSigValidity" SG_ 2549874746 CBV_NMCoID_SFA 0;
BA_ "UsrSigPurpose" SG_ 2549874746 CBV_NMCoSRB_SFA 8;
BA_ "UserSigValidity" SG_ 2549874746 CBV_NMCoSRB_SFA 0;
BA_ "UsrSigPurpose" SG_ 2549874746 CBV_AWB_SFA 8;
BA_ "UserSigValidity" SG_ 2549874746 CBV_AWB_SFA 0;
BA_ "UsrSigPurpose" SG_ 2549874746 CBV_PNIB_SFA 8;
BA_ "UserSigValidity" SG_ 2549874746 CBV_PNIB_SFA 0;
BA_ "UsrSigPurpose" SG_ 2549874746 NRR_SFA 8;
BA_ "UserSigValidity" SG_ 2549874746 NRR_SFA 0;
BA_ "UsrSigPurpose" SG_ 2549874746 NM_State_SFA 8;
BA_ "UserSigValidity" SG_ 2549874746 NM_State_SFA 0;
BA_ "UsrSigPurpose" SG_ 2549874746 PNI_SFA 8;
BA_ "UserSigValidity" SG_ 2549874746 PNI_SFA 0;
BA_ "UsrSigPurpose" SG_ 2549874746 PNI_SFA_1 8;
BA_ "UserSigValidity" SG_ 2549874746 PNI_SFA_1 0;
BA_ "UsrSigPurpose" SG_ 2549874746 PNI_SFA_2 8;
BA_ "UserSigValidity" SG_ 2549874746 PNI_SFA_2 0;
BA_ "UsrSigPurpose" SG_ 2549874746 PNI_SFA_3 8;
BA_ "UserSigValidity" SG_ 2549874746 PNI_SFA_3 0;
BA_REL_ "GenSigTimeoutTime" BU_SG_REL_ GW_RGW SG_ 1664 CCP_MDPS_SFA_REQ1_Byte0 0;
BA_REL_ "GenSigTimeoutTime" BU_SG_REL_ MDPS SG_ 1664 CCP_MDPS_SFA_REQ1_Byte0 0;
BA_REL_ "GenSigTimeoutTime" BU_SG_REL_ SFA SG_ 1664 CCP_MDPS_SFA_REQ1_Byte0 0;
BA_REL_ "GenSigTimeoutTime" BU_SG_REL_ GW_RGW SG_ 1664 CCP_MDPS_SFA_REQ1_Byte2 0;
BA_REL_ "GenSigTimeoutTime" BU_SG_REL_ MDPS SG_ 1664 CCP_MDPS_SFA_REQ1_Byte2 0;
BA_REL_ "GenSigTimeoutTime" BU_SG_REL_ SFA SG_ 1664 CCP_MDPS_SFA_REQ1_Byte2 0;
BA_REL_ "GenSigTimeoutTime" BU_SG_REL_ GW_RGW SG_ 1664 CCP_MDPS_SFA_REQ1_Byte3 0;
BA_REL_ "GenSigTimeoutTime" BU_SG_REL_ MDPS SG_ 1664 CCP_MDPS_SFA_REQ1_Byte3 0;
BA_REL_ "GenSigTimeoutTime" BU_SG_REL_ SFA SG_ 1664 CCP_MDPS_SFA_REQ1_Byte3 0;
BA_REL_ "GenSigTimeoutTime" BU_SG_REL_ GW_RGW SG_ 1664 CCP_MDPS_SFA_REQ1_Byte4 0;
BA_REL_ "GenSigTimeoutTime" BU_SG_REL_ MDPS SG_ 1664 CCP_MDPS_SFA_REQ1_Byte4 0;
BA_REL_ "GenSigTimeoutTime" BU_SG_REL_ SFA SG_ 1664 CCP_MDPS_SFA_REQ1_Byte4 0;
BA_REL_ "GenSigTimeoutTime" BU_SG_REL_ GW_RGW SG_ 1664 CCP_MDPS_SFA_REQ1_Byte5 0;
BA_REL_ "GenSigTimeoutTime" BU_SG_REL_ MDPS SG_ 1664 CCP_MDPS_SFA_REQ1_Byte5 0;
BA_REL_ "GenSigTimeoutTime" BU_SG_REL_ SFA SG_ 1664 CCP_MDPS_SFA_REQ1_Byte5 0;
BA_REL_ "GenSigTimeoutTime" BU_SG_REL_ GW_RGW SG_ 1664 CCP_MDPS_SFA_REQ1_Byte6 0;
BA_REL_ "GenSigTimeoutTime" BU_SG_REL_ MDPS SG_ 1664 CCP_MDPS_SFA_REQ1_Byte6 0;
BA_REL_ "GenSigTimeoutTime" BU_SG_REL_ SFA SG_ 1664 CCP_MDPS_SFA_REQ1_Byte6 0;
BA_REL_ "GenSigTimeoutTime" BU_SG_REL_ GW_RGW SG_ 1664 CCP_MDPS_SFA_REQ1_Byte7 0;
BA_REL_ "GenSigTimeoutTime" BU_SG_REL_ MDPS SG_ 1664 CCP_MDPS_SFA_REQ1_Byte7 0;
BA_REL_ "GenSigTimeoutTime" BU_SG_REL_ SFA SG_ 1664 CCP_MDPS_SFA_REQ1_Byte7 0;
BA_REL_ "GenSigTimeoutTime" BU_SG_REL_ GW_RGW SG_ 1664 CCP_MDPS_SFA_REQ1_Byte1 0;
BA_REL_ "GenSigTimeoutTime" BU_SG_REL_ MDPS SG_ 1664 CCP_MDPS_SFA_REQ1_Byte1 0;
BA_REL_ "GenSigTimeoutTime" BU_SG_REL_ SFA SG_ 1664 CCP_MDPS_SFA_REQ1_Byte1 0;
BA_REL_ "GenSigTimeoutTime" BU_SG_REL_ GW_RGW SG_ 1666 CCP_MDPS_RWA_REQ3_Byte0 0;
BA_REL_ "GenSigTimeoutTime" BU_SG_REL_ MDPS SG_ 1666 CCP_MDPS_RWA_REQ3_Byte0 0;
BA_REL_ "GenSigTimeoutTime" BU_SG_REL_ RWA SG_ 1666 CCP_MDPS_RWA_REQ3_Byte0 0;
BA_REL_ "GenSigTimeoutTime" BU_SG_REL_ GW_RGW SG_ 1666 CCP_MDPS_RWA_REQ3_Byte2 0;
BA_REL_ "GenSigTimeoutTime" BU_SG_REL_ MDPS SG_ 1666 CCP_MDPS_RWA_REQ3_Byte2 0;
BA_REL_ "GenSigTimeoutTime" BU_SG_REL_ RWA SG_ 1666 CCP_MDPS_RWA_REQ3_Byte2 0;
BA_REL_ "GenSigTimeoutTime" BU_SG_REL_ GW_RGW SG_ 1666 CCP_MDPS_RWA_REQ3_Byte3 0;
BA_REL_ "GenSigTimeoutTime" BU_SG_REL_ MDPS SG_ 1666 CCP_MDPS_RWA_REQ3_Byte3 0;
BA_REL_ "GenSigTimeoutTime" BU_SG_REL_ RWA SG_ 1666 CCP_MDPS_RWA_REQ3_Byte3 0;
BA_REL_ "GenSigTimeoutTime" BU_SG_REL_ GW_RGW SG_ 1666 CCP_MDPS_RWA_REQ3_Byte4 0;
BA_REL_ "GenSigTimeoutTime" BU_SG_REL_ MDPS SG_ 1666 CCP_MDPS_RWA_REQ3_Byte4 0;
BA_REL_ "GenSigTimeoutTime" BU_SG_REL_ RWA SG_ 1666 CCP_MDPS_RWA_REQ3_Byte4 0;
BA_REL_ "GenSigTimeoutTime" BU_SG_REL_ GW_RGW SG_ 1666 CCP_MDPS_RWA_REQ3_Byte5 0;
BA_REL_ "GenSigTimeoutTime" BU_SG_REL_ MDPS SG_ 1666 CCP_MDPS_RWA_REQ3_Byte5 0;
BA_REL_ "GenSigTimeoutTime" BU_SG_REL_ RWA SG_ 1666 CCP_MDPS_RWA_REQ3_Byte5 0;
BA_REL_ "GenSigTimeoutTime" BU_SG_REL_ GW_RGW SG_ 1666 CCP_MDPS_RWA_REQ3_Byte6 0;
BA_REL_ "GenSigTimeoutTime" BU_SG_REL_ MDPS SG_ 1666 CCP_MDPS_RWA_REQ3_Byte6 0;
BA_REL_ "GenSigTimeoutTime" BU_SG_REL_ RWA SG_ 1666 CCP_MDPS_RWA_REQ3_Byte6 0;
BA_REL_ "GenSigTimeoutTime" BU_SG_REL_ GW_RGW SG_ 1666 CCP_MDPS_RWA_REQ3_Byte7 0;
BA_REL_ "GenSigTimeoutTime" BU_SG_REL_ MDPS SG_ 1666 CCP_MDPS_RWA_REQ3_Byte7 0;
BA_REL_ "GenSigTimeoutTime" BU_SG_REL_ RWA SG_ 1666 CCP_MDPS_RWA_REQ3_Byte7 0;
BA_REL_ "GenSigTimeoutTime" BU_SG_REL_ GW_RGW SG_ 1666 CCP_MDPS_RWA_REQ3_Byte1 0;
BA_REL_ "GenSigTimeoutTime" BU_SG_REL_ MDPS SG_ 1666 CCP_MDPS_RWA_REQ3_Byte1 0;
BA_REL_ "GenSigTimeoutTime" BU_SG_REL_ RWA SG_ 1666 CCP_MDPS_RWA_REQ3_Byte1 0;
BA_REL_ "GenSigTimeoutTime" BU_SG_REL_ GW_RGW SG_ 813 SBCM_DRV_FD_Crc1Val 1500;
BA_REL_ "GenSigTimeoutTime" BU_SG_REL_ RWA SG_ 813 SBCM_DRV_FD_Crc1Val 1500;
BA_REL_ "GenSigTimeoutTime" BU_SG_REL_ RWS SG_ 813 SBCM_DRV_FD_Crc1Val 1500;
BA_REL_ "GenSigTimeoutTime" BU_SG_REL_ SFA SG_ 813 SBCM_DRV_FD_Crc1Val 1500;
BA_REL_ "GenSigTimeoutTime" BU_SG_REL_ GW_RGW SG_ 813 SBCM_DRV_FD_AlvCnt1Val 1500;
BA_REL_ "GenSigTimeoutTime" BU_SG_REL_ RWA SG_ 813 SBCM_DRV_FD_AlvCnt1Val 1500;
BA_REL_ "GenSigTimeoutTime" BU_SG_REL_ RWS SG_ 813 SBCM_DRV_FD_AlvCnt1Val 1500;
BA_REL_ "GenSigTimeoutTime" BU_SG_REL_ SFA SG_ 813 SBCM_DRV_FD_AlvCnt1Val 1500;
BA_REL_ "GenSigTimeoutTime" BU_SG_REL_ ECS SG_ 813 Warn_DrvDrSwSta_SBCM 1500;
BA_REL_ "GenSigTimeoutTime" BU_SG_REL_ EPB SG_ 813 Warn_DrvDrSwSta_SBCM 1500;
BA_REL_ "GenSigTimeoutTime" BU_SG_REL_ ESC SG_ 813 Warn_DrvDrSwSta_SBCM 1500;
BA_REL_ "GenSigTimeoutTime" BU_SG_REL_ GW_RGW SG_ 813 Warn_DrvDrSwSta_SBCM 1500;
BA_REL_ "GenSigTimeoutTime" BU_SG_REL_ RCU SG_ 813 Warn_DrvDrSwSta_SBCM 1500;
BA_REL_ "GenSigTimeoutTime" BU_SG_REL_ RWA SG_ 813 Warn_DrvDrSwSta_SBCM 1500;
BA_REL_ "GenSigTimeoutTime" BU_SG_REL_ SFA SG_ 813 Warn_DrvDrSwSta_SBCM 1500;
BA_REL_ "GenSigTimeoutTime" BU_SG_REL_ CGW_CCU SG_ 2550071313 RWA_GST_Byte0 0;
BA_REL_ "GenSigTimeoutTime" BU_SG_REL_ CGW_CCU SG_ 2550071313 RWA_GST_Byte2 0;
BA_REL_ "GenSigTimeoutTime" BU_SG_REL_ CGW_CCU SG_ 2550071313 RWA_GST_Byte3 0;
BA_REL_ "GenSigTimeoutTime" BU_SG_REL_ CGW_CCU SG_ 2550071313 RWA_GST_Byte4 0;
BA_REL_ "GenSigTimeoutTime" BU_SG_REL_ CGW_CCU SG_ 2550071313 RWA_GST_Byte5 0;
BA_REL_ "GenSigTimeoutTime" BU_SG_REL_ CGW_CCU SG_ 2550071313 RWA_GST_Byte6 0;
BA_REL_ "GenSigTimeoutTime" BU_SG_REL_ CGW_CCU SG_ 2550071313 RWA_GST_Byte7 0;
BA_REL_ "GenSigTimeoutTime" BU_SG_REL_ CGW_CCU SG_ 2550071313 RWA_GST_Byte1 0;
BA_REL_ "GenSigTimeoutTime" BU_SG_REL_ GW_RGW SG_ 811 SBCM_AST_FD_Crc1Val 1500;
BA_REL_ "GenSigTimeoutTime" BU_SG_REL_ RWA SG_ 811 SBCM_AST_FD_Crc1Val 1500;
BA_REL_ "GenSigTimeoutTime" BU_SG_REL_ SFA SG_ 811 SBCM_AST_FD_Crc1Val 1500;
BA_REL_ "GenSigTimeoutTime" BU_SG_REL_ GW_RGW SG_ 811 SBCM_AST_FD_AlvCnt1Val 1500;
BA_REL_ "GenSigTimeoutTime" BU_SG_REL_ RWA SG_ 811 SBCM_AST_FD_AlvCnt1Val 1500;
BA_REL_ "GenSigTimeoutTime" BU_SG_REL_ SFA SG_ 811 SBCM_AST_FD_AlvCnt1Val 1500;
BA_REL_ "GenSigTimeoutTime" BU_SG_REL_ ECS SG_ 811 Warn_AsstDrSwSta_SBCM 1500;
BA_REL_ "GenSigTimeoutTime" BU_SG_REL_ GW_RGW SG_ 811 Warn_AsstDrSwSta_SBCM 1500;
BA_REL_ "GenSigTimeoutTime" BU_SG_REL_ RWA SG_ 811 Warn_AsstDrSwSta_SBCM 1500;
BA_REL_ "GenSigTimeoutTime" BU_SG_REL_ SFA SG_ 811 Warn_AsstDrSwSta_SBCM 1500;
BA_REL_ "GenSigTimeoutTime" BU_SG_REL_ RWA SG_ 2550075648 GST_RWA_Byte0 0;
BA_REL_ "GenSigTimeoutTime" BU_SG_REL_ RWA SG_ 2550075648 GST_RWA_Byte2 0;
BA_REL_ "GenSigTimeoutTime" BU_SG_REL_ RWA SG_ 2550075648 GST_RWA_Byte3 0;
BA_REL_ "GenSigTimeoutTime" BU_SG_REL_ RWA SG_ 2550075648 GST_RWA_Byte4 0;
BA_REL_ "GenSigTimeoutTime" BU_SG_REL_ RWA SG_ 2550075648 GST_RWA_Byte5 0;
BA_REL_ "GenSigTimeoutTime" BU_SG_REL_ RWA SG_ 2550075648 GST_RWA_Byte6 0;
BA_REL_ "GenSigTimeoutTime" BU_SG_REL_ RWA SG_ 2550075648 GST_RWA_Byte7 0;
BA_REL_ "GenSigTimeoutTime" BU_SG_REL_ RWA SG_ 2550075648 GST_RWA_Byte1 0;
BA_REL_ "GenSigTimeoutTime" BU_SG_REL_ MDPS SG_ 2004 GST_MDPS_SFA_Byte0 0;
BA_REL_ "GenSigTimeoutTime" BU_SG_REL_ SFA SG_ 2004 GST_MDPS_SFA_Byte0 0;
BA_REL_ "GenSigTimeoutTime" BU_SG_REL_ MDPS SG_ 2004 GST_MDPS_SFA_Byte2 0;
BA_REL_ "GenSigTimeoutTime" BU_SG_REL_ SFA SG_ 2004 GST_MDPS_SFA_Byte2 0;
BA_REL_ "GenSigTimeoutTime" BU_SG_REL_ MDPS SG_ 2004 GST_MDPS_SFA_Byte3 0;
BA_REL_ "GenSigTimeoutTime" BU_SG_REL_ SFA SG_ 2004 GST_MDPS_SFA_Byte3 0;
BA_REL_ "GenSigTimeoutTime" BU_SG_REL_ MDPS SG_ 2004 GST_MDPS_SFA_Byte4 0;
BA_REL_ "GenSigTimeoutTime" BU_SG_REL_ SFA SG_ 2004 GST_MDPS_SFA_Byte4 0;
BA_REL_ "GenSigTimeoutTime" BU_SG_REL_ MDPS SG_ 2004 GST_MDPS_SFA_Byte5 0;
BA_REL_ "GenSigTimeoutTime" BU_SG_REL_ SFA SG_ 2004 GST_MDPS_SFA_Byte5 0;
BA_REL_ "GenSigTimeoutTime" BU_SG_REL_ MDPS SG_ 2004 GST_MDPS_SFA_Byte6 0;
BA_REL_ "GenSigTimeoutTime" BU_SG_REL_ SFA SG_ 2004 GST_MDPS_SFA_Byte6 0;
BA_REL_ "GenSigTimeoutTime" BU_SG_REL_ MDPS SG_ 2004 GST_MDPS_SFA_Byte7 0;
BA_REL_ "GenSigTimeoutTime" BU_SG_REL_ SFA SG_ 2004 GST_MDPS_SFA_Byte7 0;
BA_REL_ "GenSigTimeoutTime" BU_SG_REL_ MDPS SG_ 2004 GST_MDPS_SFA_Byte1 0;
BA_REL_ "GenSigTimeoutTime" BU_SG_REL_ SFA SG_ 2004 GST_MDPS_SFA_Byte1 0;
BA_REL_ "GenSigTimeoutTime" BU_SG_REL_ ABS SG_ 2015 GST_ALL_Byte0 0;
BA_REL_ "GenSigTimeoutTime" BU_SG_REL_ EBB SG_ 2015 GST_ALL_Byte0 0;
BA_REL_ "GenSigTimeoutTime" BU_SG_REL_ ECS SG_ 2015 GST_ALL_Byte0 0;
BA_REL_ "GenSigTimeoutTime" BU_SG_REL_ EPB SG_ 2015 GST_ALL_Byte0 0;
BA_REL_ "GenSigTimeoutTime" BU_SG_REL_ ESC SG_ 2015 GST_ALL_Byte0 0;
BA_REL_ "GenSigTimeoutTime" BU_SG_REL_ GW_RGW SG_ 2015 GST_ALL_Byte0 0;
BA_REL_ "GenSigTimeoutTime" BU_SG_REL_ ICSC SG_ 2015 GST_ALL_Byte0 0;
BA_REL_ "GenSigTimeoutTime" BU_SG_REL_ MDPS SG_ 2015 GST_ALL_Byte0 0;
BA_REL_ "GenSigTimeoutTime" BU_SG_REL_ RCU SG_ 2015 GST_ALL_Byte0 0;
BA_REL_ "GenSigTimeoutTime" BU_SG_REL_ RWA SG_ 2015 GST_ALL_Byte0 0;
BA_REL_ "GenSigTimeoutTime" BU_SG_REL_ RWS SG_ 2015 GST_ALL_Byte0 0;
BA_REL_ "GenSigTimeoutTime" BU_SG_REL_ SAS SG_ 2015 GST_ALL_Byte0 0;
BA_REL_ "GenSigTimeoutTime" BU_SG_REL_ SFA SG_ 2015 GST_ALL_Byte0 0;
BA_REL_ "GenSigTimeoutTime" BU_SG_REL_ TPMS SG_ 2015 GST_ALL_Byte0 0;
BA_REL_ "GenSigTimeoutTime" BU_SG_REL_ ABS SG_ 2015 GST_ALL_Byte2 0;
BA_REL_ "GenSigTimeoutTime" BU_SG_REL_ EBB SG_ 2015 GST_ALL_Byte2 0;
BA_REL_ "GenSigTimeoutTime" BU_SG_REL_ ECS SG_ 2015 GST_ALL_Byte2 0;
BA_REL_ "GenSigTimeoutTime" BU_SG_REL_ EPB SG_ 2015 GST_ALL_Byte2 0;
BA_REL_ "GenSigTimeoutTime" BU_SG_REL_ ESC SG_ 2015 GST_ALL_Byte2 0;
BA_REL_ "GenSigTimeoutTime" BU_SG_REL_ GW_RGW SG_ 2015 GST_ALL_Byte2 0;
BA_REL_ "GenSigTimeoutTime" BU_SG_REL_ ICSC SG_ 2015 GST_ALL_Byte2 0;
BA_REL_ "GenSigTimeoutTime" BU_SG_REL_ MDPS SG_ 2015 GST_ALL_Byte2 0;
BA_REL_ "GenSigTimeoutTime" BU_SG_REL_ RCU SG_ 2015 GST_ALL_Byte2 0;
BA_REL_ "GenSigTimeoutTime" BU_SG_REL_ RWA SG_ 2015 GST_ALL_Byte2 0;
BA_REL_ "GenSigTimeoutTime" BU_SG_REL_ RWS SG_ 2015 GST_ALL_Byte2 0;
BA_REL_ "GenSigTimeoutTime" BU_SG_REL_ SAS SG_ 2015 GST_ALL_Byte2 0;
BA_REL_ "GenSigTimeoutTime" BU_SG_REL_ SFA SG_ 2015 GST_ALL_Byte2 0;
BA_REL_ "GenSigTimeoutTime" BU_SG_REL_ TPMS SG_ 2015 GST_ALL_Byte2 0;
BA_REL_ "GenSigTimeoutTime" BU_SG_REL_ ABS SG_ 2015 GST_ALL_Byte3 0;
BA_REL_ "GenSigTimeoutTime" BU_SG_REL_ EBB SG_ 2015 GST_ALL_Byte3 0;
BA_REL_ "GenSigTimeoutTime" BU_SG_REL_ ECS SG_ 2015 GST_ALL_Byte3 0;
BA_REL_ "GenSigTimeoutTime" BU_SG_REL_ EPB SG_ 2015 GST_ALL_Byte3 0;
BA_REL_ "GenSigTimeoutTime" BU_SG_REL_ ESC SG_ 2015 GST_ALL_Byte3 0;
BA_REL_ "GenSigTimeoutTime" BU_SG_REL_ GW_RGW SG_ 2015 GST_ALL_Byte3 0;
BA_REL_ "GenSigTimeoutTime" BU_SG_REL_ ICSC SG_ 2015 GST_ALL_Byte3 0;
BA_REL_ "GenSigTimeoutTime" BU_SG_REL_ MDPS SG_ 2015 GST_ALL_Byte3 0;
BA_REL_ "GenSigTimeoutTime" BU_SG_REL_ RCU SG_ 2015 GST_ALL_Byte3 0;
BA_REL_ "GenSigTimeoutTime" BU_SG_REL_ RWA SG_ 2015 GST_ALL_Byte3 0;
BA_REL_ "GenSigTimeoutTime" BU_SG_REL_ RWS SG_ 2015 GST_ALL_Byte3 0;
BA_REL_ "GenSigTimeoutTime" BU_SG_REL_ SAS SG_ 2015 GST_ALL_Byte3 0;
BA_REL_ "GenSigTimeoutTime" BU_SG_REL_ SFA SG_ 2015 GST_ALL_Byte3 0;
BA_REL_ "GenSigTimeoutTime" BU_SG_REL_ TPMS SG_ 2015 GST_ALL_Byte3 0;
BA_REL_ "GenSigTimeoutTime" BU_SG_REL_ ABS SG_ 2015 GST_ALL_Byte4 0;
BA_REL_ "GenSigTimeoutTime" BU_SG_REL_ EBB SG_ 2015 GST_ALL_Byte4 0;
BA_REL_ "GenSigTimeoutTime" BU_SG_REL_ ECS SG_ 2015 GST_ALL_Byte4 0;
BA_REL_ "GenSigTimeoutTime" BU_SG_REL_ EPB SG_ 2015 GST_ALL_Byte4 0;
BA_REL_ "GenSigTimeoutTime" BU_SG_REL_ ESC SG_ 2015 GST_ALL_Byte4 0;
BA_REL_ "GenSigTimeoutTime" BU_SG_REL_ GW_RGW SG_ 2015 GST_ALL_Byte4 0;
BA_REL_ "GenSigTimeoutTime" BU_SG_REL_ ICSC SG_ 2015 GST_ALL_Byte4 0;
BA_REL_ "GenSigTimeoutTime" BU_SG_REL_ MDPS SG_ 2015 GST_ALL_Byte4 0;
BA_REL_ "GenSigTimeoutTime" BU_SG_REL_ RCU SG_ 2015 GST_ALL_Byte4 0;
BA_REL_ "GenSigTimeoutTime" BU_SG_REL_ RWA SG_ 2015 GST_ALL_Byte4 0;
BA_REL_ "GenSigTimeoutTime" BU_SG_REL_ RWS SG_ 2015 GST_ALL_Byte4 0;
BA_REL_ "GenSigTimeoutTime" BU_SG_REL_ SAS SG_ 2015 GST_ALL_Byte4 0;
BA_REL_ "GenSigTimeoutTime" BU_SG_REL_ SFA SG_ 2015 GST_ALL_Byte4 0;
BA_REL_ "GenSigTimeoutTime" BU_SG_REL_ TPMS SG_ 2015 GST_ALL_Byte4 0;
BA_REL_ "GenSigTimeoutTime" BU_SG_REL_ ABS SG_ 2015 GST_ALL_Byte5 0;
BA_REL_ "GenSigTimeoutTime" BU_SG_REL_ EBB SG_ 2015 GST_ALL_Byte5 0;
BA_REL_ "GenSigTimeoutTime" BU_SG_REL_ ECS SG_ 2015 GST_ALL_Byte5 0;
BA_REL_ "GenSigTimeoutTime" BU_SG_REL_ EPB SG_ 2015 GST_ALL_Byte5 0;
BA_REL_ "GenSigTimeoutTime" BU_SG_REL_ ESC SG_ 2015 GST_ALL_Byte5 0;
BA_REL_ "GenSigTimeoutTime" BU_SG_REL_ GW_RGW SG_ 2015 GST_ALL_Byte5 0;
BA_REL_ "GenSigTimeoutTime" BU_SG_REL_ ICSC SG_ 2015 GST_ALL_Byte5 0;
BA_REL_ "GenSigTimeoutTime" BU_SG_REL_ MDPS SG_ 2015 GST_ALL_Byte5 0;
BA_REL_ "GenSigTimeoutTime" BU_SG_REL_ RCU SG_ 2015 GST_ALL_Byte5 0;
BA_REL_ "GenSigTimeoutTime" BU_SG_REL_ RWA SG_ 2015 GST_ALL_Byte5 0;
BA_REL_ "GenSigTimeoutTime" BU_SG_REL_ RWS SG_ 2015 GST_ALL_Byte5 0;
BA_REL_ "GenSigTimeoutTime" BU_SG_REL_ SAS SG_ 2015 GST_ALL_Byte5 0;
BA_REL_ "GenSigTimeoutTime" BU_SG_REL_ SFA SG_ 2015 GST_ALL_Byte5 0;
BA_REL_ "GenSigTimeoutTime" BU_SG_REL_ TPMS SG_ 2015 GST_ALL_Byte5 0;
BA_REL_ "GenSigTimeoutTime" BU_SG_REL_ ABS SG_ 2015 GST_ALL_Byte6 0;
BA_REL_ "GenSigTimeoutTime" BU_SG_REL_ EBB SG_ 2015 GST_ALL_Byte6 0;
BA_REL_ "GenSigTimeoutTime" BU_SG_REL_ ECS SG_ 2015 GST_ALL_Byte6 0;
BA_REL_ "GenSigTimeoutTime" BU_SG_REL_ EPB SG_ 2015 GST_ALL_Byte6 0;
BA_REL_ "GenSigTimeoutTime" BU_SG_REL_ ESC SG_ 2015 GST_ALL_Byte6 0;
BA_REL_ "GenSigTimeoutTime" BU_SG_REL_ GW_RGW SG_ 2015 GST_ALL_Byte6 0;
BA_REL_ "GenSigTimeoutTime" BU_SG_REL_ ICSC SG_ 2015 GST_ALL_Byte6 0;
BA_REL_ "GenSigTimeoutTime" BU_SG_REL_ MDPS SG_ 2015 GST_ALL_Byte6 0;
BA_REL_ "GenSigTimeoutTime" BU_SG_REL_ RCU SG_ 2015 GST_ALL_Byte6 0;
BA_REL_ "GenSigTimeoutTime" BU_SG_REL_ RWA SG_ 2015 GST_ALL_Byte6 0;
BA_REL_ "GenSigTimeoutTime" BU_SG_REL_ RWS SG_ 2015 GST_ALL_Byte6 0;
BA_REL_ "GenSigTimeoutTime" BU_SG_REL_ SAS SG_ 2015 GST_ALL_Byte6 0;
BA_REL_ "GenSigTimeoutTime" BU_SG_REL_ SFA SG_ 2015 GST_ALL_Byte6 0;
BA_REL_ "GenSigTimeoutTime" BU_SG_REL_ TPMS SG_ 2015 GST_ALL_Byte6 0;
BA_REL_ "GenSigTimeoutTime" BU_SG_REL_ ABS SG_ 2015 GST_ALL_Byte7 0;
BA_REL_ "GenSigTimeoutTime" BU_SG_REL_ EBB SG_ 2015 GST_ALL_Byte7 0;
BA_REL_ "GenSigTimeoutTime" BU_SG_REL_ ECS SG_ 2015 GST_ALL_Byte7 0;
BA_REL_ "GenSigTimeoutTime" BU_SG_REL_ EPB SG_ 2015 GST_ALL_Byte7 0;
BA_REL_ "GenSigTimeoutTime" BU_SG_REL_ ESC SG_ 2015 GST_ALL_Byte7 0;
BA_REL_ "GenSigTimeoutTime" BU_SG_REL_ GW_RGW SG_ 2015 GST_ALL_Byte7 0;
BA_REL_ "GenSigTimeoutTime" BU_SG_REL_ ICSC SG_ 2015 GST_ALL_Byte7 0;
BA_REL_ "GenSigTimeoutTime" BU_SG_REL_ MDPS SG_ 2015 GST_ALL_Byte7 0;
BA_REL_ "GenSigTimeoutTime" BU_SG_REL_ RCU SG_ 2015 GST_ALL_Byte7 0;
BA_REL_ "GenSigTimeoutTime" BU_SG_REL_ RWA SG_ 2015 GST_ALL_Byte7 0;
BA_REL_ "GenSigTimeoutTime" BU_SG_REL_ RWS SG_ 2015 GST_ALL_Byte7 0;
BA_REL_ "GenSigTimeoutTime" BU_SG_REL_ SAS SG_ 2015 GST_ALL_Byte7 0;
BA_REL_ "GenSigTimeoutTime" BU_SG_REL_ SFA SG_ 2015 GST_ALL_Byte7 0;
BA_REL_ "GenSigTimeoutTime" BU_SG_REL_ TPMS SG_ 2015 GST_ALL_Byte7 0;
BA_REL_ "GenSigTimeoutTime" BU_SG_REL_ ABS SG_ 2015 GST_ALL_Byte1 0;
BA_REL_ "GenSigTimeoutTime" BU_SG_REL_ EBB SG_ 2015 GST_ALL_Byte1 0;
BA_REL_ "GenSigTimeoutTime" BU_SG_REL_ ECS SG_ 2015 GST_ALL_Byte1 0;
BA_REL_ "GenSigTimeoutTime" BU_SG_REL_ EPB SG_ 2015 GST_ALL_Byte1 0;
BA_REL_ "GenSigTimeoutTime" BU_SG_REL_ ESC SG_ 2015 GST_ALL_Byte1 0;
BA_REL_ "GenSigTimeoutTime" BU_SG_REL_ GW_RGW SG_ 2015 GST_ALL_Byte1 0;
BA_REL_ "GenSigTimeoutTime" BU_SG_REL_ ICSC SG_ 2015 GST_ALL_Byte1 0;
BA_REL_ "GenSigTimeoutTime" BU_SG_REL_ MDPS SG_ 2015 GST_ALL_Byte1 0;
BA_REL_ "GenSigTimeoutTime" BU_SG_REL_ RCU SG_ 2015 GST_ALL_Byte1 0;
BA_REL_ "GenSigTimeoutTime" BU_SG_REL_ RWA SG_ 2015 GST_ALL_Byte1 0;
BA_REL_ "GenSigTimeoutTime" BU_SG_REL_ RWS SG_ 2015 GST_ALL_Byte1 0;
BA_REL_ "GenSigTimeoutTime" BU_SG_REL_ SAS SG_ 2015 GST_ALL_Byte1 0;
BA_REL_ "GenSigTimeoutTime" BU_SG_REL_ SFA SG_ 2015 GST_ALL_Byte1 0;
BA_REL_ "GenSigTimeoutTime" BU_SG_REL_ TPMS SG_ 2015 GST_ALL_Byte1 0;
BA_REL_ "GenSigTimeoutTime" BU_SG_REL_ CGW_CCU SG_ 2012 MDPS_SFA_GST_Byte0 0;
BA_REL_ "GenSigTimeoutTime" BU_SG_REL_ CGW_CCU SG_ 2012 MDPS_SFA_GST_Byte2 0;
BA_REL_ "GenSigTimeoutTime" BU_SG_REL_ CGW_CCU SG_ 2012 MDPS_SFA_GST_Byte3 0;
BA_REL_ "GenSigTimeoutTime" BU_SG_REL_ CGW_CCU SG_ 2012 MDPS_SFA_GST_Byte4 0;
BA_REL_ "GenSigTimeoutTime" BU_SG_REL_ CGW_CCU SG_ 2012 MDPS_SFA_GST_Byte5 0;
BA_REL_ "GenSigTimeoutTime" BU_SG_REL_ CGW_CCU SG_ 2012 MDPS_SFA_GST_Byte6 0;
BA_REL_ "GenSigTimeoutTime" BU_SG_REL_ CGW_CCU SG_ 2012 MDPS_SFA_GST_Byte7 0;
BA_REL_ "GenSigTimeoutTime" BU_SG_REL_ CGW_CCU SG_ 2012 MDPS_SFA_GST_Byte1 0;
BA_REL_ "GenSigTimeoutTime" BU_SG_REL_ CGW_CCU SG_ 901 ICSC_Crc3Val 1500;
BA_REL_ "GenSigTimeoutTime" BU_SG_REL_ GW_RGW SG_ 901 ICSC_Crc3Val 1500;
BA_REL_ "GenSigTimeoutTime" BU_SG_REL_ MDPS SG_ 901 ICSC_Crc3Val 1500;
BA_REL_ "GenSigTimeoutTime" BU_SG_REL_ SFA SG_ 901 ICSC_Crc3Val 1500;
BA_REL_ "GenSigTimeoutTime" BU_SG_REL_ VPC_C SG_ 901 ICSC_Crc3Val 1500;
BA_REL_ "GenSigTimeoutTime" BU_SG_REL_ CGW_CCU SG_ 901 ICSC_AlvCnt3Val 1500;
BA_REL_ "GenSigTimeoutTime" BU_SG_REL_ GW_RGW SG_ 901 ICSC_AlvCnt3Val 1500;
BA_REL_ "GenSigTimeoutTime" BU_SG_REL_ MDPS SG_ 901 ICSC_AlvCnt3Val 1500;
BA_REL_ "GenSigTimeoutTime" BU_SG_REL_ SFA SG_ 901 ICSC_AlvCnt3Val 1500;
BA_REL_ "GenSigTimeoutTime" BU_SG_REL_ VPC_C SG_ 901 ICSC_AlvCnt3Val 1500;
BA_REL_ "GenSigTimeoutTime" BU_SG_REL_ CGW_CCU SG_ 901 DMIC_OffRdMod 1500;
BA_REL_ "GenSigTimeoutTime" BU_SG_REL_ ECS SG_ 901 DMIC_OffRdMod 1500;
BA_REL_ "GenSigTimeoutTime" BU_SG_REL_ GW_RGW SG_ 901 DMIC_OffRdMod 1500;
BA_REL_ "GenSigTimeoutTime" BU_SG_REL_ MDPS SG_ 901 DMIC_OffRdMod 1500;
BA_REL_ "GenSigTimeoutTime" BU_SG_REL_ SFA SG_ 901 DMIC_OffRdMod 1500;
BA_REL_ "GenSigTimeoutTime" BU_SG_REL_ VPC_C SG_ 901 DMIC_OffRdMod 1500;
BA_REL_ "GenSigTimeoutTime" BU_SG_REL_ GW_RGW SG_ 994 PDC_FD_Crc3Val 1500;
BA_REL_ "GenSigTimeoutTime" BU_SG_REL_ RWA SG_ 994 PDC_FD_Crc3Val 1500;
BA_REL_ "GenSigTimeoutTime" BU_SG_REL_ SFA SG_ 994 PDC_FD_Crc3Val 1500;
BA_REL_ "GenSigTimeoutTime" BU_SG_REL_ GW_RGW SG_ 994 PDC_FD_AlvCnt3Val 1500;
BA_REL_ "GenSigTimeoutTime" BU_SG_REL_ RWA SG_ 994 PDC_FD_AlvCnt3Val 1500;
BA_REL_ "GenSigTimeoutTime" BU_SG_REL_ SFA SG_ 994 PDC_FD_AlvCnt3Val 1500;
BA_REL_ "GenSigTimeoutTime" BU_SG_REL_ EPB SG_ 994 Warn_DrvDrSwSta 1500;
BA_REL_ "GenSigTimeoutTime" BU_SG_REL_ ESC SG_ 994 Warn_DrvDrSwSta 1500;
BA_REL_ "GenSigTimeoutTime" BU_SG_REL_ GW_RGW SG_ 994 Warn_DrvDrSwSta 1500;
BA_REL_ "GenSigTimeoutTime" BU_SG_REL_ RCU SG_ 994 Warn_DrvDrSwSta 1500;
BA_REL_ "GenSigTimeoutTime" BU_SG_REL_ RWA SG_ 994 Warn_DrvDrSwSta 1500;
BA_REL_ "GenSigTimeoutTime" BU_SG_REL_ SFA SG_ 994 Warn_DrvDrSwSta 1500;
BA_REL_ "GenSigTimeoutTime" BU_SG_REL_ GW_RGW SG_ 994 Warn_AsstDrSwSta 1500;
BA_REL_ "GenSigTimeoutTime" BU_SG_REL_ RWA SG_ 994 Warn_AsstDrSwSta 1500;
BA_REL_ "GenSigTimeoutTime" BU_SG_REL_ SFA SG_ 994 Warn_AsstDrSwSta 1500;
BA_REL_ "GenSigTimeoutTime" BU_SG_REL_ ESC SG_ 994 DoorLock_DrvDrUnLkSta 1500;
BA_REL_ "GenSigTimeoutTime" BU_SG_REL_ GW_RGW SG_ 994 DoorLock_DrvDrUnLkSta 1500;
BA_REL_ "GenSigTimeoutTime" BU_SG_REL_ RCU SG_ 994 DoorLock_DrvDrUnLkSta 1500;
BA_REL_ "GenSigTimeoutTime" BU_SG_REL_ RWA SG_ 994 DoorLock_DrvDrUnLkSta 1500;
BA_REL_ "GenSigTimeoutTime" BU_SG_REL_ SFA SG_ 994 DoorLock_DrvDrUnLkSta 1500;
VAL_ 234 MDPS_LoamModSta 0 "Normal" 1 "Loam Flag Warning Display" 2 "RESERVED" 3 "Error Indicator" ;
VAL_ 234 MDPS_HDPSpprtSWVer 0 "HDP-MDPS Control Requirement Version" 1 "HDP-MDPS Control Requirement Version" 2 "HDP-MDPS Control Requirement Version" 3 "HDP-MDPS Control Requirement Version" 4 "HDP-MDPS Control Requirement Version" 5 "HDP-MDPS Control Requirement Version" 6 "HDP-MDPS Control Requirement Version" 7 "HDP-MDPS Control Requirement Version" 8 "HDP-MDPS Control Requirement Version" 9 "HDP-MDPS Control Requirement Version" 10 "HDP-MDPS Control Requirement Version" 11 "HDP-MDPS Control Requirement Version" 12 "HDP-MDPS Control Requirement Version" 13 "HDP-MDPS Control Requirement Version" 14 "HDP-MDPS Control Requirement Version" 15 "HDP-MDPS Control Requirement Version" 16 "HDP-MDPS Control Requirement Version" 17 "HDP-MDPS Control Requirement Version" 18 "HDP-MDPS Control Requirement Version" 19 "HDP-MDPS Control Requirement Version" 20 "HDP-MDPS Control Requirement Version" 21 "HDP-MDPS Control Requirement Version" 22 "HDP-MDPS Control Requirement Version" 23 "HDP-MDPS Control Requirement Version" 24 "HDP-MDPS Control Requirement Version" 25 "HDP-MDPS Control Requirement Version" 26 "HDP-MDPS Control Requirement Version" 27 "HDP-MDPS Control Requirement Version" 28 "HDP-MDPS Control Requirement Version" 29 "HDP-MDPS Control Requirement Version" 30 "HDP-MDPS Control Requirement Version" 31 "HDP-MDPS Control Requirement Version" ;
VAL_ 234 MDPS_ADASAciActvSta 0 "INIT" 1 "INACTIVE" 2 "ACTIVE35(ACTIVE)" 3 "ACTIVE33(Redundancy)" 4 "RESERVED" 5 "RESERVED" 6 "RESERVED" 7 "RESERVED" 8 "RESERVED" 9 "RESERVED" 10 "RESERVED" 11 "RESERVED" 12 "RESERVED" 13 "RESERVED" 14 "RESERVED" 15 "RESERVED" ;
VAL_ 234 MDPS_ADASAciPluginSta 0 "ADASAciNotPlugged-in" 1 "ADASAciPlugged-in" 2 "RESERVED" 3 "ErrorIndicator" ;
VAL_ 234 MDPS_ADAS_AciFltSig 0 "No Fault" 1 "MDPS Fault" 2 "Fault Except MDPS" 3 "Both Fault" ;
VAL_ 234 MDPS_EstStrAnglVal 0 "0x0x000~0x7FFD:real values" 32765 "0x0x000~0x7FFD:real values" 32766 "Not Initialized" 32767 "Error Indicator" 32768 "0x8000~0xFFFF:real values" 65535 "0x8000~0xFFFF:real values" ;
VAL_ 234 MDPS_ADASAciActvSta_Lv2 0 "Not USED" 1 "INACTIVE" 2 "ACTIVE35(Active)" 3 "Reserved" 4 "Reserved" 5 "Reserved" 6 "Reserved" 7 "Reserved" 8 "Reserved" 9 "Reserved" 10 "Reserved" 11 "Reserved" 12 "Reserved" 13 "Reserved" 14 "Reserved" 15 "Reserved" ;
VAL_ 234 MDPS_ADAS_AciFltSig_Lv2 0 "No Fault" 1 "MDPS Fault" 2 "Fault Except MDPS" 3 "Both Fault" 4 "Temporarily Unavailable" 5 "Temporarily Unavailable and MDPS Fault" 6 "Temporarily Unavailable and Fault Except MDPS" 7 "Temporarily Unavailable and Both Fault" ;
VAL_ 234 MDPS_TpaPlugInSta 0 "The TPA function of MDPS is not plugged in (unplugged)" 1 "The TPA function of MDPS is plugged in" 2 "RESERVED" 3 "Error Indicator" ;
VAL_ 234 MDPS_TpaCanfltSta 0 "No Failure" 1 "Failure about Tpa can message" 2 "RESERVED" 3 "Error Indicator" ;
VAL_ 234 MDPS_TpaModeSta 0 "RESERVED" 1 "Steering still in initialization phase" 2 "Steering ready, waits for TPA command" 3 "Steering set in standby by TPA" 4 "Steering requested to go to first activation step activation step" 5 "Steering requested to go to final activation step" 6 "Steering went to error internally" 7 "Steering aborted the automatic function" 14 "RESERVED" 15 "Error Indicator" ;
VAL_ 234 MDPS_TpaStrAnglVal 0 "0x0x000~0x7FFD:real values" 32765 "0x0x000~0x7FFD:real values" 32766 "Not Initialized" 32767 "Error Indicator" 32768 "0x8000~0xFFFF:real values" 65535 "0x8000~0xFFFF:real values" ;
VAL_ 234 MDPS_WrngLmpSta 0 "MDPS Malfunction Warning lamp OFF" 1 "MDPS Malfunciton Warning lamp BLANKING(2Hz)" 2 "MDPS Malfunction Warning lamp ON" 3 "MDPS Malfunction Warning lamp BLANKING(1Hz)" 4 "RESERVED" 5 "RESERVED" 6 "RESERVED" 7 "Error Indicator" ;
VAL_ 234 MDPS_Typ 0 "C-MDPS" 1 "R-MDPS(Dual Pinion)" 2 "R-MDPS(Belt)" 3 "SbW" 4 "RESERVED" 5 "RESERVED" 6 "RESERVED" 7 "Error Indicator" ;
VAL_ 234 MDPS_EngIdleRpmReq 0 "Current Consumption is Low" 1 "Current Consumption is High" 2 ":RESERVED" 3 "Error Indicator" ;
VAL_ 234 MDPS_VsmPlgInSta 0 "The VSM function of MDPS is not plugged in (unplugged)." 1 "The VSM function of MDPS is plugged in." 2 "RESERVED" 3 "Error Indicator" ;
VAL_ 234 MDPS_VsmDfctvSta 0 "MDPS is not defective" 1 "MDPS is defective" 2 "RESERVED" 3 "Error Indicator" ;
VAL_ 234 MDPS_VsmSigErrSta 0 "VSM1 signal is not error" 1 "VSM signal is error" 2 "RESERVED" 3 "Error Indicator" ;
VAL_ 234 MDPS_PaPlugInSta 0 "The PA function of MDPS is not plugged in (unplugged)." 1 "The PA function of MDPS is plugged in." 2 "RESERVED" 3 "Error Indicator" ;
VAL_ 234 MDPS_PaModeSta 0 "RESERVED" 1 "Steering still in initialization phase" 2 "Steering ready, waits for PA command" 3 "Steering set in standby by PA" 4 "Steering requested to go to first activation step" 5 "Steering requested to go to final activation step" 6 "Steering went to error internally" 7 "Steering aborted the automatic function" 8 "RESERVED" 9 "RESERVED" 10 "RESERVED" 11 "RESERVED" 12 "RESERVED" 13 "RESERVED" 14 "RESERVED" 15 "Error Indicator" ;
VAL_ 234 MDPS_PaCanfltSta 0 "No Failure" 1 "Failure about Pa can message" 2 "RESERVED" 3 "Error Indicator" ;
VAL_ 234 MDPS_LkaPlgInSta 0 "The LKA function of MDPS is not plugged in (unplugged)." 1 "The LKA function of MDPS is plugged in." 2 "RESERVED" 3 "Error Indicator" ;
VAL_ 234 MDPS_LkaToiActvSta 0 "Deactivated" 1 "Activated" 2 "RESERVED" 3 "Error Indicator" ;
VAL_ 234 MDPS_LkaToiUnblSta 0 "Available" 1 "Unavailable" 2 "RESERVED" 3 "Error Indicator" ;
VAL_ 234 MDPS_LkaToiFltSta 0 "No fault" 1 "Faulty" 2 "RESERVED" 3 "Error Indicator" ;
VAL_ 234 MDPS_LkaFailSta 0 "Not in fail state" 1 "In fail state" 2 "RESERVED" 3 "Error Indicator" ;
VAL_ 234 MDPS_ResetOpSta 0 "Normal" 1 "Reset Complete" 2 "Reset Fail" 3 "RESERVED" ;
VAL_ 234 MDPS_CurrModVal 0 "Comfort Mode" 1 "Sport Mode" 2 "Sport+ Mode" 3 "Chauffeur Mode" 4 "Mild Mode" 5 "Drift Mode" 6 "RESERVED" 7 "Error Indicator" ;
VAL_ 234 MDPS_OutTqVal 0 "0x0x000~0xFFD:real values" 4093 "0x0x000~0xFFD:real values" 4094 "RESERVED" 4095 "Error Indicator" ;
VAL_ 234 MDPS_VsmActResp 0 "VSM Control inactivated" 1 "VSM Control Activated" 2 "RESERVED" 3 "Invalid" ;
VAL_ 234 Reprogram_State_MDPS 0 "normal operation" 1 "reprogramming" 2 "RESERVED" 3 "Error Indicator" ;
VAL_ 234 MDPS_StrTqSnsrVal 0 "0x0x000~0x1FFD:real values" 8189 "0x0x000~0x1FFD:real values" 8190 "RESERVED" 8191 "Error Indicator" ;
VAL_ 234 MDPS_PaStrAnglVal 0 "0x0x000~0x7FFD:real values" 32765 "0x0x000~0x7FFD:real values" 32766 "Not Initialized" 32767 "Error Indicator" 32768 "0x8000~0xFFFF:real values" 65535 "0x8000~0xFFFF:real values" ;
VAL_ 813 SBCM_DRV_FD_Crc1Val 0 "0x0x0~0xFFFF:CRCValue" 65535 "0x0x0~0xFFFF:CRCValue" ;
VAL_ 813 SBCM_DRV_FD_AlvCnt1Val 0 "0x0x0~0xFF:AlvCntValue" 255 "0x0x0~0xFF:AlvCntValue" ;
VAL_ 813 Warn_DrvDrSwSta_SBCM 0 "Close" 1 "Open" 2 "RESERVED" 3 "Error Indicator" ;
VAL_ 811 SBCM_AST_FD_Crc1Val 0 "0x0x0~0xFFFF:CRCValue" 65535 "0x0x0~0xFFFF:CRCValue" ;
VAL_ 811 SBCM_AST_FD_AlvCnt1Val 0 "0x0x0~0xFF:AlvCntValue" 255 "0x0x0~0xFF:AlvCntValue" ;
VAL_ 811 Warn_AsstDrSwSta_SBCM 0 "Close" 1 "Open" 2 "RESERVED" 3 "Error Indicator" ;
VAL_ 288 MCU_Crc2Val 0 "0x0x0~0xFFFF:CRCValue" 65535 "0x0x0~0xFFFF:CRCValue" ;
VAL_ 288 MCU_AlvCnt2Val 0 "0x0x0~0xFF:AlvCntValue" 255 "0x0x0~0xFF:AlvCntValue" ;
VAL_ 293 SAS_AnglVal 0 "0x0x0000~0x7FFE:real value" 32766 "0x0x0000~0x7FFE:real value" 32767 "Error Indicator" 32768 "0x8000~0xFFFF:real value" 65535 "0x8000~0xFFFF:real value" ;
VAL_ 293 SAS_SpdVal 0 "0x0x00~0xFE:real value" 254 "0x0x00~0xFE:real value" 255 "Error Indicator" ;
VAL_ 293 SAS_IntSta 0 "real vaule" 1 "real vaule" 2 "real vaule" 3 "real vaule" 4 "real vaule" 5 "real vaule" 6 "real vaule" 7 "real vaule" 8 "real vaule" 9 "real vaule" 10 "real vaule" 11 "real vaule" 12 "real vaule" 13 "real vaule" 14 "real vaule" 15 "real vaule" 16 "0x10~0xFF:RESERVED" 255 "0x10~0xFF:RESERVED" ;
VAL_ 298 ADAS_CMD_Crc30Val 0 "0x0x0~0xFFFF:CRCValue" 65535 "0x0x0~0xFFFF:CRCValue" ;
VAL_ 298 ADAS_Damping_Gain 0 "Reserved" 1 "Reserved" 2 "Reserved" 3 "0x3~0xC8:3 ~ 200%" 200 "0x3~0xC8:3 ~ 200%" 201 "Reserved" 202 "Reserved" 203 "Reserved" 204 "Reserved" 205 "Reserved" 206 "Reserved" 207 "Reserved" 208 "Reserved" 209 "Reserved" 210 "Reserved" 211 "Reserved" 212 "Reserved" 213 "Reserved" 214 "Reserved" 215 "Reserved" 216 "Reserved" 217 "Reserved" 218 "Reserved" 219 "Reserved" 220 "Reserved" 221 "Reserved" 222 "Reserved" 223 "Reserved" 224 "Reserved" 225 "Reserved" 226 "Reserved" 227 "Reserved" 228 "Reserved" 229 "Reserved" 230 "Reserved" 231 "Reserved" 232 "Reserved" 233 "Reserved" 234 "Reserved" 235 "Reserved" 236 "Reserved" 237 "Reserved" 238 "Reserved" 239 "Reserved" 240 "Reserved" 241 "Reserved" 242 "Reserved" 243 "Reserved" 244 "Reserved" 245 "Reserved" 246 "Reserved" 247 "Reserved" 248 "Reserved" 249 "Reserved" 250 "Reserved" 251 "Reserved" 252 "Reserved" 253 "Reserved" 254 "Reserved" 255 "Reserved" ;
VAL_ 298 ADAS_CMD_AlvCnt30Val 0 "0x0x0~0xFF:AlvCntValue" 255 "0x0x0~0xFF:AlvCntValue" ;
VAL_ 298 ADAS_StrTqReqVal 0 "0x0x000~0x7FD:0~2045" 2045 "0x0x000~0x7FD:0~2045" 2046 "Reserved" 2047 "Invalid" ;
VAL_ 298 ADAS_ActToiSta 0 "De-activate TOI" 1 "Activate TOI" 2 "Reserved" 3 "Error indicator" ;
VAL_ 298 ADAS_ToiFltSta 0 "No Fault" 1 "Fault" 2 "Reserved" 3 "Error indicatorr" ;
VAL_ 374 RCU_Crc3Val 0 "0x0x0~0xFFFF:CRCValue" 65535 "0x0x0~0xFFFF:CRCValue" ;
VAL_ 374 RCU_AlvCnt3Val 0 "0x0x0~0xFF:AlvCntValue" 255 "0x0x0~0xFF:AlvCntValue" ;
VAL_ 374 RCU_HDP_EgSta 0 "Not Engaged" 1 "Engaged in main controller by IEB (ESC)" 2 "Engaged in sub controller by IEB (ESC)" 3 "MRM with IEB (ESC) alone" 4 "Engaged in main controller by RCU" 5 "Engaged in sub controller by RCU" 6 "MRM with RCU alone" 7 "Engaged in sub controller by IEB (ESC), but RCU Signal" ;
VAL_ 357 ADAS_PRK_Crc2Val 0 "0x0x0~0xFFFF:CRCValue" 65535 "0x0x0~0xFFFF:CRCValue" ;
VAL_ 357 ADAS_PRK_AlvCnt2Val 0 "0x0x0~0xFF:AlvCntValue" 255 "0x0x0~0xFF:AlvCntValue" ;
VAL_ 357 PA_RSPA_Opt 0 "PA/RSPA not applied" 1 "PA/RSPA applied" 2 "Not Used" 3 "Error Indicator" ;
VAL_ 357 PA_Sta 0 "Reserved" 1 "PA_Init" 2 "PA_NewStart" 3 "PA_Standby" 4 "PA_Active" 5 "PA_Angle_Control_Active" 6 "PA_Failure" 7 "PA_Abort" 8 "Reserved" 9 "Reserved" 10 "Reserved" 11 "Reserved" 12 "Reserved" 13 "Reserved" 14 "Not used" 15 "Error Indicator" ;
VAL_ 357 PA_TestModSta 0 "PA is not in Test Mode" 1 "PA is in Test Mode" 2 "Not used" 3 "Error Indicator" ;
VAL_ 358 CDCU_TPA_Crc1Val 0 "0x0x0~0xFFFF:CRCValue" 65535 "0x0x0~0xFFFF:CRCValue" ;
VAL_ 358 CDCU_TPA_AlvCnt1Val 0 "0x0x0~0xFF:AlvCntValue" 255 "0x0x0~0xFF:AlvCntValue" ;
VAL_ 358 CDCU_TPA_Opt 0 "TPA not applied" 1 "TPA applied" 2 "RESERVED" 3 "Error Indicator" ;
VAL_ 358 CDCU_TPA_Sta 0 "Default" 1 "TPA_Init" 2 "TPA_NewStart" 3 "TPA_Standby" 4 "TPA_Active" 5 "TPA_Angle_Control_Active" 6 "TPA_Failure" 7 "TPA_Abort" 8 "RESERVED" 9 "RESERVED" 10 "RESERVED" 11 "RESERVED" 12 "RESERVED" 13 "RESERVED" 14 "Not used" 15 "Error Indicator" ;
VAL_ 358 CDCU_TPA_StrAnglReq 32767 "Error Indicator" 65535 "Error Indicator" ;
VAL_ 405 HDP_RDD_ACIAnglTqRedcGainVal 0 "0x0x00~0xFA:Real Values" 250 "0x0x00~0xFA:Real Values" 251 "RESERVED" 252 "RESERVED" 253 "RESERVED" 254 "RESERVED" 255 "RESERVED" ;
VAL_ 405 HDP_RDD_ACIFltSta 0 "No Fault" 1 "Fault" 2 "Reserved" 3 "Error indicator" ;
VAL_ 405 HDP_RDD_ACIActvSta 0 "INIT" 1 "INACTIVE" 2 "ACTIVE35(ACTIVE)" 3 "ACTIVE33(Redundancy)" 4 "RESERVED" 5 "RESERVED" 6 "RESERVED" 7 "RESERVED" 8 "RESERVED" 9 "RESERVED" 10 "RESERVED" 11 "RESERVED" 12 "RESERVED" 13 "RESERVED" 14 "RESERVED" 15 "RESERVED" ;
VAL_ 426 CLU_Crc1Val 0 "0x0x0~0xFFFF:CRCValue" 65535 "0x0x0~0xFFFF:CRCValue" ;
VAL_ 426 CLU_AlvCnt1Val 0 "0x0x0~0xFF:AlvCntValue" 255 "0x0x0~0xFF:AlvCntValue" ;
VAL_ 426 CLU_SpdUnitTyp 0 "km/h" 1 "MPH" 2 "Not used" 3 "Error Indicator" ;
VAL_ 426 CLU_DisSpdVal 1023 "Error" ;
VAL_ 901 ICSC_Crc3Val 0 "0x0x0~0xFFFF:CRCValue" 65535 "0x0x0~0xFFFF:CRCValue" ;
VAL_ 901 ICSC_AlvCnt3Val 0 "0x0x0~0xFF:AlvCntValue" 255 "0x0x0~0xFF:AlvCntValue" ;
VAL_ 901 DMIC_OffRdMod 0 "Default" 1 "Snow" 2 "Sand" 3 "Mud" 4 "AWD Lock" 5 "Rock" 6 "RESERVED" 7 "Error Indicator" ;
VAL_ 994 PDC_FD_Crc3Val 0 "0x0x0~0xFFFF:CRCValue" 65535 "0x0x0~0xFFFF:CRCValue" ;
VAL_ 994 PDC_FD_AlvCnt3Val 0 "0x0x0~0xFF:AlvCntValue" 255 "0x0x0~0xFF:AlvCntValue" ;
VAL_ 994 Warn_DrvDrSwSta 0 "Close" 1 "Open" 2 "Not Used" 3 "Error Indicator" ;
VAL_ 994 Warn_AsstDrSwSta 0 "Close" 1 "Open" 2 "Not Used" 3 "Error Indicator" ;
VAL_ 994 DoorLock_DrvDrUnLkSta 0 "Lock" 1 "Unlock" 2 "Not Used" 3 "Error Indicator" ;
VAL_ 2549874807 SNI_ECS 0 "0x0x0~0xFF:NM Source Node ID" 255 "0x0x0~0xFF:NM Source Node ID" ;
VAL_ 2549874807 CBV_RMR_ECS 0 "Repeat Message State not requested" 1 "Repeat Message State requested" ;
VAL_ 2549874807 CBV_NMCoID_ECS 0 "NM Coordinator ID" 1 "NM Coordinator ID" 2 "NM Coordinator ID" 3 "NM Coordinator ID" ;
VAL_ 2549874807 CBV_NMCoSRB_ECS 0 "Start of synchronized shutdown is not requested by main coordinator" 1 "Start of synchronized shutdown is requested by main coordinator" ;
VAL_ 2549874807 CBV_AWB_ECS 0 "Node has not woken up the network (passive wakeup)" 1 "Node has woken up the network (active wakeup)" ;
VAL_ 2549874807 CBV_PNIB_ECS 0 "NM PDU contains no partial network cluster information in the user data area" 1 "NM PDU contains partial network cluster information in the user data area" ;
VAL_ 2549874807 NRR_ECS 0 "Default" 1 "0x1~0xFF:RESERVED" 255 "0x1~0xFF:RESERVED" ;
VAL_ 2549874807 NM_State_ECS 0 "Default" 1 "NM_RMS_BSM" 2 "NM_RMS_PBSM" 3 "RESERVED" 4 "NM_NS_RMS" 5 "RESERVED" 6 "RESERVED" 7 "RESERVED" 8 "NM_NS_RSS" 9 "RESERVED" 10 "RESERVED" 11 "RESERVED" 12 "RESERVED" 13 "RESERVED" 14 "RESERVED" 15 "RESERVED" 16 "NM_RMS_RSS" 17 "RESERVED" 18 "RESERVED" 19 "RESERVED" 20 "RESERVED" 21 "RESERVED" 22 "RESERVED" 23 "RESERVED" 24 "RESERVED" 25 "RESERVED" 26 "RESERVED" 27 "RESERVED" 28 "RESERVED" 29 "RESERVED" 30 "RESERVED" 31 "RESERVED" 32 "NM_RMS_NS" 33 "0x21~0xFF:RESERVED" 255 "0x21~0xFF:RESERVED" ;
VAL_ 2549874807 PNI_ECS 0 "0x0x0~0xFFFFFFFF:NM PNC Bit" 2147483647 "0x0x0~0xFFFFFFFF:NM PNC Bit" ;
VAL_ 2549874807 PNI_ECS_1 0 "0x0~0xFFFFFFFFFFFFFFFF:NM PNC Bit" ;
VAL_ 2549874807 PNI_ECS_2 0 "0x0~0xFFFFFFFFFFFFFFFF:NM PNC Bit" ;
VAL_ 2549874807 PNI_ECS_3 0 "0x0~0xFFFFFFFFFFFFFFFF:NM PNC Bit" ;
VAL_ 2549874769 SNI_RCU 0 "0x0x0~0xFF:NM Source Node ID" 255 "0x0x0~0xFF:NM Source Node ID" ;
VAL_ 2549874769 CBV_RMR_RCU 0 "Repeat Message State not requested" 1 "Repeat Message State requested" ;
VAL_ 2549874769 CBV_NMCoID_RCU 0 "NM Coordinator ID" 1 "NM Coordinator ID" 2 "NM Coordinator ID" 3 "NM Coordinator ID" ;
VAL_ 2549874769 CBV_NMCoSRB_RCU 0 "Start of synchronized shutdown is not requested by main coordinator" 1 "Start of synchronized shutdown is requested by main coordinator" ;
VAL_ 2549874769 CBV_AWB_RCU 0 "Node has not woken up the network (passive wakeup)" 1 "Node has woken up the network (active wakeup)" ;
VAL_ 2549874769 CBV_PNIB_RCU 0 "NM PDU contains no partial network cluster information in the user data area" 1 "NM PDU contains partial network cluster information in the user data area" ;
VAL_ 2549874769 NRR_RCU 0 "Default" 1 "0x1~0xFF:RESERVED" 255 "0x1~0xFF:RESERVED" ;
VAL_ 2549874769 NM_State_RCU 0 "Default" 1 "NM_RMS_BSM" 2 "NM_RMS_PBSM" 3 "RESERVED" 4 "NM_NS_RMS" 5 "RESERVED" 6 "RESERVED" 7 "RESERVED" 8 "NM_NS_RSS" 9 "RESERVED" 10 "RESERVED" 11 "RESERVED" 12 "RESERVED" 13 "RESERVED" 14 "RESERVED" 15 "RESERVED" 16 "NM_RMS_RSS" 17 "RESERVED" 18 "RESERVED" 19 "RESERVED" 20 "RESERVED" 21 "RESERVED" 22 "RESERVED" 23 "RESERVED" 24 "RESERVED" 25 "RESERVED" 26 "RESERVED" 27 "RESERVED" 28 "RESERVED" 29 "RESERVED" 30 "RESERVED" 31 "RESERVED" 32 "NM_RMS_NS" 33 "0x21~0xFF:RESERVED" 255 "0x21~0xFF:RESERVED" ;
VAL_ 2549874769 PNI_RCU 0 "0x0x0~0xFFFFFFFF:NM PNC Bit" 2147483647 "0x0x0~0xFFFFFFFF:NM PNC Bit" ;
VAL_ 2549874769 PNI_RCU_1 0 "0x0~0xFFFFFFFFFFFFFFFF:NM PNC Bit" ;
VAL_ 2549874769 PNI_RCU_2 0 "0x0~0xFFFFFFFFFFFFFFFF:NM PNC Bit" ;
VAL_ 2549874769 PNI_RCU_3 0 "0x0~0xFFFFFFFFFFFFFFFF:NM PNC Bit" ;
VAL_ 2549874805 SNI_ESC 0 "0x0x0~0xFF:NM Source Node ID" 255 "0x0x0~0xFF:NM Source Node ID" ;
VAL_ 2549874805 CBV_RMR_ESC 0 "Repeat Message State not requested" 1 "Repeat Message State requested" ;
VAL_ 2549874805 CBV_NMCoID_ESC 0 "NM Coordinator ID" 1 "NM Coordinator ID" 2 "NM Coordinator ID" 3 "NM Coordinator ID" ;
VAL_ 2549874805 CBV_NMCoSRB_ESC 0 "Start of synchronized shutdown is not requested by main coordinator" 1 "Start of synchronized shutdown is requested by main coordinator" ;
VAL_ 2549874805 CBV_AWB_ESC 0 "Node has not woken up the network (passive wakeup)" 1 "Node has woken up the network (active wakeup)" ;
VAL_ 2549874805 CBV_PNIB_ESC 0 "NM PDU contains no partial network cluster information in the user data area" 1 "NM PDU contains partial network cluster information in the user data area" ;
VAL_ 2549874805 NRR_ESC 0 "Default" 1 "0x1~0xFF:RESERVED" 255 "0x1~0xFF:RESERVED" ;
VAL_ 2549874805 NM_State_ESC 0 "Default" 1 "NM_RMS_BSM" 2 "NM_RMS_PBSM" 3 "RESERVED" 4 "NM_NS_RMS" 5 "RESERVED" 6 "RESERVED" 7 "RESERVED" 8 "NM_NS_RSS" 9 "RESERVED" 10 "RESERVED" 11 "RESERVED" 12 "RESERVED" 13 "RESERVED" 14 "RESERVED" 15 "RESERVED" 16 "NM_RMS_RSS" 17 "RESERVED" 18 "RESERVED" 19 "RESERVED" 20 "RESERVED" 21 "RESERVED" 22 "RESERVED" 23 "RESERVED" 24 "RESERVED" 25 "RESERVED" 26 "RESERVED" 27 "RESERVED" 28 "RESERVED" 29 "RESERVED" 30 "RESERVED" 31 "RESERVED" 32 "NM_RMS_NS" 33 "0x21~0xFF:RESERVED" 255 "0x21~0xFF:RESERVED" ;
VAL_ 2549874805 PNI_ESC 0 "0x0x0~0xFFFFFFFF:NM PNC Bit" 2147483647 "0x0x0~0xFFFFFFFF:NM PNC Bit" ;
VAL_ 2549874805 PNI_ESC_1 0 "0x0~0xFFFFFFFFFFFFFFFF:NM PNC Bit" ;
VAL_ 2549874805 PNI_ESC_2 0 "0x0~0xFFFFFFFFFFFFFFFF:NM PNC Bit" ;
VAL_ 2549874805 PNI_ESC_3 0 "0x0~0xFFFFFFFFFFFFFFFF:NM PNC Bit" ;
VAL_ 2549874809 SNI_RWS 0 "0x0x0~0xFF:NM Source Node ID" 255 "0x0x0~0xFF:NM Source Node ID" ;
VAL_ 2549874809 CBV_RMR_RWS 0 "Repeat Message State not requested" 1 "Repeat Message State requested" ;
VAL_ 2549874809 CBV_NMCoID_RWS 0 "NM Coordinator ID" 1 "NM Coordinator ID" 2 "NM Coordinator ID" 3 "NM Coordinator ID" ;
VAL_ 2549874809 CBV_NMCoSRB_RWS 0 "Start of synchronized shutdown is not requested by main coordinator" 1 "Start of synchronized shutdown is requested by main coordinator" ;
VAL_ 2549874809 CBV_AWB_RWS 0 "Node has not woken up the network (passive wakeup)" 1 "Node has woken up the network (active wakeup)" ;
VAL_ 2549874809 CBV_PNIB_RWS 0 "NM PDU contains no partial network cluster information in the user data area" 1 "NM PDU contains partial network cluster information in the user data area" ;
VAL_ 2549874809 NRR_RWS 0 "Default" 1 "0x1~0xFF:RESERVED" 255 "0x1~0xFF:RESERVED" ;
VAL_ 2549874809 NM_State_RWS 0 "Default" 1 "NM_RMS_BSM" 2 "NM_RMS_PBSM" 3 "RESERVED" 4 "NM_NS_RMS" 5 "RESERVED" 6 "RESERVED" 7 "RESERVED" 8 "NM_NS_RSS" 9 "RESERVED" 10 "RESERVED" 11 "RESERVED" 12 "RESERVED" 13 "RESERVED" 14 "RESERVED" 15 "RESERVED" 16 "NM_RMS_RSS" 17 "RESERVED" 18 "RESERVED" 19 "RESERVED" 20 "RESERVED" 21 "RESERVED" 22 "RESERVED" 23 "RESERVED" 24 "RESERVED" 25 "RESERVED" 26 "RESERVED" 27 "RESERVED" 28 "RESERVED" 29 "RESERVED" 30 "RESERVED" 31 "RESERVED" 32 "NM_RMS_NS" 33 "0x21~0xFF:RESERVED" 255 "0x21~0xFF:RESERVED" ;
VAL_ 2549874809 PNI_RWS 0 "0x0x0~0xFFFFFFFF:NM PNC Bit" 2147483647 "0x0x0~0xFFFFFFFF:NM PNC Bit" ;
VAL_ 2549874809 PNI_RWS_1 0 "0x0~0xFFFFFFFFFFFFFFFF:NM PNC Bit" ;
VAL_ 2549874809 PNI_RWS_2 0 "0x0~0xFFFFFFFFFFFFFFFF:NM PNC Bit" ;
VAL_ 2549874809 PNI_RWS_3 0 "0x0~0xFFFFFFFFFFFFFFFF:NM PNC Bit" ;
VAL_ 2549874751 SNI_GW_RGW 0 "0x0x0~0xFF:NM Source Node ID" 255 "0x0x0~0xFF:NM Source Node ID" ;
VAL_ 2549874751 CBV_RMR_GW_RGW 0 "Repeat Message State not requested" 1 "Repeat Message State requested" ;
VAL_ 2549874751 CBV_NMCoID_GW_RGW 0 "NM Coordinator ID" 1 "NM Coordinator ID" 2 "NM Coordinator ID" 3 "NM Coordinator ID" ;
VAL_ 2549874751 CBV_NMCoSRB_GW_RGW 0 "Start of synchronized shutdown is not requested by main coordinator" 1 "Start of synchronized shutdown is requested by main coordinator" ;
VAL_ 2549874751 CBV_AWB_GW_RGW 0 "Node has not woken up the network (passive wakeup)" 1 "Node has woken up the network (active wakeup)" ;
VAL_ 2549874751 CBV_PNIB_GW_RGW 0 "NM PDU contains no partial network cluster information in the user data area" 1 "NM PDU contains partial network cluster information in the user data area" ;
VAL_ 2549874751 NRR_GW_RGW 0 "Default" 1 "0x1~0xFF:RESERVED" 255 "0x1~0xFF:RESERVED" ;
VAL_ 2549874751 NM_State_GW_RGW 0 "Default" 1 "NM_RMS_BSM" 2 "NM_RMS_PBSM" 3 "RESERVED" 4 "NM_NS_RMS" 5 "RESERVED" 6 "RESERVED" 7 "RESERVED" 8 "NM_NS_RSS" 9 "RESERVED" 10 "RESERVED" 11 "RESERVED" 12 "RESERVED" 13 "RESERVED" 14 "RESERVED" 15 "RESERVED" 16 "NM_RMS_RSS" 17 "RESERVED" 18 "RESERVED" 19 "RESERVED" 20 "RESERVED" 21 "RESERVED" 22 "RESERVED" 23 "RESERVED" 24 "RESERVED" 25 "RESERVED" 26 "RESERVED" 27 "RESERVED" 28 "RESERVED" 29 "RESERVED" 30 "RESERVED" 31 "RESERVED" 32 "NM_RMS_NS" 33 "0x21~0xFF:RESERVED" 255 "0x21~0xFF:RESERVED" ;
VAL_ 2549874751 PNI_GW_RGW 0 "0x0x0~0xFFFFFFFF:NM PNC Bit" 2147483647 "0x0x0~0xFFFFFFFF:NM PNC Bit" ;
VAL_ 2549874751 PNI_GW_RGW_1 0 "0x0~0xFFFFFFFFFFFFFFFF:NM PNC Bit" ;
VAL_ 2549874751 PNI_GW_RGW_2 0 "0x0~0xFFFFFFFFFFFFFFFF:NM PNC Bit" ;
VAL_ 2549874751 PNI_GW_RGW_3 0 "0x0~0xFFFFFFFFFFFFFFFF:NM PNC Bit" ;
VAL_ 2549874786 SNI_EBB 0 "0x0x0~0xFF:NM Source Node ID" 255 "0x0x0~0xFF:NM Source Node ID" ;
VAL_ 2549874786 CBV_RMR_EBB 0 "Repeat Message State not requested" 1 "Repeat Message State requested" ;
VAL_ 2549874786 CBV_NMCoID_EBB 0 "NM Coordinator ID" 1 "NM Coordinator ID" 2 "NM Coordinator ID" 3 "NM Coordinator ID" ;
VAL_ 2549874786 CBV_NMCoSRB_EBB 0 "Start of synchronized shutdown is not requested by main coordinator" 1 "Start of synchronized shutdown is requested by main coordinator" ;
VAL_ 2549874786 CBV_AWB_EBB 0 "Node has not woken up the network (passive wakeup)" 1 "Node has woken up the network (active wakeup)" ;
VAL_ 2549874786 CBV_PNIB_EBB 0 "NM PDU contains no partial network cluster information in the user data area" 1 "NM PDU contains partial network cluster information in the user data area" ;
VAL_ 2549874786 NRR_EBB 0 "Default" 1 "0x1~0xFF:RESERVED" 255 "0x1~0xFF:RESERVED" ;
VAL_ 2549874786 NM_State_EBB 0 "Default" 1 "NM_RMS_BSM" 2 "NM_RMS_PBSM" 3 "RESERVED" 4 "NM_NS_RMS" 5 "RESERVED" 6 "RESERVED" 7 "RESERVED" 8 "NM_NS_RSS" 9 "RESERVED" 10 "RESERVED" 11 "RESERVED" 12 "RESERVED" 13 "RESERVED" 14 "RESERVED" 15 "RESERVED" 16 "NM_RMS_RSS" 17 "RESERVED" 18 "RESERVED" 19 "RESERVED" 20 "RESERVED" 21 "RESERVED" 22 "RESERVED" 23 "RESERVED" 24 "RESERVED" 25 "RESERVED" 26 "RESERVED" 27 "RESERVED" 28 "RESERVED" 29 "RESERVED" 30 "RESERVED" 31 "RESERVED" 32 "NM_RMS_NS" 33 "0x21~0xFF:RESERVED" 255 "0x21~0xFF:RESERVED" ;
VAL_ 2549874786 PNI_EBB 0 "0x0x0~0xFFFFFFFF:NM PNC Bit" 2147483647 "0x0x0~0xFFFFFFFF:NM PNC Bit" ;
VAL_ 2549874786 PNI_EBB_1 0 "0x0~0xFFFFFFFFFFFFFFFF:NM PNC Bit" ;
VAL_ 2549874786 PNI_EBB_2 0 "0x0~0xFFFFFFFFFFFFFFFF:NM PNC Bit" ;
VAL_ 2549874786 PNI_EBB_3 0 "0x0~0xFFFFFFFFFFFFFFFF:NM PNC Bit" ;
VAL_ 2549874800 SNI_CGW_CCU 0 "0x0x0~0xFF:NM Source Node ID" 255 "0x0x0~0xFF:NM Source Node ID" ;
VAL_ 2549874800 CBV_RMR_CGW_CCU 0 "Repeat Message State not requested" 1 "Repeat Message State requested" ;
VAL_ 2549874800 CBV_NMCoID_CGW_CCU 0 "NM Coordinator ID" 1 "NM Coordinator ID" 2 "NM Coordinator ID" 3 "NM Coordinator ID" ;
VAL_ 2549874800 CBV_NMCoSRB_CGW_CCU 0 "Start of synchronized shutdown is not requested by main coordinator" 1 "Start of synchronized shutdown is requested by main coordinator" ;
VAL_ 2549874800 CBV_AWB_CGW_CCU 0 "Node has not woken up the network (passive wakeup)" 1 "Node has woken up the network (active wakeup)" ;
VAL_ 2549874800 CBV_PNIB_CGW_CCU 0 "NM PDU contains no partial network cluster information in the user data area" 1 "NM PDU contains partial network cluster information in the user data area" ;
VAL_ 2549874800 NRR_CGW_CCU 0 "Default" 1 "0x1~0xFF:RESERVED" 255 "0x1~0xFF:RESERVED" ;
VAL_ 2549874800 NM_State_CGW_CCU 0 "Default" 1 "NM_RMS_BSM" 2 "NM_RMS_PBSM" 3 "RESERVED" 4 "NM_NS_RMS" 5 "RESERVED" 6 "RESERVED" 7 "RESERVED" 8 "NM_NS_RSS" 9 "RESERVED" 10 "RESERVED" 11 "RESERVED" 12 "RESERVED" 13 "RESERVED" 14 "RESERVED" 15 "RESERVED" 16 "NM_RMS_RSS" 17 "RESERVED" 18 "RESERVED" 19 "RESERVED" 20 "RESERVED" 21 "RESERVED" 22 "RESERVED" 23 "RESERVED" 24 "RESERVED" 25 "RESERVED" 26 "RESERVED" 27 "RESERVED" 28 "RESERVED" 29 "RESERVED" 30 "RESERVED" 31 "RESERVED" 32 "NM_RMS_NS" 33 "0x21~0xFF:RESERVED" 255 "0x21~0xFF:RESERVED" ;
VAL_ 2549874800 PNI_CGW_CCU 0 "0x0x0~0xFFFFFFFF:NM PNC Bit" 2147483647 "0x0x0~0xFFFFFFFF:NM PNC Bit" ;
VAL_ 2549874800 PNI_CGW_CCU_1 0 "0x0~0xFFFFFFFFFFFFFFFF:NM PNC Bit" ;
VAL_ 2549874800 PNI_CGW_CCU_2 0 "0x0~0xFFFFFFFFFFFFFFFF:NM PNC Bit" ;
VAL_ 2549874800 PNI_CGW_CCU_3 0 "0x0~0xFFFFFFFFFFFFFFFF:NM PNC Bit" ;
VAL_ 2549874806 SNI_MDPS 0 "0x0x0~0xFF:NM Source Node ID" 255 "0x0x0~0xFF:NM Source Node ID" ;
VAL_ 2549874806 CBV_RMR_MDPS 0 "Repeat Message State not requested" 1 "Repeat Message State requested" ;
VAL_ 2549874806 CBV_NMCoID_MDPS 0 "NM Coordinator ID" 1 "NM Coordinator ID" 2 "NM Coordinator ID" 3 "NM Coordinator ID" ;
VAL_ 2549874806 CBV_NMCoSRB_MDPS 0 "Start of synchronized shutdown is not requested by main coordinator" 1 "Start of synchronized shutdown is requested by main coordinator" ;
VAL_ 2549874806 CBV_AWB_MDPS 0 "Node has not woken up the network (passive wakeup)" 1 "Node has woken up the network (active wakeup)" ;
VAL_ 2549874806 CBV_PNIB_MDPS 0 "NM PDU contains no partial network cluster information in the user data area" 1 "NM PDU contains partial network cluster information in the user data area" ;
VAL_ 2549874806 NRR_MDPS 0 "Default" 1 "0x1~0xFF:RESERVED" 255 "0x1~0xFF:RESERVED" ;
VAL_ 2549874806 NM_State_MDPS 0 "Default" 1 "NM_RMS_BSM" 2 "NM_RMS_PBSM" 3 "RESERVED" 4 "NM_NS_RMS" 5 "RESERVED" 6 "RESERVED" 7 "RESERVED" 8 "NM_NS_RSS" 9 "RESERVED" 10 "RESERVED" 11 "RESERVED" 12 "RESERVED" 13 "RESERVED" 14 "RESERVED" 15 "RESERVED" 16 "NM_RMS_RSS" 17 "RESERVED" 18 "RESERVED" 19 "RESERVED" 20 "RESERVED" 21 "RESERVED" 22 "RESERVED" 23 "RESERVED" 24 "RESERVED" 25 "RESERVED" 26 "RESERVED" 27 "RESERVED" 28 "RESERVED" 29 "RESERVED" 30 "RESERVED" 31 "RESERVED" 32 "NM_RMS_NS" 33 "0x21~0xFF:RESERVED" 255 "0x21~0xFF:RESERVED" ;
VAL_ 2549874806 PNI_MDPS 0 "0x0x0~0xFFFFFFFF:NM PNC Bit" 2147483647 "0x0x0~0xFFFFFFFF:NM PNC Bit" ;
VAL_ 2549874806 PNI_MDPS_1 0 "0x0~0xFFFFFFFFFFFFFFFF:NM PNC Bit" ;
VAL_ 2549874806 PNI_MDPS_2 0 "0x0~0xFFFFFFFFFFFFFFFF:NM PNC Bit" ;
VAL_ 2549874806 PNI_MDPS_3 0 "0x0~0xFFFFFFFFFFFFFFFF:NM PNC Bit" ;
VAL_ 2549874762 SNI_RWA 0 "0x0x0~0xFF:NM Source Node ID" 255 "0x0x0~0xFF:NM Source Node ID" ;
VAL_ 2549874762 CBV_RMR_RWA 0 "Repeat Message State not requested" 1 "Repeat Message State requested" ;
VAL_ 2549874762 CBV_NMCoID_RWA 0 "NM Coordinator ID" 1 "NM Coordinator ID" 2 "NM Coordinator ID" 3 "NM Coordinator ID" ;
VAL_ 2549874762 CBV_NMCoSRB_RWA 0 "Start of synchronized shutdown is not requested by main coordinator" 1 "Start of synchronized shutdown is requested by main coordinator" ;
VAL_ 2549874762 CBV_AWB_RWA 0 "Node has not woken up the network (passive wakeup)" 1 "Node has woken up the network (active wakeup)" ;
VAL_ 2549874762 CBV_PNIB_RWA 0 "NM PDU contains no partial network cluster information in the user data area" 1 "NM PDU contains partial network cluster information in the user data area" ;
VAL_ 2549874762 NRR_RWA 0 "Default" 1 "0x1~0xFF:RESERVED" 255 "0x1~0xFF:RESERVED" ;
VAL_ 2549874762 NM_State_RWA 0 "Default" 1 "NM_RMS_BSM" 2 "NM_RMS_PBSM" 3 "RESERVED" 4 "NM_NS_RMS" 5 "RESERVED" 6 "RESERVED" 7 "RESERVED" 8 "NM_NS_RSS" 9 "RESERVED" 10 "RESERVED" 11 "RESERVED" 12 "RESERVED" 13 "RESERVED" 14 "RESERVED" 15 "RESERVED" 16 "NM_RMS_RSS" 17 "RESERVED" 18 "RESERVED" 19 "RESERVED" 20 "RESERVED" 21 "RESERVED" 22 "RESERVED" 23 "RESERVED" 24 "RESERVED" 25 "RESERVED" 26 "RESERVED" 27 "RESERVED" 28 "RESERVED" 29 "RESERVED" 30 "RESERVED" 31 "RESERVED" 32 "NM_RMS_NS" 33 "0x21~0xFF:RESERVED" 255 "0x21~0xFF:RESERVED" ;
VAL_ 2549874762 PNI_RWA 0 "0x0x0~0xFFFFFFFF:NM PNC Bit" 2147483647 "0x0x0~0xFFFFFFFF:NM PNC Bit" ;
VAL_ 2549874762 PNI_RWA_1 0 "0x0~0xFFFFFFFFFFFFFFFF:NM PNC Bit" ;
VAL_ 2549874762 PNI_RWA_2 0 "0x0~0xFFFFFFFFFFFFFFFF:NM PNC Bit" ;
VAL_ 2549874762 PNI_RWA_3 0 "0x0~0xFFFFFFFFFFFFFFFF:NM PNC Bit" ;
VAL_ 2549874746 SNI_SFA 0 "0x0x0~0xFF:NM Source Node ID" 255 "0x0x0~0xFF:NM Source Node ID" ;
VAL_ 2549874746 CBV_RMR_SFA 0 "Repeat Message State not requested" 1 "Repeat Message State requested" ;
VAL_ 2549874746 CBV_NMCoID_SFA 0 "NM Coordinator ID" 1 "NM Coordinator ID" 2 "NM Coordinator ID" 3 "NM Coordinator ID" ;
VAL_ 2549874746 CBV_NMCoSRB_SFA 0 "Start of synchronized shutdown is not requested by main coordinator" 1 "Start of synchronized shutdown is requested by main coordinator" ;
VAL_ 2549874746 CBV_AWB_SFA 0 "Node has not woken up the network (passive wakeup)" 1 "Node has woken up the network (active wakeup)" ;
VAL_ 2549874746 CBV_PNIB_SFA 0 "NM PDU contains no partial network cluster information in the user data area" 1 "NM PDU contains partial network cluster information in the user data area" ;
VAL_ 2549874746 NRR_SFA 0 "Default" 1 "0x1~0xFF:RESERVED" 255 "0x1~0xFF:RESERVED" ;
VAL_ 2549874746 NM_State_SFA 0 "Default" 1 "NM_RMS_BSM" 2 "NM_RMS_PBSM" 3 "RESERVED" 4 "NM_NS_RMS" 5 "RESERVED" 6 "RESERVED" 7 "RESERVED" 8 "NM_NS_RSS" 9 "RESERVED" 10 "RESERVED" 11 "RESERVED" 12 "RESERVED" 13 "RESERVED" 14 "RESERVED" 15 "RESERVED" 16 "NM_RMS_RSS" 17 "RESERVED" 18 "RESERVED" 19 "RESERVED" 20 "RESERVED" 21 "RESERVED" 22 "RESERVED" 23 "RESERVED" 24 "RESERVED" 25 "RESERVED" 26 "RESERVED" 27 "RESERVED" 28 "RESERVED" 29 "RESERVED" 30 "RESERVED" 31 "RESERVED" 32 "NM_RMS_NS" 33 "0x21~0xFF:RESERVED" 255 "0x21~0xFF:RESERVED" ;
VAL_ 2549874746 PNI_SFA 0 "0x0x0~0xFFFFFFFF:NM PNC Bit" 2147483647 "0x0x0~0xFFFFFFFF:NM PNC Bit" ;
VAL_ 2549874746 PNI_SFA_1 0 "0x0~0xFFFFFFFFFFFFFFFF:NM PNC Bit" ;
VAL_ 2549874746 PNI_SFA_2 0 "0x0~0xFFFFFFFFFFFFFFFF:NM PNC Bit" ;
VAL_ 2549874746 PNI_SFA_3 0 "0x0~0xFFFFFFFFFFFFFFFF:NM PNC Bit" ;
